VERSION ""

NS_ :

BS_:

BU_: L_3HKBD L_DIG L_FHPTC L_ATCU L_2HKBD L_PCM L_ATCU_vMON L_EVNT L_HKBD L_RHPTC

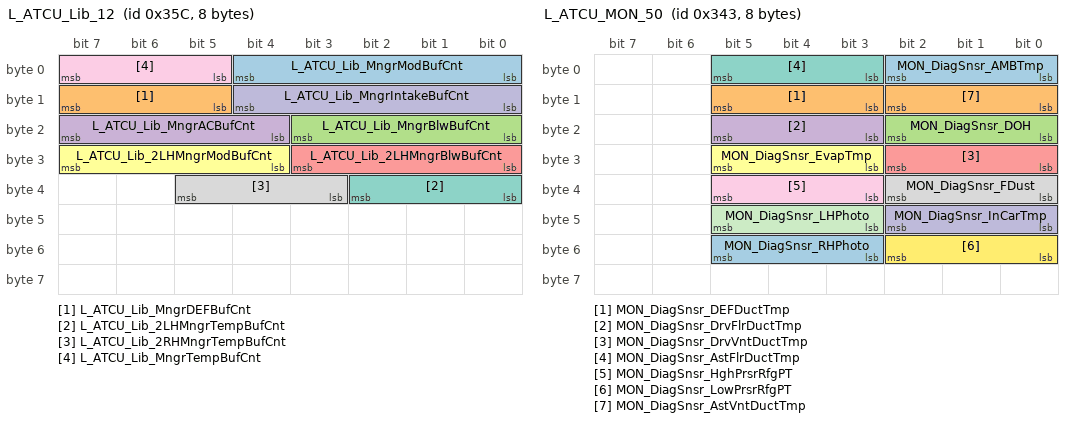
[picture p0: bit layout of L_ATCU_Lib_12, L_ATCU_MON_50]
BO_ 860 L_ATCU_Lib_12: 8 L_ATCU
 SG_ L_ATCU_Lib_MngrModBufCnt : 0|5@1+ (1,0) [0|31] ""  L_ATCU_vMON
 SG_ L_ATCU_Lib_MngrDEFBufCnt : 13|3@1+ (1,0) [0|7] ""  L_ATCU_vMON
 SG_ L_ATCU_Lib_MngrBlwBufCnt : 16|4@1+ (1,0) [0|15] ""  L_ATCU_vMON
 SG_ L_ATCU_Lib_MngrACBufCnt : 20|4@1+ (1,0) [0|15] ""  L_ATCU_vMON
 SG_ L_ATCU_Lib_2LHMngrBlwBufCnt : 24|4@1+ (1,0) [0|15] ""  L_ATCU_vMON
 SG_ L_ATCU_Lib_2LHMngrModBufCnt : 28|4@1+ (1,0) [0|15] ""  L_ATCU_vMON
 SG_ L_ATCU_Lib_2LHMngrTempBufCnt : 32|3@1+ (1,0) [0|7] ""  L_ATCU_vMON
 SG_ L_ATCU_Lib_2RHMngrTempBufCnt : 35|3@1+ (1,0) [0|7] ""  L_ATCU_vMON
 SG_ L_ATCU_Lib_MngrTempBufCnt : 5|3@1+ (1,0) [0|7] ""  L_ATCU_vMON
 SG_ L_ATCU_Lib_MngrIntakeBufCnt : 8|5@1+ (1,0) [0|31] ""  L_ATCU_vMON

BO_ 834 L_ATCU_MON_49: 8 L_ATCU_vMON
 SG_ MON_DiagCOM_AcnOpPerm : 0|2@1+ (1,0) [0|0] ""  L_ATCU
 SG_ MON_DiagCOM_BMSTmout : 10|2@1+ (1,0) [0|0] ""  L_ATCU
 SG_ MON_DiagCOM_DrvClHtStOpt : 12|2@1+ (1,0) [0|0] ""  L_ATCU
 SG_ MON_DiagCOM_AstClHtStOpt : 14|2@1+ (1,0) [0|0] ""  L_ATCU
 SG_ MON_DiagCOM_EcoModSw : 16|2@1+ (1,0) [0|0] ""  L_ATCU
 SG_ MON_DiagCOM_EcompTmout : 18|2@1+ (1,0) [0|0] ""  L_ATCU
 SG_ MON_DiagCOM_APT : 2|2@1+ (1,0) [0|0] ""  L_ATCU
 SG_ MON_DiagCOM_EMSVehSpd : 20|2@1+ (1,0) [0|0] ""  L_ATCU
 SG_ MON_DiagCOM_EngCool : 22|2@1+ (1,0) [0|0] ""  L_ATCU
 SG_ MON_DiagCOM_EngOpMod : 24|2@1+ (1,0) [0|0] ""  L_ATCU
 SG_ MON_DiagCOM_HEVRdy : 26|2@1+ (1,0) [0|0] ""  L_ATCU
 SG_ MON_DiagCOM_HVPTCTmout : 28|2@1+ (1,0) [0|0] ""  L_ATCU
 SG_ MON_DiagCOM_LDCWatt : 30|2@1+ (1,0) [0|0] ""  L_ATCU
 SG_ MON_DiagCOM_LHPhoto : 32|2@1+ (1,0) [0|0] ""  L_ATCU
 SG_ MON_DiagCOM_MainRlyOnSta : 34|2@1+ (1,0) [0|0] ""  L_ATCU
 SG_ MON_DiagCOM_MCUTmout : 36|2@1+ (1,0) [0|0] ""  L_ATCU
 SG_ MON_DiagCOM_PMSnsr : 38|2@1+ (1,0) [0|0] ""  L_ATCU
 SG_ MON_DiagCOM_BatChlrEXVDiag : 4|2@1+ (1,0) [0|0] ""  L_ATCU
 SG_ MON_DiagCOM_PnlBusOff : 40|2@1+ (1,0) [0|0] ""  L_ATCU
 SG_ MON_DiagCOM_PTGOpt : 42|2@1+ (1,0) [0|0] ""  L_ATCU
 SG_ MON_DiagCOM_RHPhoto : 44|2@1+ (1,0) [0|0] ""  L_ATCU
 SG_ MON_DiagCOM_RPM : 46|2@1+ (1,0) [0|0] ""  L_ATCU
 SG_ MON_DiagCOM_SideMirAmb : 48|2@1+ (1,0) [0|0] ""  L_ATCU
 SG_ MON_DiagCOM_ServiceMod : 50|2@1+ (1,0) [0|0] ""  L_ATCU
 SG_ MON_DiagCOM_StrHtOpt : 52|2@1+ (1,0) [0|0] ""  L_ATCU
 SG_ MON_DiagCOM_TCUVehSpd : 54|2@1+ (1,0) [0|0] ""  L_ATCU
 SG_ MON_DiagCOM_Torque : 56|2@1+ (1,0) [0|0] ""  L_ATCU
 SG_ MON_DiagCOM_VehBusOff : 58|2@1+ (1,0) [0|0] ""  L_ATCU
 SG_ MON_DiagCOM_BATSoc : 6|2@1+ (1,0) [0|0] ""  L_ATCU
 SG_ MON_DiagCOM_WhlSpd : 60|2@1+ (1,0) [0|0] ""  L_ATCU
 SG_ MON_DiagCOM_ClmtBusOff : 62|2@1+ (1,0) [0|0] ""  L_ATCU
 SG_ MON_DiagCOM_BMSIntakeReq : 8|2@1+ (1,0) [0|0] ""  L_ATCU

BO_ 835 L_ATCU_MON_50: 8 L_ATCU_vMON
 SG_ MON_DiagSnsr_AMBTmp : 0|3@1+ (1,0) [0|0] ""  L_ATCU
 SG_ MON_DiagSnsr_DEFDuctTmp : 11|3@1+ (1,0) [0|0] ""  L_ATCU
 SG_ MON_DiagSnsr_DOH : 16|3@1+ (1,0) [0|0] ""  L_ATCU
 SG_ MON_DiagSnsr_DrvFlrDuctTmp : 19|3@1+ (1,0) [0|0] ""  L_ATCU
 SG_ MON_DiagSnsr_DrvVntDuctTmp : 24|3@1+ (1,0) [0|0] ""  L_ATCU
 SG_ MON_DiagSnsr_EvapTmp : 27|3@1+ (1,0) [0|0] ""  L_ATCU
 SG_ MON_DiagSnsr_AstFlrDuctTmp : 3|3@1+ (1,0) [0|0] ""  L_ATCU
 SG_ MON_DiagSnsr_FDust : 32|3@1+ (1,0) [0|0] ""  L_ATCU
 SG_ MON_DiagSnsr_HghPrsrRfgPT : 35|3@1+ (1,0) [0|0] ""  L_ATCU
 SG_ MON_DiagSnsr_InCarTmp : 40|3@1+ (1,0) [0|0] ""  L_ATCU
 SG_ MON_DiagSnsr_LHPhoto : 43|3@1+ (1,0) [0|0] ""  L_ATCU
 SG_ MON_DiagSnsr_LowPrsrRfgPT : 48|3@1+ (1,0) [0|0] ""  L_ATCU
 SG_ MON_DiagSnsr_RHPhoto : 51|3@1+ (1,0) [0|0] ""  L_ATCU
 SG_ MON_DiagSnsr_AstVntDuctTmp : 8|3@1+ (1,0) [0|0] ""  L_ATCU

BO_ 833 L_ATCU_MON_48: 8 L_ATCU_vMON
 SG_ MON_DiagAct_DrvModDrLck : 0|2@1+ (1,0) [0|0] ""  L_ATCU
 SG_ MON_DiagAct_AstModDrOpnSrt : 10|3@1+ (1,0) [0|0] ""  L_ATCU
 SG_ MON_DiagAct_AstTmpDrOpnSrt : 13|3@1+ (1,0) [0|0] ""  L_ATCU
 SG_ MON_DiagAct_DrvTmpDrLck : 16|2@1+ (1,0) [0|0] ""  L_ATCU
 SG_ MON_DiagAct_AstTmpDrLck : 18|2@1+ (1,0) [0|0] ""  L_ATCU
 SG_ MON_DiagAct_DrvModDrOpnSrt : 2|3@1+ (1,0) [0|0] ""  L_ATCU
 SG_ MON_DiagAct_DEFDrLck : 20|2@1+ (1,0) [0|0] ""  L_ATCU
 SG_ MON_DiagAct_IntakeDrLck : 22|2@1+ (1,0) [0|0] ""  L_ATCU
 SG_ MON_DiagAct_IntakeDrOpnSrt : 24|3@1+ (1,0) [0|0] ""  L_ATCU
 SG_ MON_DiagAct_DEFDrOpnSrt : 27|3@1+ (1,0) [0|0] ""  L_ATCU
 SG_ MON_DiagAct_ECompIntlck : 30|2@1+ (1,0) [0|0] ""  L_ATCU
 SG_ MON_DiagAct_HVPTCIntlck : 32|2@1+ (1,0) [0|0] ""  L_ATCU
 SG_ MON_DiagAct_BatChlrEXVOpnSrt : 34|3@1+ (1,0) [0|0] ""  L_ATCU
 SG_ MON_DiagAct_EvapTXVOpnSrt : 37|3@1+ (1,0) [0|0] ""  L_ATCU
 SG_ MON_DiagAct_FrtPWMBlr : 40|4@1+ (1,0) [0|0] ""  L_ATCU
 SG_ MON_DiagAct_ECV : 44|3@1+ (1,0) [0|0] ""  L_ATCU
 SG_ MON_DiagAct_Rfgrant : 48|3@1+ (1,0) [0|0] ""  L_ATCU
 SG_ MON_DiagAct_DrvTmpDrOpnSrt : 5|3@1+ (1,0) [0|0] ""  L_ATCU
 SG_ MON_DiagAct_VRLed : 52|3@1+ (1,0) [0|0] ""  L_ATCU
 SG_ MON_DiagAct_AstModDrLck : 8|2@1+ (1,0) [0|0] ""  L_ATCU

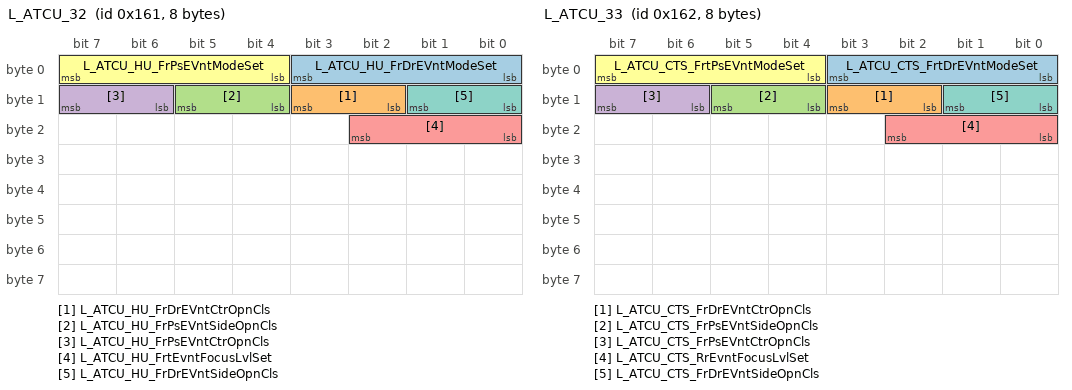
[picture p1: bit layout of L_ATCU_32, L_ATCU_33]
BO_ 353 L_ATCU_32: 8 L_ATCU
 SG_ L_ATCU_HU_FrDrEVntModeSet : 0|4@1+ (1,0) [0|0] ""  L_EVNT
 SG_ L_ATCU_HU_FrDrEVntCtrOpnCls : 10|2@1+ (1,0) [0|0] ""  L_EVNT
 SG_ L_ATCU_HU_FrPsEVntSideOpnCls : 12|2@1+ (1,0) [0|0] ""  L_EVNT
 SG_ L_ATCU_HU_FrPsEVntCtrOpnCls : 14|2@1+ (1,0) [0|0] ""  L_EVNT
 SG_ L_ATCU_HU_FrtEvntFocusLvlSet : 16|3@1+ (1,0) [0|0] ""  L_EVNT
 SG_ L_ATCU_HU_FrPsEVntModeSet : 4|4@1+ (1,0) [0|0] ""  L_EVNT
 SG_ L_ATCU_HU_FrDrEVntSideOpnCls : 8|2@1+ (1,0) [0|0] ""  L_EVNT

BO_ 354 L_ATCU_33: 8 L_ATCU
 SG_ L_ATCU_CTS_FrtDrEVntModeSet : 0|4@1+ (1,0) [0|0] ""  L_EVNT
 SG_ L_ATCU_CTS_FrDrEVntCtrOpnCls : 10|2@1+ (1,0) [0|0] ""  L_EVNT
 SG_ L_ATCU_CTS_FrPsEVntSideOpnCls : 12|2@1+ (1,0) [0|0] ""  L_EVNT
 SG_ L_ATCU_CTS_FrPsEVntCtrOpnCls : 14|2@1+ (1,0) [0|0] ""  L_EVNT
 SG_ L_ATCU_CTS_RrEvntFocusLvlSet : 16|3@1+ (1,0) [0|0] ""  L_EVNT
 SG_ L_ATCU_CTS_FrtPsEVntModeSet : 4|4@1+ (1,0) [0|0] ""  L_EVNT
 SG_ L_ATCU_CTS_FrDrEVntSideOpnCls : 8|2@1+ (1,0) [0|0] ""  L_EVNT

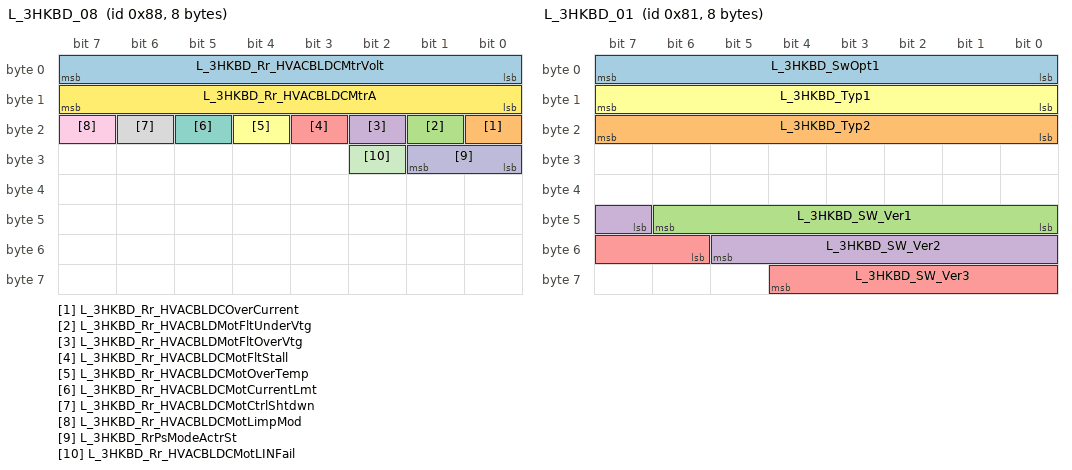
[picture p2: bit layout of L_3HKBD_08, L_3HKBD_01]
BO_ 136 L_3HKBD_08: 8 L_3HKBD
 SG_ L_3HKBD_Rr_HVACBLDCMtrVolt : 0|8@1+ (0.1,0) [0|0] "V"  L_ATCU
 SG_ L_3HKBD_Rr_HVACBLDCOverCurrent : 16|1@1+ (1,0) [0|0] ""  L_ATCU
 SG_ L_3HKBD_Rr_HVACBLDMotFltUnderVtg : 17|1@1+ (1,0) [0|0] ""  L_ATCU
 SG_ L_3HKBD_Rr_HVACBLDMotFltOverVtg : 18|1@1+ (1,0) [0|0] ""  L_ATCU
 SG_ L_3HKBD_Rr_HVACBLDCMotFltStall : 19|1@1+ (1,0) [0|0] ""  L_ATCU
 SG_ L_3HKBD_Rr_HVACBLDCMotOverTemp : 20|1@1+ (1,0) [0|0] ""  L_ATCU
 SG_ L_3HKBD_Rr_HVACBLDCMotCurrentLmt : 21|1@1+ (1,0) [0|0] ""  L_ATCU
 SG_ L_3HKBD_Rr_HVACBLDCMotCtrlShtdwn : 22|1@1+ (1,0) [0|0] ""  L_ATCU
 SG_ L_3HKBD_Rr_HVACBLDCMotLimpMod : 23|1@1+ (1,0) [0|0] ""  L_ATCU
 SG_ L_3HKBD_RrPsModeActrSt : 24|2@1+ (1,0) [0|0] ""  L_ATCU
 SG_ L_3HKBD_Rr_HVACBLDCMotLINFail : 26|1@1+ (1,0) [0|0] ""  L_ATCU
 SG_ L_3HKBD_Rr_HVACBLDCMtrA : 8|8@1+ (0.2,0) [0|0] "A"  L_ATCU

BO_ 129 L_3HKBD_01: 8 L_3HKBD
 SG_ L_3HKBD_SwOpt1 : 0|8@1+ (1,1) [0|0] ""  L_ATCU
 SG_ L_3HKBD_Typ2 : 16|8@1+ (1,0) [0|0] ""  L_ATCU
 SG_ L_3HKBD_SW_Ver1 : 40|7@1+ (1,0) [0|0] ""  L_ATCU_vMON
 SG_ L_3HKBD_SW_Ver2 : 47|7@1+ (1,0) [0|0] ""  L_ATCU_vMON
 SG_ L_3HKBD_SW_Ver3 : 54|7@1+ (1,0) [0|0] ""  L_ATCU_vMON
 SG_ L_3HKBD_Typ1 : 8|8@1+ (1,0) [0|0] ""  L_ATCU

BO_ 131 L_3HKBD_03: 8 L_3HKBD
 SG_ L_3HKBD_SwBtnTyp : 0|40@1+ (1,0) [0|0] ""  L_ATCU
 SG_ L_3HKBD_ResetOpSta : 62|2@1+ (1,0) [0|0] ""  L_ATCU

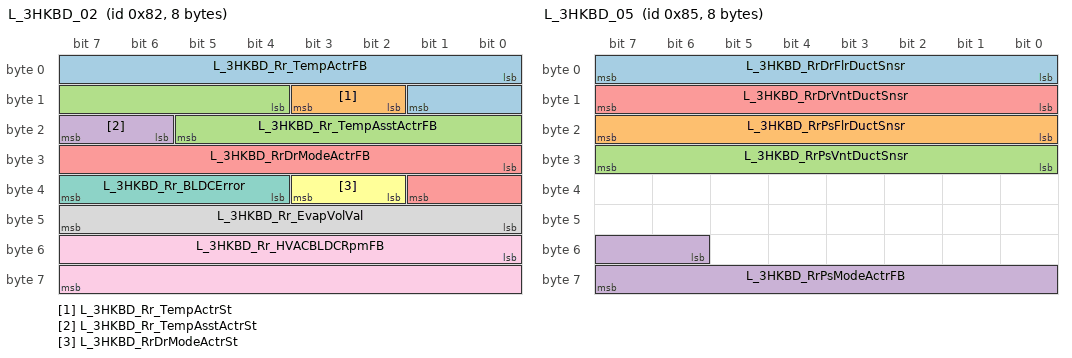
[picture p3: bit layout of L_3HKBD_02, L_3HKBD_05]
BO_ 130 L_3HKBD_02: 8 L_3HKBD
 SG_ L_3HKBD_Rr_TempActrFB : 0|10@1+ (1,0) [0|0] "AD"  L_ATCU
 SG_ L_3HKBD_Rr_TempActrSt : 10|2@1+ (1,0) [0|0] ""  L_ATCU
 SG_ L_3HKBD_Rr_TempAsstActrFB : 12|10@1+ (1,0) [0|0] "AD"  L_ATCU
 SG_ L_3HKBD_Rr_TempAsstActrSt : 22|2@1+ (1,0) [0|0] ""  L_ATCU
 SG_ L_3HKBD_RrDrModeActrFB : 24|10@1+ (1,0) [0|0] "AD"  L_ATCU
 SG_ L_3HKBD_RrDrModeActrSt : 34|2@1+ (1,0) [0|0] ""  L_ATCU
 SG_ L_3HKBD_Rr_BLDCError : 36|4@1+ (1,0) [0|0] ""  L_ATCU
 SG_ L_3HKBD_Rr_EvapVolVal : 40|8@1+ (0.02,0) [0|0] "V"  L_ATCU
 SG_ L_3HKBD_Rr_HVACBLDCRpmFB : 48|16@1+ (5,0) [0|0] "RPM"  L_ATCU

BO_ 133 L_3HKBD_05: 8 L_3HKBD
 SG_ L_3HKBD_RrDrFlrDuctSnsr : 0|8@1+ (0.02,0) [0|0] "V"  L_ATCU
 SG_ L_3HKBD_RrPsFlrDuctSnsr : 16|8@1+ (0.02,0) [0|0] ""  L_ATCU
 SG_ L_3HKBD_RrPsVntDuctSnsr : 24|8@1+ (0.02,0) [0|0] ""  L_ATCU
 SG_ L_3HKBD_RrPsModeActrFB : 54|10@1+ (1,0) [0|0] ""  L_ATCU
 SG_ L_3HKBD_RrDrVntDuctSnsr : 8|8@1+ (0.02,0) [0|0] "V"  L_ATCU

BO_ 132 L_3HKBD_04: 8 L_3HKBD
 SG_ L_3HKBD_RrTempDnSw : 0|1@1+ (1,1) [0|0] ""  L_ATCU
 SG_ L_3HKBD_RrTempUpSw : 1|1@1+ (1,1) [0|0] ""  L_ATCU
 SG_ L_3HKBD_RrAutoSw : 10|1@1+ (1,0) [0|0] ""  L_ATCU
 SG_ L_3HKBD_RrOffSw : 11|1@1+ (1,0) [0|0] ""  L_ATCU
 SG_ L_3HKBD_RrSyncSw : 12|1@1+ (1,0) [0|0] ""  L_ATCU
 SG_ L_3HKBD_RLStHtrSwReq : 13|1@1+ (1,0) [0|0] ""  L_ATCU
 SG_ L_3HKBD_RLStVentSwReq : 14|1@1+ (1,0) [0|0] ""  L_ATCU
 SG_ L_3HKBD_RRStHtrSwReq : 15|1@1+ (1,0) [0|0] ""  L_ATCU
 SG_ L_3HKBD_RRStVentSwReq : 16|1@1+ (1,0) [0|0] ""  L_ATCU
 SG_ L_3HKBD_RrBlwDnOffSw : 17|1@1+ (1,0) [0|0] ""  L_ATCU
 SG_ L_3HKBD_RrOnOffSet : 18|2@1+ (1,0) [0|0] ""  L_ATCU
 SG_ L_3HKBD_RrBlwDnSw : 2|1@1+ (1,0) [0|0] ""  L_ATCU
 SG_ L_3HKBD_RrblwUpMaxSw : 20|1@1+ (1,0) [0|0] ""  L_ATCU
 SG_ L_3HKBD_RrBlwUpSw : 3|1@1+ (1,0) [0|0] ""  L_ATCU
 SG_ L_3HKBD_RrModeDnSw : 4|1@1+ (1,0) [0|0] ""  L_ATCU
 SG_ L_3HKBD_RrModeUpSw : 5|1@1+ (1,0) [0|0] ""  L_ATCU
 SG_ L_3HKBD_RrModeSw : 6|1@1+ (1,0) [0|0] ""  L_ATCU
 SG_ L_3HKBD_RrModeVentSw : 7|1@1+ (1,0) [0|0] ""  L_ATCU
 SG_ L_3HKBD_RrModeFloorSw : 8|1@1+ (1,0) [0|0] ""  L_ATCU
 SG_ L_3HKBD_RrModeBiLvlSw : 9|1@1+ (1,0) [0|0] ""  L_ATCU

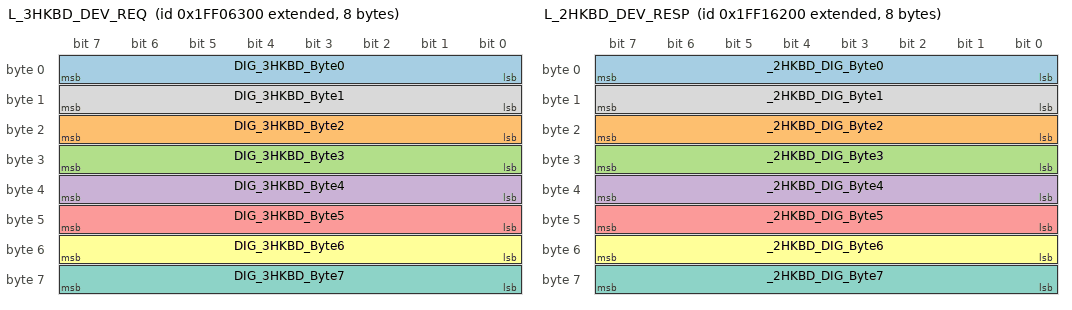
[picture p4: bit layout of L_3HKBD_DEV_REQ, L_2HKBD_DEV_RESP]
BO_ 2683331328 L_3HKBD_DEV_REQ: 8 L_DIG
 SG_ DIG_3HKBD_Byte0 : 0|8@1+ (1,0) [0|0] ""  L_3HKBD
 SG_ DIG_3HKBD_Byte2 : 16|8@1+ (1,0) [0|0] ""  L_3HKBD
 SG_ DIG_3HKBD_Byte3 : 24|8@1+ (1,0) [0|0] ""  L_3HKBD
 SG_ DIG_3HKBD_Byte4 : 32|8@1+ (1,0) [0|0] ""  L_3HKBD
 SG_ DIG_3HKBD_Byte5 : 40|8@1+ (1,0) [0|0] ""  L_3HKBD
 SG_ DIG_3HKBD_Byte6 : 48|8@1+ (1,0) [0|0] ""  L_3HKBD
 SG_ DIG_3HKBD_Byte7 : 56|8@1+ (1,0) [0|0] ""  L_3HKBD
 SG_ DIG_3HKBD_Byte1 : 8|8@1+ (1,0) [0|0] ""  L_3HKBD

BO_ 2683396608 L_2HKBD_DEV_RESP: 8 L_2HKBD
 SG_ _2HKBD_DIG_Byte0 : 0|8@1+ (1,0) [0|0] ""  L_DIG
 SG_ _2HKBD_DIG_Byte2 : 16|8@1+ (1,0) [0|0] ""  L_DIG
 SG_ _2HKBD_DIG_Byte3 : 24|8@1+ (1,0) [0|0] ""  L_DIG
 SG_ _2HKBD_DIG_Byte4 : 32|8@1+ (1,0) [0|0] ""  L_DIG
 SG_ _2HKBD_DIG_Byte5 : 40|8@1+ (1,0) [0|0] ""  L_DIG
 SG_ _2HKBD_DIG_Byte6 : 48|8@1+ (1,0) [0|0] ""  L_DIG
 SG_ _2HKBD_DIG_Byte7 : 56|8@1+ (1,0) [0|0] ""  L_DIG
 SG_ _2HKBD_DIG_Byte1 : 8|8@1+ (1,0) [0|0] ""  L_DIG

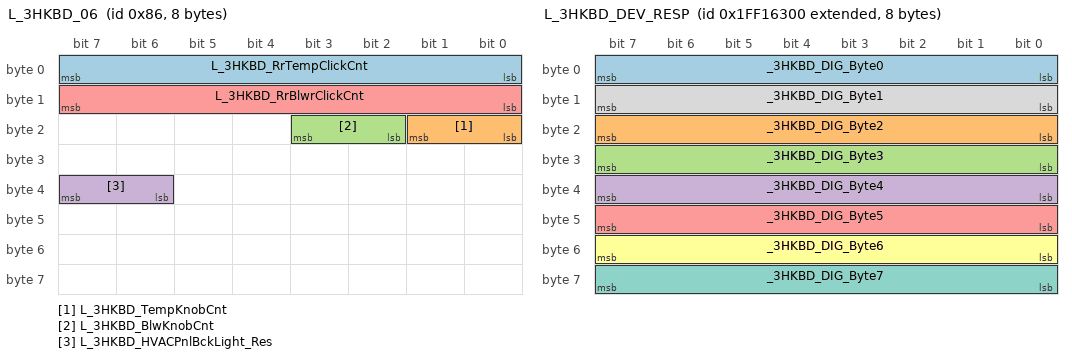
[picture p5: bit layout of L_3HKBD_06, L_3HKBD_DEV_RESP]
BO_ 134 L_3HKBD_06: 8 L_3HKBD
 SG_ L_3HKBD_RrTempClickCnt : 0|8@1+ (1,1) [0|0] ""  L_ATCU
 SG_ L_3HKBD_TempKnobCnt : 16|2@1+ (1,1) [0|0] ""  L_ATCU
 SG_ L_3HKBD_BlwKnobCnt : 18|2@1+ (1,1) [0|0] ""  L_ATCU
 SG_ L_3HKBD_HVACPnlBckLight_Res : 38|2@1+ (1,0) [0|0] ""  L_ATCU
 SG_ L_3HKBD_RrBlwrClickCnt : 8|8@1+ (1,1) [0|0] ""  L_ATCU

BO_ 2683396864 L_3HKBD_DEV_RESP: 8 L_3HKBD
 SG_ _3HKBD_DIG_Byte0 : 0|8@1+ (1,0) [0|0] ""  L_DIG
 SG_ _3HKBD_DIG_Byte2 : 16|8@1+ (1,0) [0|0] ""  L_DIG
 SG_ _3HKBD_DIG_Byte3 : 24|8@1+ (1,0) [0|0] ""  L_DIG
 SG_ _3HKBD_DIG_Byte4 : 32|8@1+ (1,0) [0|0] ""  L_DIG
 SG_ _3HKBD_DIG_Byte5 : 40|8@1+ (1,0) [0|0] ""  L_DIG
 SG_ _3HKBD_DIG_Byte6 : 48|8@1+ (1,0) [0|0] ""  L_DIG
 SG_ _3HKBD_DIG_Byte7 : 56|8@1+ (1,0) [0|0] ""  L_DIG
 SG_ _3HKBD_DIG_Byte1 : 8|8@1+ (1,0) [0|0] ""  L_DIG

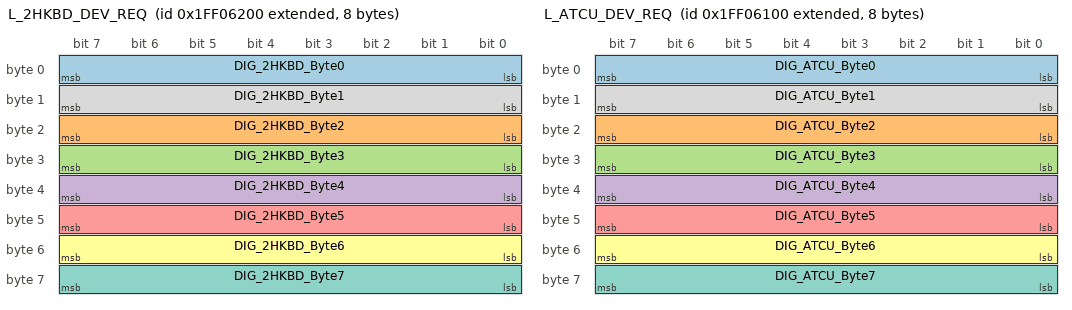
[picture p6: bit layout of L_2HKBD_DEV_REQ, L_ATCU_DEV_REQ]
BO_ 2683331072 L_2HKBD_DEV_REQ: 8 L_DIG
 SG_ DIG_2HKBD_Byte0 : 0|8@1+ (1,0) [0|0] ""  L_2HKBD
 SG_ DIG_2HKBD_Byte2 : 16|8@1+ (1,0) [0|0] ""  L_2HKBD
 SG_ DIG_2HKBD_Byte3 : 24|8@1+ (1,0) [0|0] ""  L_2HKBD
 SG_ DIG_2HKBD_Byte4 : 32|8@1+ (1,0) [0|0] ""  L_2HKBD
 SG_ DIG_2HKBD_Byte5 : 40|8@1+ (1,0) [0|0] ""  L_2HKBD
 SG_ DIG_2HKBD_Byte6 : 48|8@1+ (1,0) [0|0] ""  L_2HKBD
 SG_ DIG_2HKBD_Byte7 : 56|8@1+ (1,0) [0|0] ""  L_2HKBD
 SG_ DIG_2HKBD_Byte1 : 8|8@1+ (1,0) [0|0] ""  L_2HKBD

BO_ 2683330816 L_ATCU_DEV_REQ: 8 L_DIG
 SG_ DIG_ATCU_Byte0 : 0|8@1+ (1,0) [0|0] ""  L_ATCU
 SG_ DIG_ATCU_Byte2 : 16|8@1+ (1,0) [0|0] ""  L_ATCU
 SG_ DIG_ATCU_Byte3 : 24|8@1+ (1,0) [0|0] ""  L_ATCU
 SG_ DIG_ATCU_Byte4 : 32|8@1+ (1,0) [0|0] ""  L_ATCU
 SG_ DIG_ATCU_Byte5 : 40|8@1+ (1,0) [0|0] ""  L_ATCU
 SG_ DIG_ATCU_Byte6 : 48|8@1+ (1,0) [0|0] ""  L_ATCU
 SG_ DIG_ATCU_Byte7 : 56|8@1+ (1,0) [0|0] ""  L_ATCU
 SG_ DIG_ATCU_Byte1 : 8|8@1+ (1,0) [0|0] ""  L_ATCU

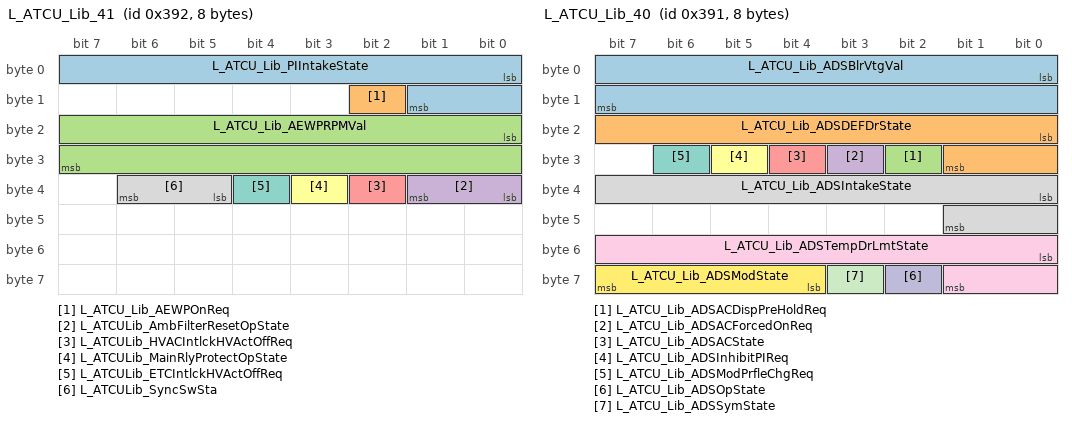
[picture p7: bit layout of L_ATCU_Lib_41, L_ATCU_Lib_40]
BO_ 914 L_ATCU_Lib_41: 8 L_ATCU
 SG_ L_ATCU_Lib_PIIntakeState : 0|10@1+ (1,0) [0|1023] ""  L_ATCU_vMON
 SG_ L_ATCU_Lib_AEWPOnReq : 10|1@1+ (1,0) [0|1] ""  L_ATCU_vMON
 SG_ L_ATCU_Lib_AEWPRPMVal : 16|16@1+ (1,0) [0|65535] ""  L_ATCU_vMON
 SG_ L_ATCULib_AmbFilterResetOpState : 32|2@1+ (1,0) [0|0] ""  L_ATCU_vMON
 SG_ L_ATCULib_HVACIntlckHVActOffReq : 34|1@1+ (1,0) [0|0] ""  L_ATCU_vMON
 SG_ L_ATCULib_MainRlyProtectOpState : 35|1@1+ (1,0) [0|0] ""  L_ATCU_vMON
 SG_ L_ATCULib_ETCIntlckHVActOffReq : 36|1@1+ (1,0) [0|0] ""  L_ATCU_vMON
 SG_ L_ATCULib_SyncSwSta : 37|2@1+ (1,0) [0|0] ""  L_ATCU_vMON

BO_ 913 L_ATCU_Lib_40: 8 L_ATCU
 SG_ L_ATCU_Lib_ADSBlrVtgVal : 0|16@1+ (1,0) [0|65535] ""  L_ATCU_vMON
 SG_ L_ATCU_Lib_ADSDEFDrState : 16|10@1+ (1,0) [0|1023] ""  L_ATCU_vMON
 SG_ L_ATCU_Lib_ADSACDispPreHoldReq : 26|1@1+ (1,0) [0|1] ""  L_ATCU_vMON
 SG_ L_ATCU_Lib_ADSACForcedOnReq : 27|1@1+ (1,0) [0|1] ""  L_ATCU_vMON
 SG_ L_ATCU_Lib_ADSACState : 28|1@1+ (1,0) [0|1] ""  L_ATCU_vMON
 SG_ L_ATCU_Lib_ADSInhibitPIReq : 29|1@1+ (1,0) [0|1] ""  L_ATCU_vMON
 SG_ L_ATCU_Lib_ADSModPrfleChgReq : 30|1@1+ (1,0) [0|1] ""  L_ATCU_vMON
 SG_ L_ATCU_Lib_ADSIntakeState : 32|10@1+ (1,0) [0|1023] ""  L_ATCU_vMON
 SG_ L_ATCU_Lib_ADSTempDrLmtState : 48|10@1+ (1,0) [0|1023] ""  L_ATCU_vMON
 SG_ L_ATCU_Lib_ADSOpState : 58|1@1+ (1,0) [0|1] ""  L_ATCU_vMON
 SG_ L_ATCU_Lib_ADSSymState : 59|1@1+ (1,0) [0|1] ""  L_ATCU_vMON
 SG_ L_ATCU_Lib_ADSModState : 60|4@1+ (1,0) [0|0] ""  L_ATCU_vMON

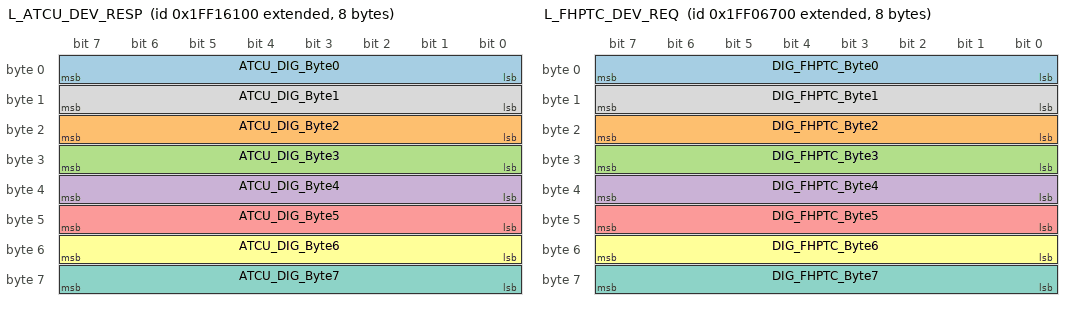
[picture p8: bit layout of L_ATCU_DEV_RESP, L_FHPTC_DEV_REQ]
BO_ 2683396352 L_ATCU_DEV_RESP: 8 L_ATCU
 SG_ ATCU_DIG_Byte0 : 0|8@1+ (1,0) [0|0] ""  L_DIG
 SG_ ATCU_DIG_Byte2 : 16|8@1+ (1,0) [0|0] ""  L_DIG
 SG_ ATCU_DIG_Byte3 : 24|8@1+ (1,0) [0|0] ""  L_DIG
 SG_ ATCU_DIG_Byte4 : 32|8@1+ (1,0) [0|0] ""  L_DIG
 SG_ ATCU_DIG_Byte5 : 40|8@1+ (1,0) [0|0] ""  L_DIG
 SG_ ATCU_DIG_Byte6 : 48|8@1+ (1,0) [0|0] ""  L_DIG
 SG_ ATCU_DIG_Byte7 : 56|8@1+ (1,0) [0|0] ""  L_DIG
 SG_ ATCU_DIG_Byte1 : 8|8@1+ (1,0) [0|0] ""  L_DIG

BO_ 2683332352 L_FHPTC_DEV_REQ: 8 L_DIG
 SG_ DIG_FHPTC_Byte0 : 0|8@1+ (1,0) [0|0] ""  L_FHPTC
 SG_ DIG_FHPTC_Byte2 : 16|8@1+ (1,0) [0|0] ""  L_FHPTC
 SG_ DIG_FHPTC_Byte3 : 24|8@1+ (1,0) [0|0] ""  L_FHPTC
 SG_ DIG_FHPTC_Byte4 : 32|8@1+ (1,0) [0|0] ""  L_FHPTC
 SG_ DIG_FHPTC_Byte5 : 40|8@1+ (1,0) [0|0] ""  L_FHPTC
 SG_ DIG_FHPTC_Byte6 : 48|8@1+ (1,0) [0|0] ""  L_FHPTC
 SG_ DIG_FHPTC_Byte7 : 56|8@1+ (1,0) [0|0] ""  L_FHPTC
 SG_ DIG_FHPTC_Byte1 : 8|8@1+ (1,0) [0|0] ""  L_FHPTC

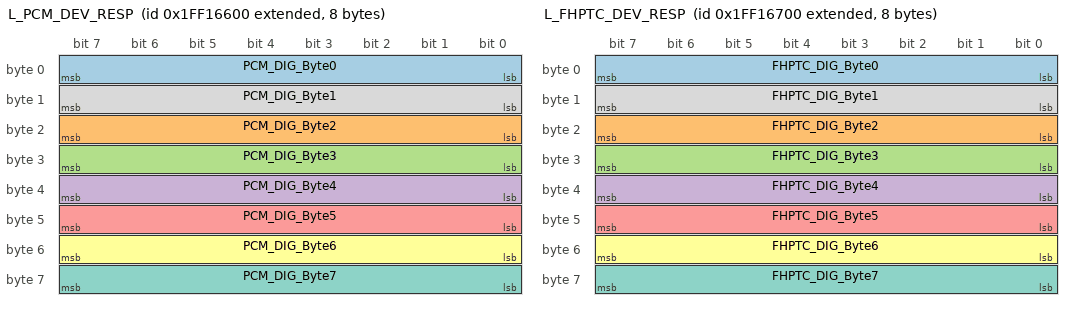
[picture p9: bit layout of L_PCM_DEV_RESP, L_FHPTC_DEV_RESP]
BO_ 2683397632 L_PCM_DEV_RESP: 8 L_PCM
 SG_ PCM_DIG_Byte0 : 0|8@1+ (1,0) [0|0] ""  L_DIG
 SG_ PCM_DIG_Byte2 : 16|8@1+ (1,0) [0|0] ""  L_DIG
 SG_ PCM_DIG_Byte3 : 24|8@1+ (1,0) [0|0] ""  L_DIG
 SG_ PCM_DIG_Byte4 : 32|8@1+ (1,0) [0|0] ""  L_DIG
 SG_ PCM_DIG_Byte5 : 40|8@1+ (1,0) [0|0] ""  L_DIG
 SG_ PCM_DIG_Byte6 : 48|8@1+ (1,0) [0|0] ""  L_DIG
 SG_ PCM_DIG_Byte7 : 56|8@1+ (1,0) [0|0] ""  L_DIG
 SG_ PCM_DIG_Byte1 : 8|8@1+ (1,0) [0|0] ""  L_DIG

BO_ 2683397888 L_FHPTC_DEV_RESP: 8 L_FHPTC
 SG_ FHPTC_DIG_Byte0 : 0|8@1+ (1,0) [0|0] ""  L_DIG
 SG_ FHPTC_DIG_Byte2 : 16|8@1+ (1,0) [0|0] ""  L_DIG
 SG_ FHPTC_DIG_Byte3 : 24|8@1+ (1,0) [0|0] ""  L_DIG
 SG_ FHPTC_DIG_Byte4 : 32|8@1+ (1,0) [0|0] ""  L_DIG
 SG_ FHPTC_DIG_Byte5 : 40|8@1+ (1,0) [0|0] ""  L_DIG
 SG_ FHPTC_DIG_Byte6 : 48|8@1+ (1,0) [0|0] ""  L_DIG
 SG_ FHPTC_DIG_Byte7 : 56|8@1+ (1,0) [0|0] ""  L_DIG
 SG_ FHPTC_DIG_Byte1 : 8|8@1+ (1,0) [0|0] ""  L_DIG

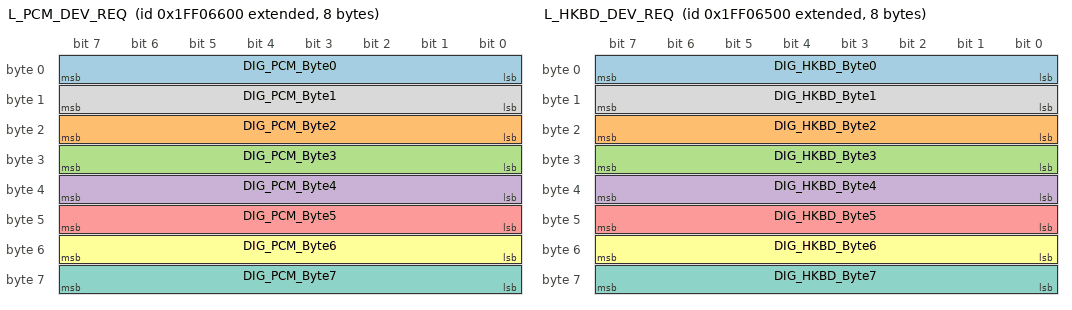
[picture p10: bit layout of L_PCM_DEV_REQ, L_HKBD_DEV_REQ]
BO_ 2683332096 L_PCM_DEV_REQ: 8 L_DIG
 SG_ DIG_PCM_Byte0 : 0|8@1+ (1,0) [0|0] ""  L_PCM
 SG_ DIG_PCM_Byte2 : 16|8@1+ (1,0) [0|0] ""  L_PCM
 SG_ DIG_PCM_Byte3 : 24|8@1+ (1,0) [0|0] ""  L_PCM
 SG_ DIG_PCM_Byte4 : 32|8@1+ (1,0) [0|0] ""  L_PCM
 SG_ DIG_PCM_Byte5 : 40|8@1+ (1,0) [0|0] ""  L_PCM
 SG_ DIG_PCM_Byte6 : 48|8@1+ (1,0) [0|0] ""  L_PCM
 SG_ DIG_PCM_Byte7 : 56|8@1+ (1,0) [0|0] ""  L_PCM
 SG_ DIG_PCM_Byte1 : 8|8@1+ (1,0) [0|0] ""  L_PCM

BO_ 2683331840 L_HKBD_DEV_REQ: 8 L_DIG
 SG_ DIG_HKBD_Byte0 : 0|8@1+ (1,0) [0|0] ""  L_HKBD
 SG_ DIG_HKBD_Byte2 : 16|8@1+ (1,0) [0|0] ""  L_HKBD
 SG_ DIG_HKBD_Byte3 : 24|8@1+ (1,0) [0|0] ""  L_HKBD
 SG_ DIG_HKBD_Byte4 : 32|8@1+ (1,0) [0|0] ""  L_HKBD
 SG_ DIG_HKBD_Byte5 : 40|8@1+ (1,0) [0|0] ""  L_HKBD
 SG_ DIG_HKBD_Byte6 : 48|8@1+ (1,0) [0|0] ""  L_HKBD
 SG_ DIG_HKBD_Byte7 : 56|8@1+ (1,0) [0|0] ""  L_HKBD
 SG_ DIG_HKBD_Byte1 : 8|8@1+ (1,0) [0|0] ""  L_HKBD

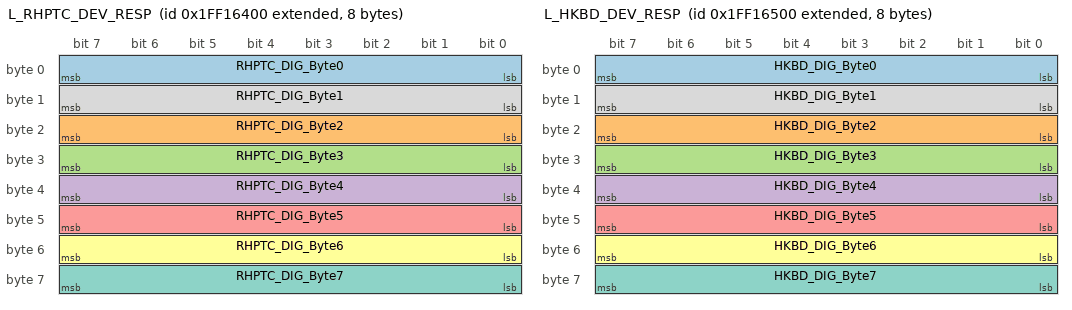
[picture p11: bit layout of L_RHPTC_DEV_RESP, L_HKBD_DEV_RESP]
BO_ 2683397120 L_RHPTC_DEV_RESP: 8 L_RHPTC
 SG_ RHPTC_DIG_Byte0 : 0|8@1+ (1,0) [0|0] ""  L_DIG
 SG_ RHPTC_DIG_Byte2 : 16|8@1+ (1,0) [0|0] ""  L_DIG
 SG_ RHPTC_DIG_Byte3 : 24|8@1+ (1,0) [0|0] ""  L_DIG
 SG_ RHPTC_DIG_Byte4 : 32|8@1+ (1,0) [0|0] ""  L_DIG
 SG_ RHPTC_DIG_Byte5 : 40|8@1+ (1,0) [0|0] ""  L_DIG
 SG_ RHPTC_DIG_Byte6 : 48|8@1+ (1,0) [0|0] ""  L_DIG
 SG_ RHPTC_DIG_Byte7 : 56|8@1+ (1,0) [0|0] ""  L_DIG
 SG_ RHPTC_DIG_Byte1 : 8|8@1+ (1,0) [0|0] ""  L_DIG

BO_ 2683397376 L_HKBD_DEV_RESP: 8 L_HKBD
 SG_ HKBD_DIG_Byte0 : 0|8@1+ (1,0) [0|0] ""  L_DIG
 SG_ HKBD_DIG_Byte2 : 16|8@1+ (1,0) [0|0] ""  L_DIG
 SG_ HKBD_DIG_Byte3 : 24|8@1+ (1,0) [0|0] ""  L_DIG
 SG_ HKBD_DIG_Byte4 : 32|8@1+ (1,0) [0|0] ""  L_DIG
 SG_ HKBD_DIG_Byte5 : 40|8@1+ (1,0) [0|0] ""  L_DIG
 SG_ HKBD_DIG_Byte6 : 48|8@1+ (1,0) [0|0] ""  L_DIG
 SG_ HKBD_DIG_Byte7 : 56|8@1+ (1,0) [0|0] ""  L_DIG
 SG_ HKBD_DIG_Byte1 : 8|8@1+ (1,0) [0|0] ""  L_DIG

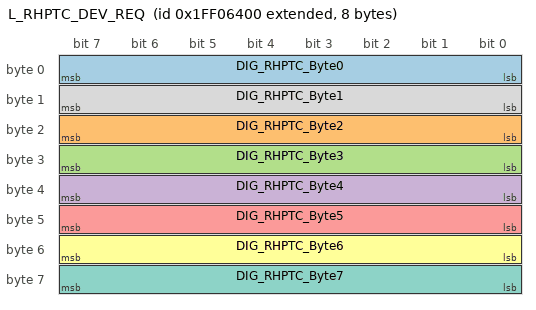
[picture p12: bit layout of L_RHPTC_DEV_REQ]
BO_ 2683331584 L_RHPTC_DEV_REQ: 8 L_DIG
 SG_ DIG_RHPTC_Byte0 : 0|8@1+ (1,0) [0|0] ""  L_RHPTC
 SG_ DIG_RHPTC_Byte2 : 16|8@1+ (1,0) [0|0] ""  L_RHPTC
 SG_ DIG_RHPTC_Byte3 : 24|8@1+ (1,0) [0|0] ""  L_RHPTC
 SG_ DIG_RHPTC_Byte4 : 32|8@1+ (1,0) [0|0] ""  L_RHPTC
 SG_ DIG_RHPTC_Byte5 : 40|8@1+ (1,0) [0|0] ""  L_RHPTC
 SG_ DIG_RHPTC_Byte6 : 48|8@1+ (1,0) [0|0] ""  L_RHPTC
 SG_ DIG_RHPTC_Byte7 : 56|8@1+ (1,0) [0|0] ""  L_RHPTC
 SG_ DIG_RHPTC_Byte1 : 8|8@1+ (1,0) [0|0] ""  L_RHPTC

CM_ BO_ 2683331072 "[EW] On Event and On Write";
CM_ BO_ 2683396608 "[EW] On Event and On Write";
CM_ BO_ 129 "[PE] Periodic and On Event";
CM_ SG_ 129 L_3HKBD_SwOpt1 "3HKBD_SwitchOption1";
CM_ SG_ 129 L_3HKBD_Typ2 "3HKBD_Type2";
CM_ SG_ 129 L_3HKBD_SW_Ver1 "3HKBD_SoftWare_Version1";
CM_ SG_ 129 L_3HKBD_SW_Ver2 "3HKBD_SoftWare_Version2";
CM_ SG_ 129 L_3HKBD_SW_Ver3 "3HKBD_SoftWare_Version3";
CM_ SG_ 129 L_3HKBD_Typ1 "3HKBD_Type1";
CM_ BO_ 130 "[P] Periodic";
CM_ SG_ 130 L_3HKBD_Rr_TempActrFB "3HKBD_Rear_TempActuatorFeedback";
CM_ SG_ 130 L_3HKBD_Rr_TempActrSt "3HKBD_Rear_TempActuatorStatus";
CM_ SG_ 130 L_3HKBD_Rr_TempAsstActrFB "3HKBD_Rear_TempAssistActuatorFeedback";
CM_ SG_ 130 L_3HKBD_Rr_TempAsstActrSt "3HKBD_Rear_TempAssistActuatorStatus";
CM_ SG_ 130 L_3HKBD_RrDrModeActrFB "3HKBD_RearDriverModeActuatorFeedback";
CM_ SG_ 130 L_3HKBD_RrDrModeActrSt "3HKBD_RearDriverModeActuatorStatus";
CM_ SG_ 130 L_3HKBD_Rr_BLDCError "3HKBD_Rear_BLDCError";
CM_ SG_ 130 L_3HKBD_Rr_EvapVolVal "3HKBD_Rear_EvaporatorVoltageValue";
CM_ SG_ 130 L_3HKBD_Rr_HVACBLDCRpmFB "3HKBD_Rear_HVACBLDCRpmFeedBack";
CM_ BO_ 131 "[PE] Periodic and On Event";
CM_ SG_ 131 L_3HKBD_SwBtnTyp "3HKBD_SwitchButtonType";
CM_ SG_ 131 L_3HKBD_ResetOpSta "This signal indicates whether the reset operation has been completed or not";
CM_ BO_ 132 "[PE] Periodic and On Event";
CM_ SG_ 132 L_3HKBD_RrTempDnSw "3HKBD_RearTemperatureDownSwitch";
CM_ SG_ 132 L_3HKBD_RrTempUpSw "3HKBD_RearTemperatureUpSwitch";
CM_ SG_ 132 L_3HKBD_RrAutoSw "3HKBD_RearAutoSwitch";
CM_ SG_ 132 L_3HKBD_RrOffSw "3HKBD_RearOffSwitch";
CM_ SG_ 132 L_3HKBD_RrSyncSw "3HKBD_RearSyncSwitch";
CM_ SG_ 132 L_3HKBD_RLStHtrSwReq "3HKBD_RearLeftSeatHeaterSwitchRequest";
CM_ SG_ 132 L_3HKBD_RLStVentSwReq "3HKBD_RearLeftSeatVentSwitchRequest";
CM_ SG_ 132 L_3HKBD_RRStHtrSwReq "3HKBD_RearRightSeatHeaterSwitchRequest";
CM_ SG_ 132 L_3HKBD_RRStVentSwReq "3HKBD_RearRightSeatVentSwitchRequest";
CM_ SG_ 132 L_3HKBD_RrBlwDnOffSw "3HKBD_RearBlowerDownOffSwitch";
CM_ SG_ 132 L_3HKBD_RrOnOffSet "3HKBD_RearOnOffSet";
CM_ SG_ 132 L_3HKBD_RrBlwDnSw "3HKBD_RearBlowerDownSwitch";
CM_ SG_ 132 L_3HKBD_RrblwUpMaxSw "L_3HKBD_RrblwUpMaxSw";
CM_ SG_ 132 L_3HKBD_RrBlwUpSw "3HKBD_RearBlowerUpSwitch";
CM_ SG_ 132 L_3HKBD_RrModeDnSw "3HKBD_RearModeDownSwitch";
CM_ SG_ 132 L_3HKBD_RrModeUpSw "3HKBD_RearModeUpSwitch";
CM_ SG_ 132 L_3HKBD_RrModeSw "3HKBD_RearModeSwitch";
CM_ SG_ 132 L_3HKBD_RrModeVentSw "3HKBD_RearModeVentSwitch";
CM_ SG_ 132 L_3HKBD_RrModeFloorSw "3HKBD_RearModeFloorSwitch";
CM_ SG_ 132 L_3HKBD_RrModeBiLvlSw "3HKBD_RearModeBiLevelSwitch";
CM_ BO_ 133 "[PE] Periodic and On Event";
CM_ SG_ 133 L_3HKBD_RrDrFlrDuctSnsr "3HKBD_RearDriverFloorDuctSensor";
CM_ SG_ 133 L_3HKBD_RrPsFlrDuctSnsr "L_3HKBD_RearPassengerFloorDuctSensor";
CM_ SG_ 133 L_3HKBD_RrPsVntDuctSnsr "L_3HKBD_RearPassengerVentDuctSensor";
CM_ SG_ 133 L_3HKBD_RrPsModeActrFB "L_3HKBD_RearPassengerModeActuatorFeedback";
CM_ SG_ 133 L_3HKBD_RrDrVntDuctSnsr "3HKBD_RearDriverVentDuctSensor";
CM_ BO_ 134 "[EC] On Event and On Change";
CM_ SG_ 134 L_3HKBD_RrTempClickCnt "3HKBD_RearTemperatureClickCount";
CM_ SG_ 134 L_3HKBD_TempKnobCnt "3HKBD_TempKnobCount (for knobs rotate count)";
CM_ SG_ 134 L_3HKBD_BlwKnobCnt "3HKBD_BlowerKnobCount (for knobs rotate count)";
CM_ SG_ 134 L_3HKBD_HVACPnlBckLight_Res "Vehicle API HVAC Control Panel BackLight Response";
CM_ SG_ 134 L_3HKBD_RrBlwrClickCnt "3HKBD_RearBlowerClickCount";
CM_ BO_ 136 "[P] Periodic";
CM_ SG_ 136 L_3HKBD_Rr_HVACBLDCMtrVolt "3HKBD Rear HVAC BLDC Motor Voltage";
CM_ SG_ 136 L_3HKBD_Rr_HVACBLDCOverCurrent "3HKBD Rear HVAC BLDC Motor Over Current";
CM_ SG_ 136 L_3HKBD_Rr_HVACBLDMotFltUnderVtg "3HKBD Rear HVAC BLDC Motor Fault Under Voltage";
CM_ SG_ 136 L_3HKBD_Rr_HVACBLDMotFltOverVtg "3HKBD Rear HVAC BLDC Motor Fault Over Voltage";
CM_ SG_ 136 L_3HKBD_Rr_HVACBLDCMotFltStall "3HKBD Rear HVAC BLDC Motor Fault Stall";
CM_ SG_ 136 L_3HKBD_Rr_HVACBLDCMotOverTemp "3HKBD Rear HVAC BLDC Motor Over Temperature";
CM_ SG_ 136 L_3HKBD_Rr_HVACBLDCMotCurrentLmt "3HKBD Rear HVAC BLDC Motor Current Limitation";
CM_ SG_ 136 L_3HKBD_Rr_HVACBLDCMotCtrlShtdwn "3HKBD Rear HVAC BLDC Motor Control Shut Down";
CM_ SG_ 136 L_3HKBD_Rr_HVACBLDCMotLimpMod "3HKBD Rear HVAC BLDC Motor Limit Mod";
CM_ SG_ 136 L_3HKBD_RrPsModeActrSt "3HKBD_RearPassengerModeActuatorStatus";
CM_ SG_ 136 L_3HKBD_Rr_HVACBLDCMotLINFail "3HKBD Rear HVAC BLDC Motor LIN Communication Fail";
CM_ SG_ 136 L_3HKBD_Rr_HVACBLDCMtrA "3HKBD Rear HVAC BLDC Motor Ampere";
CM_ BO_ 2683331328 "[EW] On Event and On Write";
CM_ BO_ 2683396864 "[EW] On Event and On Write";
CM_ BO_ 353 "[EC] On Event and On Change";
CM_ SG_ 353 L_ATCU_HU_FrDrEVntModeSet "Front Driver Electric Vent Mode Set";
CM_ SG_ 353 L_ATCU_HU_FrDrEVntCtrOpnCls "Front Driver Electric Vent Center Open Close Signal";
CM_ SG_ 353 L_ATCU_HU_FrPsEVntSideOpnCls "Front Passenger Electric Vent Side Open Close Signal";
CM_ SG_ 353 L_ATCU_HU_FrPsEVntCtrOpnCls "Front Passenger Electric Vent Center Open Close Signal";
CM_ SG_ 353 L_ATCU_HU_FrtEvntFocusLvlSet "status setting of front Electric Vent focus mode height level";
CM_ SG_ 353 L_ATCU_HU_FrPsEVntModeSet "Front Passenger Electric Vent Mode Set";
CM_ SG_ 353 L_ATCU_HU_FrDrEVntSideOpnCls "Front Driver Electric Vent Side Open Close Signal";
CM_ BO_ 354 "[EC] On Event and On Change";
CM_ SG_ 354 L_ATCU_CTS_FrtDrEVntModeSet "Front Driver Electric Vent Mode Set";
CM_ SG_ 354 L_ATCU_CTS_FrDrEVntCtrOpnCls "Front Driver Electric Vent Center Open Close Signal";
CM_ SG_ 354 L_ATCU_CTS_FrPsEVntSideOpnCls "Front Passenger Electric Vent Side Open Close Signal";
CM_ SG_ 354 L_ATCU_CTS_FrPsEVntCtrOpnCls "Front Passenger Electric Vent Center Open Close Signal";
CM_ SG_ 354 L_ATCU_CTS_RrEvntFocusLvlSet "status setting of Rear Electric Vent focus mode height level";
CM_ SG_ 354 L_ATCU_CTS_FrtPsEVntModeSet "Front Passenger Electric Vent Mode Set";
CM_ SG_ 354 L_ATCU_CTS_FrDrEVntSideOpnCls "Front Driver Electric Vent Side Open Close Signal";
CM_ BO_ 2683330816 "[EW] On Event and On Write";
CM_ BO_ 2683396352 "[EW] On Event and On Write";
CM_ BO_ 860 "[PE] Periodic and On Event";
CM_ SG_ 860 L_ATCU_Lib_MngrModBufCnt "ATCU Library Mode Manager Buffer Count";
CM_ SG_ 860 L_ATCU_Lib_MngrDEFBufCnt "ATCU Library DEF Manager Buffer Count";
CM_ SG_ 860 L_ATCU_Lib_MngrBlwBufCnt "ATCU Library Blower Manager Buffer Count";
CM_ SG_ 860 L_ATCU_Lib_MngrACBufCnt "ATCU Library AC Manager Buffer Count";
CM_ SG_ 860 L_ATCU_Lib_2LHMngrBlwBufCnt "ATCU Library 2nd Leftside Blower Manager Buffer Count";
CM_ SG_ 860 L_ATCU_Lib_2LHMngrModBufCnt "ATCU Library 2nd Leftside Mode Manager Buffer Count";
CM_ SG_ 860 L_ATCU_Lib_2LHMngrTempBufCnt "ATCU Library 2nd Leftside Temp Manager Buffer Count";
CM_ SG_ 860 L_ATCU_Lib_2RHMngrTempBufCnt "ATCU Library 2nd Rightside Temp Manager Buffer Count";
CM_ SG_ 860 L_ATCU_Lib_MngrTempBufCnt "ATCU Library Temp Manager Buffer Count";
CM_ SG_ 860 L_ATCU_Lib_MngrIntakeBufCnt "ATCU Library Intake Manager Buffer Count";
CM_ BO_ 913 "[PE] Periodic and On Event";
CM_ SG_ 913 L_ATCU_Lib_ADSBlrVtgVal "ATCU Library ADS Function Blower Voltage Value";
CM_ SG_ 913 L_ATCU_Lib_ADSDEFDrState "ATCU Library ADS Function DEF Door";
CM_ SG_ 913 L_ATCU_Lib_ADSACDispPreHoldReq "ATCU Library ADS Function AC Indicator Hold Req";
CM_ SG_ 913 L_ATCU_Lib_ADSACForcedOnReq "ATCU Library ADS Function AC Forced On Req";
CM_ SG_ 913 L_ATCU_Lib_ADSACState "ATCU Library ADS Function AC";
CM_ SG_ 913 L_ATCU_Lib_ADSInhibitPIReq "ATCU Library ADS Function Partial Intake Inhibit";
CM_ SG_ 913 L_ATCU_Lib_ADSModPrfleChgReq "ATCU Library ADS Function Mode Profile Change Req";
CM_ SG_ 913 L_ATCU_Lib_ADSIntakeState "ATCU Library ADS Function Intake";
CM_ SG_ 913 L_ATCU_Lib_ADSTempDrLmtState "ATCU Library ADS Function Temp Door Limit";
CM_ SG_ 913 L_ATCU_Lib_ADSOpState "ATCU Library ADS Function Operating State";
CM_ SG_ 913 L_ATCU_Lib_ADSSymState "ATCU Library ADS Function Symbol";
CM_ SG_ 913 L_ATCU_Lib_ADSModState "ATCU ADS Function Mode State";
CM_ BO_ 914 "[PE] Periodic and On Event";
CM_ SG_ 914 L_ATCU_Lib_PIIntakeState "ATCU Library Partial Intake Function";
CM_ SG_ 914 L_ATCU_Lib_AEWPOnReq "ATCU Library AEWP Function AEWP On Req";
CM_ SG_ 914 L_ATCU_Lib_AEWPRPMVal "ATCU Library AEWP Function AEWP RPM";
CM_ SG_ 914 L_ATCULib_AmbFilterResetOpState "ATCU Library Amb FilterReset Operation State";
CM_ SG_ 914 L_ATCULib_HVACIntlckHVActOffReq "ATCU Library HVAC Interlock HVAct Off Request";
CM_ SG_ 914 L_ATCULib_MainRlyProtectOpState "ATCU Library MainRelay Protect Operation State";
CM_ SG_ 914 L_ATCULib_ETCIntlckHVActOffReq "ATCU Library ETC Interlock HVAct Off Request";
CM_ SG_ 914 L_ATCULib_SyncSwSta "ATCU Library SyncSW State";
CM_ BO_ 833 "[PE] Periodic and On Event";
CM_ SG_ 833 MON_DiagAct_DrvModDrLck "ATCU Monitoring Test mode Driver Mode Door Lock Diagnostic";
CM_ SG_ 833 MON_DiagAct_AstModDrOpnSrt "ATCU Monitoring Test mode Assist Mode Door Open Short Diagnostic";
CM_ SG_ 833 MON_DiagAct_AstTmpDrOpnSrt "ATCU Monitoring Test mode Assist Temp Door Open Short  Diagnostic";
CM_ SG_ 833 MON_DiagAct_DrvTmpDrLck "ATCU Monitoring Test mode Driver Temp Door Lock Diagnostic";
CM_ SG_ 833 MON_DiagAct_AstTmpDrLck "ATCU Monitoring Test mode Assist Temp Door Lock Diagnostic";
CM_ SG_ 833 MON_DiagAct_DrvModDrOpnSrt "ATCU Monitoring Test mode Driver Mode Door Open Short Diagnostic";
CM_ SG_ 833 MON_DiagAct_DEFDrLck "ATCU Monitoring Test mode Def Door Lock Diagnostic";
CM_ SG_ 833 MON_DiagAct_IntakeDrLck "ATCU Monitoring Test mode Intake Door Lock Diagnostic";
CM_ SG_ 833 MON_DiagAct_IntakeDrOpnSrt "ATCU Monitoring Test mode Intake Door Open Short Diagnostic";
CM_ SG_ 833 MON_DiagAct_DEFDrOpnSrt "ATCU Monitoring Test mode Def Door Open Short Diagnostic";
CM_ SG_ 833 MON_DiagAct_ECompIntlck "ATCU Monitoring Test mode Electric Comprossor Interlock Diagnostic";
CM_ SG_ 833 MON_DiagAct_HVPTCIntlck "ATCU Monitoring Test mode HVPTC Interlock Diagnostic";
CM_ SG_ 833 MON_DiagAct_BatChlrEXVOpnSrt "ATCU Monitoring Test mode BatChlrEXVOpnSrt Diagnostic";
CM_ SG_ 833 MON_DiagAct_EvapTXVOpnSrt "ATCU Monitoring Test mode EvapTXVOpnSrt Diagnostic";
CM_ SG_ 833 MON_DiagAct_FrtPWMBlr "ATCU Monitoring Test mode FrtPWMBlr Diagnostic";
CM_ SG_ 833 MON_DiagAct_ECV "ATCU Monitoring Test mode ECV Diagnostic";
CM_ SG_ 833 MON_DiagAct_Rfgrant "ATCU Monitoring Test mode Rfgrant Diagnostic";
CM_ SG_ 833 MON_DiagAct_DrvTmpDrOpnSrt "ATCU Monitoring Test mode Driver Temp Door Open Short  Diagnostic";
CM_ SG_ 833 MON_DiagAct_VRLed "ATCU Monitoring Test mode VRLed Diagnostic";
CM_ SG_ 833 MON_DiagAct_AstModDrLck "ATCU Monitoring Test mode Assist Mode Door Lock Diagnostic";
CM_ BO_ 834 "[PE] Periodic and On Event";
CM_ SG_ 834 MON_DiagCOM_AcnOpPerm "ATCU Monitoring Test mode AcnOpPerm Diagnostic";
CM_ SG_ 834 MON_DiagCOM_BMSTmout "ATCU Monitoring Test mode BMSTmout Diagnostic";
CM_ SG_ 834 MON_DiagCOM_DrvClHtStOpt "ATCU Monitoring Test mode DrvClHtStOpt Diagnostic";
CM_ SG_ 834 MON_DiagCOM_AstClHtStOpt "ATCU Monitoring Test mode AstClHtStOpt Diagnostic";
CM_ SG_ 834 MON_DiagCOM_EcoModSw "ATCU Monitoring Test mode EcoModSw Diagnostic";
CM_ SG_ 834 MON_DiagCOM_EcompTmout "ATCU Monitoring Test mode EcompTmout Diagnostic";
CM_ SG_ 834 MON_DiagCOM_APT "ATCU Monitoring Test mode APT Diagnostic";
CM_ SG_ 834 MON_DiagCOM_EMSVehSpd "ATCU Monitoring Test mode EMSVehSpd Diagnostic";
CM_ SG_ 834 MON_DiagCOM_EngCool "ATCU Monitoring Test mode EngCool Diagnostic";
CM_ SG_ 834 MON_DiagCOM_EngOpMod "ATCU Monitoring Test mode EngOpMod Diagnostic";
CM_ SG_ 834 MON_DiagCOM_HEVRdy "ATCU Monitoring Test mode HEVRdy Diagnostic";
CM_ SG_ 834 MON_DiagCOM_HVPTCTmout "ATCU Monitoring Test mode HVPTCTmout Diagnostic";
CM_ SG_ 834 MON_DiagCOM_LDCWatt "ATCU Monitoring Test mode LDCWatt Diagnostic";
CM_ SG_ 834 MON_DiagCOM_LHPhoto "ATCU Monitoring Test mode LHPhoto Diagnostic";
CM_ SG_ 834 MON_DiagCOM_MainRlyOnSta "ATCU Monitoring Test mode MainRlyOnSta Diagnostic";
CM_ SG_ 834 MON_DiagCOM_MCUTmout "ATCU Monitoring Test mode MCUTmout Diagnostic";
CM_ SG_ 834 MON_DiagCOM_PMSnsr "ATCU Monitoring Test mode PMSnsr Diagnostic";
CM_ SG_ 834 MON_DiagCOM_BatChlrEXVDiag "ATCU Monitoring Test mode BatChlrEXVDiag Diagnostic";
CM_ SG_ 834 MON_DiagCOM_PnlBusOff "ATCU Monitoring Test mode PnlBusOff Diagnostic";
CM_ SG_ 834 MON_DiagCOM_PTGOpt "ATCU Monitoring Test mode PTGOpt Diagnostic";
CM_ SG_ 834 MON_DiagCOM_RHPhoto "ATCU Monitoring Test mode RHPhoto Diagnostic";
CM_ SG_ 834 MON_DiagCOM_RPM "ATCU Monitoring Test mode RPM Diagnostic";
CM_ SG_ 834 MON_DiagCOM_SideMirAmb "ATCU Monitoring Test mode SideMirAmb Diagnostic";
CM_ SG_ 834 MON_DiagCOM_ServiceMod "ATCU Monitoring Test mode ServiceMod Diagnostic";
CM_ SG_ 834 MON_DiagCOM_StrHtOpt "ATCU Monitoring Test mode StrHtOpt Diagnostic";
CM_ SG_ 834 MON_DiagCOM_TCUVehSpd "ATCU Monitoring Test mode TCUVehSpd Diagnostic";
CM_ SG_ 834 MON_DiagCOM_Torque "ATCU Monitoring Test mode Torque Diagnostic";
CM_ SG_ 834 MON_DiagCOM_VehBusOff "ATCU Monitoring Test mode VehBusOff Diagnostic";
CM_ SG_ 834 MON_DiagCOM_BATSoc "ATCU Monitoring Test mode BATSoc Diagnostic";
CM_ SG_ 834 MON_DiagCOM_WhlSpd "ATCU Monitoring Test mode WhlSpd Diagnostic";
CM_ SG_ 834 MON_DiagCOM_ClmtBusOff "ATCU Monitoring Test mode lmtBusOff Diagnostic";
CM_ SG_ 834 MON_DiagCOM_BMSIntakeReq "ATCU Monitoring Test mode BMSIntakeReq Diagnostic";
CM_ BO_ 835 "[PE] Periodic and On Event";
CM_ SG_ 835 MON_DiagSnsr_AMBTmp "ATCU Monitoring Test mode AMBTmp Diagnostic";
CM_ SG_ 835 MON_DiagSnsr_DEFDuctTmp "ATCU Monitoring Test mode DEFDuctTmp Diagnostic";
CM_ SG_ 835 MON_DiagSnsr_DOH "ATCU Monitoring Test mode DOH Diagnostic";
CM_ SG_ 835 MON_DiagSnsr_DrvFlrDuctTmp "ATCU Monitoring Test mode DrvFlrDuctTmp Diagnostic";
CM_ SG_ 835 MON_DiagSnsr_DrvVntDuctTmp "ATCU Monitoring Test mode DrvVntDuctTmp Diagnostic";
CM_ SG_ 835 MON_DiagSnsr_EvapTmp "ATCU Monitoring Test mode EvapTmp Diagnostic";
CM_ SG_ 835 MON_DiagSnsr_AstFlrDuctTmp "ATCU Monitoring Test mode AstFlrDuctTmp Diagnostic";
CM_ SG_ 835 MON_DiagSnsr_FDust "ATCU Monitoring Test mode FDust Diagnostic";
CM_ SG_ 835 MON_DiagSnsr_HghPrsrRfgPT "ATCU Monitoring Test mode HghPrsrRfgPT Diagnostic";
CM_ SG_ 835 MON_DiagSnsr_InCarTmp "ATCU Monitoring Test mode InCarTmp Diagnostic";
CM_ SG_ 835 MON_DiagSnsr_LHPhoto "ATCU Monitoring Test mode LHPhoto Diagnostic";
CM_ SG_ 835 MON_DiagSnsr_LowPrsrRfgPT "ATCU Monitoring Test mode LowPrsrRfgPT Diagnostic";
CM_ SG_ 835 MON_DiagSnsr_RHPhoto "ATCU Monitoring Test mode RHPhoto Diagnostic";
CM_ SG_ 835 MON_DiagSnsr_AstVntDuctTmp "ATCU Monitoring Test mode AstVntDuctTmp Diagnostic";
CM_ BO_ 2683332352 "[EW] On Event and On Write";
CM_ BO_ 2683397888 "[EW] On Event and On Write";
CM_ BO_ 2683331840 "[EW] On Event and On Write";
CM_ BO_ 2683397376 "[EW] On Event and On Write";
CM_ BO_ 2683332096 "[EW] On Event and On Write";
CM_ BO_ 2683397632 "[EW] On Event and On Write";
CM_ BO_ 2683331584 "[EW] On Event and On Write";
CM_ BO_ 2683397120 "[EW] On Event and On Write";
BA_DEF_ BO_ "UsrMsgIDSforwardDeviation" INT 0 100 ;
BA_DEF_ BO_ "UsrMsgIDSbackwardDeviation" INT 50 1000 ;
BA_DEF_ BO_ "GenMsgCycleTime" INT 0 2000 ;
BA_DEF_ BO_ "GenMsgStartDelayTime" INT 0 2000 ;
BA_DEF_ BO_ "GenMsgSendType" ENUM "Cyclic","NoMsgSendType" ;
BA_DEF_ BO_ "GenMsgCycleTimeFast" INT 0 500 ;
BA_DEF_ BO_ "GenMsgDelayTime" INT 0 20 ;
BA_DEF_ BO_ "GenMsgILSupport" ENUM "No","Yes" ;
BA_DEF_ BO_ "GenMsgNrOfRepetition" INT 0 3 ;
BA_DEF_ BO_ "VFrameFormat" ENUM "StandardCAN","ExtendedCAN","reserved","reserved","reserved","reserved","reserved","reserved","reserved","reserved","reserved","reserved","reserved","reserved","StandardCAN_FD","ExtendedCAN_FD" ;
BA_DEF_ SG_ "UserSigValidity" ENUM "B+","ACC","IG","IG1","IG2","IG3","IG1 or IG2","IG1 or IG3","Undef" ;
BA_DEF_ SG_ "UsrSigPurpose" ENUM "Undef","FN","DIAG","DIAG(Req)","DIAG(Res)","DIAG(Phy)","DEV","CCP(Req)","CCP(Res)","NM","TP" ;
BA_DEF_ SG_ "GenSigStartValue" INT 0 1215752192 ;
BA_DEF_ SG_ "NetworkRequestHoldingTime" INT 0 65535 ;
BA_DEF_ SG_ "Description" STRING ;
BA_DEF_ SG_ "Version" STRING ;
BA_DEF_ SG_ "GenSigEnvVarType" ENUM "Int","Float","Undef" ;
BA_DEF_ SG_ "GenSigSendType" ENUM "Cyclic","OnWrite","OnWriteWithRepetition","OnChange","OnChangeWithRepetition","IfActive","IfActiveWithRepetition","NoSigSendType","OnChangeAndIfActive","OnChangeAndIfActiveWithRepetition" ;
BA_DEF_ SG_ "GwSigLatencyTime" INT 0 65536 ;
BA_DEF_ SG_ "GwSigMissingSourceType" ENUM "Undef","OldValue","DefaultValue","InitialValue" ;
BA_DEF_ SG_ "NWM-WakeupAllowed" ENUM "<n.a.>" ;
BA_DEF_ SG_ "RoutingFactor" INT 1 1215752192 ;
BA_DEF_REL_ BU_SG_REL_ "GenSigTimeoutTime" INT 0 7000 ;
BA_DEF_DEF_ "UsrMsgIDSforwardDeviation" 10 ;
BA_DEF_DEF_ "UsrMsgIDSbackwardDeviation" 100 ;
BA_DEF_DEF_ "GenMsgCycleTime" 200 ;
BA_DEF_DEF_ "GenMsgStartDelayTime" 0 ;
BA_DEF_DEF_ "GenMsgSendType" "NoMsgSendType" ;
BA_DEF_DEF_ "GenMsgCycleTimeFast" 40 ;
BA_DEF_DEF_ "GenMsgDelayTime" 20 ;
BA_DEF_DEF_ "GenMsgILSupport" "Yes" ;
BA_DEF_DEF_ "GenMsgNrOfRepetition" 3 ;
BA_DEF_DEF_ "VFrameFormat" "StandardCAN" ;
BA_DEF_DEF_ "UserSigValidity" "IG" ;
BA_DEF_DEF_ "UsrSigPurpose" "FN" ;
BA_DEF_DEF_ "GenSigStartValue" 0 ;
BA_DEF_DEF_ "NetworkRequestHoldingTime" 0 ;
BA_DEF_DEF_ "Description" "" ;
BA_DEF_DEF_ "Version" "" ;
BA_DEF_DEF_ "GenSigEnvVarType" "Undef" ;
BA_DEF_DEF_ "GenSigSendType" "NoSigSendType" ;
BA_DEF_DEF_ "GwSigLatencyTime" 40 ;
BA_DEF_DEF_ "GwSigMissingSourceType" "Undef" ;
BA_DEF_DEF_ "NWM-WakeupAllowed" "<n.a.>" ;
BA_DEF_DEF_ "RoutingFactor" 1 ;
BA_DEF_DEF_REL_ "GenSigTimeoutTime" 500 ;
BA_ "GenMsgCycleTime" BO_ 2683331072 0;
BA_ "GenMsgNrOfRepetition" BO_ 2683331072 0;
BA_ "GenMsgNrOfRepetition" BO_ 2683331072 0;
BA_ "GenMsgDelayTime" BO_ 2683331072 10;
BA_ "VFrameFormat" BO_ 2683331072 1;
BA_ "UsrSigPurpose" SG_ 2683331072 DIG_2HKBD_Byte0 6;
BA_ "GenSigSendType" SG_ 2683331072 DIG_2HKBD_Byte0 2;
BA_ "UserSigValidity" SG_ 2683331072 DIG_2HKBD_Byte0 0;
BA_REL_ "GenSigTimeoutTime" BU_SG_REL_ L_2HKBD SG_ 2683331072 DIG_2HKBD_Byte0 0;
BA_ "Version" SG_ 2683331072 DIG_2HKBD_Byte0 "25.11.02";
BA_ "UsrSigPurpose" SG_ 2683331072 DIG_2HKBD_Byte2 6;
BA_ "GenSigSendType" SG_ 2683331072 DIG_2HKBD_Byte2 2;
BA_ "UserSigValidity" SG_ 2683331072 DIG_2HKBD_Byte2 0;
BA_REL_ "GenSigTimeoutTime" BU_SG_REL_ L_2HKBD SG_ 2683331072 DIG_2HKBD_Byte2 0;
BA_ "Version" SG_ 2683331072 DIG_2HKBD_Byte2 "25.11.02";
BA_ "UsrSigPurpose" SG_ 2683331072 DIG_2HKBD_Byte3 6;
BA_ "GenSigSendType" SG_ 2683331072 DIG_2HKBD_Byte3 2;
BA_ "UserSigValidity" SG_ 2683331072 DIG_2HKBD_Byte3 0;
BA_REL_ "GenSigTimeoutTime" BU_SG_REL_ L_2HKBD SG_ 2683331072 DIG_2HKBD_Byte3 0;
BA_ "Version" SG_ 2683331072 DIG_2HKBD_Byte3 "25.11.02";
BA_ "UsrSigPurpose" SG_ 2683331072 DIG_2HKBD_Byte4 6;
BA_ "GenSigSendType" SG_ 2683331072 DIG_2HKBD_Byte4 2;
BA_ "UserSigValidity" SG_ 2683331072 DIG_2HKBD_Byte4 0;
BA_REL_ "GenSigTimeoutTime" BU_SG_REL_ L_2HKBD SG_ 2683331072 DIG_2HKBD_Byte4 0;
BA_ "Version" SG_ 2683331072 DIG_2HKBD_Byte4 "25.11.02";
BA_ "UsrSigPurpose" SG_ 2683331072 DIG_2HKBD_Byte5 6;
BA_ "GenSigSendType" SG_ 2683331072 DIG_2HKBD_Byte5 2;
BA_ "UserSigValidity" SG_ 2683331072 DIG_2HKBD_Byte5 0;
BA_REL_ "GenSigTimeoutTime" BU_SG_REL_ L_2HKBD SG_ 2683331072 DIG_2HKBD_Byte5 0;
BA_ "Version" SG_ 2683331072 DIG_2HKBD_Byte5 "25.11.02";
BA_ "UsrSigPurpose" SG_ 2683331072 DIG_2HKBD_Byte6 6;
BA_ "GenSigSendType" SG_ 2683331072 DIG_2HKBD_Byte6 2;
BA_ "UserSigValidity" SG_ 2683331072 DIG_2HKBD_Byte6 0;
BA_REL_ "GenSigTimeoutTime" BU_SG_REL_ L_2HKBD SG_ 2683331072 DIG_2HKBD_Byte6 0;
BA_ "Version" SG_ 2683331072 DIG_2HKBD_Byte6 "25.11.02";
BA_ "UsrSigPurpose" SG_ 2683331072 DIG_2HKBD_Byte7 6;
BA_ "GenSigSendType" SG_ 2683331072 DIG_2HKBD_Byte7 2;
BA_ "UserSigValidity" SG_ 2683331072 DIG_2HKBD_Byte7 0;
BA_REL_ "GenSigTimeoutTime" BU_SG_REL_ L_2HKBD SG_ 2683331072 DIG_2HKBD_Byte7 0;
BA_ "Version" SG_ 2683331072 DIG_2HKBD_Byte7 "25.11.02";
BA_ "UsrSigPurpose" SG_ 2683331072 DIG_2HKBD_Byte1 6;
BA_ "GenSigSendType" SG_ 2683331072 DIG_2HKBD_Byte1 2;
BA_ "UserSigValidity" SG_ 2683331072 DIG_2HKBD_Byte1 0;
BA_REL_ "GenSigTimeoutTime" BU_SG_REL_ L_2HKBD SG_ 2683331072 DIG_2HKBD_Byte1 0;
BA_ "Version" SG_ 2683331072 DIG_2HKBD_Byte1 "25.11.02";
BA_ "GenMsgCycleTime" BO_ 2683396608 0;
BA_ "GenMsgNrOfRepetition" BO_ 2683396608 0;
BA_ "GenMsgNrOfRepetition" BO_ 2683396608 0;
BA_ "GenMsgDelayTime" BO_ 2683396608 10;
BA_ "VFrameFormat" BO_ 2683396608 1;
BA_ "UsrSigPurpose" SG_ 2683396608 _2HKBD_DIG_Byte0 6;
BA_ "GenSigSendType" SG_ 2683396608 _2HKBD_DIG_Byte0 2;
BA_ "UserSigValidity" SG_ 2683396608 _2HKBD_DIG_Byte0 0;
BA_REL_ "GenSigTimeoutTime" BU_SG_REL_ L_DIG SG_ 2683396608 _2HKBD_DIG_Byte0 0;
BA_ "Version" SG_ 2683396608 _2HKBD_DIG_Byte0 "25.11.02";
BA_ "UsrSigPurpose" SG_ 2683396608 _2HKBD_DIG_Byte2 6;
BA_ "GenSigSendType" SG_ 2683396608 _2HKBD_DIG_Byte2 2;
BA_ "UserSigValidity" SG_ 2683396608 _2HKBD_DIG_Byte2 0;
BA_REL_ "GenSigTimeoutTime" BU_SG_REL_ L_DIG SG_ 2683396608 _2HKBD_DIG_Byte2 0;
BA_ "Version" SG_ 2683396608 _2HKBD_DIG_Byte2 "25.11.02";
BA_ "UsrSigPurpose" SG_ 2683396608 _2HKBD_DIG_Byte3 6;
BA_ "GenSigSendType" SG_ 2683396608 _2HKBD_DIG_Byte3 2;
BA_ "UserSigValidity" SG_ 2683396608 _2HKBD_DIG_Byte3 0;
BA_REL_ "GenSigTimeoutTime" BU_SG_REL_ L_DIG SG_ 2683396608 _2HKBD_DIG_Byte3 0;
BA_ "Version" SG_ 2683396608 _2HKBD_DIG_Byte3 "25.11.02";
BA_ "UsrSigPurpose" SG_ 2683396608 _2HKBD_DIG_Byte4 6;
BA_ "GenSigSendType" SG_ 2683396608 _2HKBD_DIG_Byte4 2;
BA_ "UserSigValidity" SG_ 2683396608 _2HKBD_DIG_Byte4 0;
BA_REL_ "GenSigTimeoutTime" BU_SG_REL_ L_DIG SG_ 2683396608 _2HKBD_DIG_Byte4 0;
BA_ "Version" SG_ 2683396608 _2HKBD_DIG_Byte4 "25.11.02";
BA_ "UsrSigPurpose" SG_ 2683396608 _2HKBD_DIG_Byte5 6;
BA_ "GenSigSendType" SG_ 2683396608 _2HKBD_DIG_Byte5 2;
BA_ "UserSigValidity" SG_ 2683396608 _2HKBD_DIG_Byte5 0;
BA_REL_ "GenSigTimeoutTime" BU_SG_REL_ L_DIG SG_ 2683396608 _2HKBD_DIG_Byte5 0;
BA_ "Version" SG_ 2683396608 _2HKBD_DIG_Byte5 "25.11.02";
BA_ "UsrSigPurpose" SG_ 2683396608 _2HKBD_DIG_Byte6 6;
BA_ "GenSigSendType" SG_ 2683396608 _2HKBD_DIG_Byte6 2;
BA_ "UserSigValidity" SG_ 2683396608 _2HKBD_DIG_Byte6 0;
BA_REL_ "GenSigTimeoutTime" BU_SG_REL_ L_DIG SG_ 2683396608 _2HKBD_DIG_Byte6 0;
BA_ "Version" SG_ 2683396608 _2HKBD_DIG_Byte6 "25.11.02";
BA_ "UsrSigPurpose" SG_ 2683396608 _2HKBD_DIG_Byte7 6;
BA_ "GenSigSendType" SG_ 2683396608 _2HKBD_DIG_Byte7 2;
BA_ "UserSigValidity" SG_ 2683396608 _2HKBD_DIG_Byte7 0;
BA_REL_ "GenSigTimeoutTime" BU_SG_REL_ L_DIG SG_ 2683396608 _2HKBD_DIG_Byte7 0;
BA_ "Version" SG_ 2683396608 _2HKBD_DIG_Byte7 "25.11.02";
BA_ "UsrSigPurpose" SG_ 2683396608 _2HKBD_DIG_Byte1 6;
BA_ "GenSigSendType" SG_ 2683396608 _2HKBD_DIG_Byte1 2;
BA_ "UserSigValidity" SG_ 2683396608 _2HKBD_DIG_Byte1 0;
BA_REL_ "GenSigTimeoutTime" BU_SG_REL_ L_DIG SG_ 2683396608 _2HKBD_DIG_Byte1 0;
BA_ "Version" SG_ 2683396608 _2HKBD_DIG_Byte1 "25.11.02";
BA_ "GenMsgSendType" BO_ 129 0;
BA_ "GenMsgCycleTime" BO_ 129 500;
BA_ "Description" SG_ 129 L_3HKBD_SwOpt1 "Bit0~2:RESERVED

Bit3~4:(Type):0 - None/1 - ATC/2 - MTC 

Bit5~7:RESERVED";
BA_ "GenSigSendType" SG_ 129 L_3HKBD_SwOpt1 4;
BA_ "UserSigValidity" SG_ 129 L_3HKBD_SwOpt1 7;
BA_REL_ "GenSigTimeoutTime" BU_SG_REL_ L_ATCU SG_ 129 L_3HKBD_SwOpt1 5000;
BA_ "Version" SG_ 129 L_3HKBD_SwOpt1 "23.11.09";
BA_ "Description" SG_ 129 L_3HKBD_Typ2 "Bit 0 : 3rd ROOF DR DUCT Snsr : 0 ? Not Apply / 1 ? Apply

Bit 1 : 3rd ROOF Ast DUCT Snsr : 0 ? Not Apply / 1 ? Apply

Bit 2 : 3rd FLOOR DR DUCT Snsr : 0 ? Not Apply / 1 ? Apply

Bit 3 : 3rd FLOOR Ast DUCT Snsr : 0 ? Not Apply / 1 - Apply

Bit 4 : RESERVED

Bit 5~6 (3rd Multi Auto Text):0 - Multi Auto State Text Not Applied/1 - Multi Auto State Text Display Only Applied/2 - Multi Auto State Text Display & Control Applied/3 ? RESERVED

Bit7:(3rd REAR LOCK):0 ? NON REAR LOCK/1 ? REAR LOCK";
BA_ "GenSigSendType" SG_ 129 L_3HKBD_Typ2 4;
BA_ "UserSigValidity" SG_ 129 L_3HKBD_Typ2 7;
BA_REL_ "GenSigTimeoutTime" BU_SG_REL_ L_ATCU SG_ 129 L_3HKBD_Typ2 5000;
BA_ "Version" SG_ 129 L_3HKBD_Typ2 "24.11.00";
BA_ "GenSigSendType" SG_ 129 L_3HKBD_SW_Ver1 4;
BA_ "UserSigValidity" SG_ 129 L_3HKBD_SW_Ver1 7;
BA_REL_ "GenSigTimeoutTime" BU_SG_REL_ L_ATCU_vMON SG_ 129 L_3HKBD_SW_Ver1 5000;
BA_ "Version" SG_ 129 L_3HKBD_SW_Ver1 "25.05.04";
BA_ "GenSigSendType" SG_ 129 L_3HKBD_SW_Ver2 4;
BA_ "UserSigValidity" SG_ 129 L_3HKBD_SW_Ver2 7;
BA_REL_ "GenSigTimeoutTime" BU_SG_REL_ L_ATCU_vMON SG_ 129 L_3HKBD_SW_Ver2 5000;
BA_ "Version" SG_ 129 L_3HKBD_SW_Ver2 "25.05.04";
BA_ "GenSigSendType" SG_ 129 L_3HKBD_SW_Ver3 4;
BA_ "UserSigValidity" SG_ 129 L_3HKBD_SW_Ver3 7;
BA_REL_ "GenSigTimeoutTime" BU_SG_REL_ L_ATCU_vMON SG_ 129 L_3HKBD_SW_Ver3 5000;
BA_ "Version" SG_ 129 L_3HKBD_SW_Ver3 "25.05.04";
BA_ "Description" SG_ 129 L_3HKBD_Typ1 "Bit 0~7 : RESERVED";
BA_ "GenSigSendType" SG_ 129 L_3HKBD_Typ1 4;
BA_ "UserSigValidity" SG_ 129 L_3HKBD_Typ1 7;
BA_REL_ "GenSigTimeoutTime" BU_SG_REL_ L_ATCU SG_ 129 L_3HKBD_Typ1 5000;
BA_ "Version" SG_ 129 L_3HKBD_Typ1 "24.02.01";
BA_ "GenMsgSendType" BO_ 130 0;
BA_ "GenMsgCycleTime" BO_ 130 20;
BA_ "GenMsgCycleTimeFast" BO_ 130 0;
BA_ "GenMsgNrOfRepetition" BO_ 130 0;
BA_ "GenMsgDelayTime" BO_ 130 0;
BA_ "UserSigValidity" SG_ 130 L_3HKBD_Rr_TempActrFB 7;
BA_ "Version" SG_ 130 L_3HKBD_Rr_TempActrFB "23.09.05";
BA_ "UserSigValidity" SG_ 130 L_3HKBD_Rr_TempActrSt 7;
BA_ "Version" SG_ 130 L_3HKBD_Rr_TempActrSt "23.09.01";
BA_ "UserSigValidity" SG_ 130 L_3HKBD_Rr_TempAsstActrFB 7;
BA_ "Version" SG_ 130 L_3HKBD_Rr_TempAsstActrFB "23.09.05";
BA_ "UserSigValidity" SG_ 130 L_3HKBD_Rr_TempAsstActrSt 7;
BA_ "Version" SG_ 130 L_3HKBD_Rr_TempAsstActrSt "23.09.01";
BA_ "UserSigValidity" SG_ 130 L_3HKBD_RrDrModeActrFB 7;
BA_ "Version" SG_ 130 L_3HKBD_RrDrModeActrFB "24.02.08";
BA_ "UserSigValidity" SG_ 130 L_3HKBD_RrDrModeActrSt 7;
BA_ "Version" SG_ 130 L_3HKBD_RrDrModeActrSt "24.02.08";
BA_ "UserSigValidity" SG_ 130 L_3HKBD_Rr_BLDCError 7;
BA_ "Version" SG_ 130 L_3HKBD_Rr_BLDCError "23.09.01";
BA_ "UserSigValidity" SG_ 130 L_3HKBD_Rr_EvapVolVal 7;
BA_ "Version" SG_ 130 L_3HKBD_Rr_EvapVolVal "23.09.05";
BA_ "Description" SG_ 130 L_3HKBD_Rr_HVACBLDCRpmFB "00H~3E8H:RPM = Factor * Hex + Offset/3E9H ~ FFFFH:RESERVED";
BA_ "UserSigValidity" SG_ 130 L_3HKBD_Rr_HVACBLDCRpmFB 7;
BA_ "Version" SG_ 130 L_3HKBD_Rr_HVACBLDCRpmFB "23.09.05";
BA_ "GenMsgSendType" BO_ 131 0;
BA_ "GenMsgCycleTime" BO_ 131 500;
BA_ "Description" SG_ 131 L_3HKBD_SwBtnTyp "Each bit for button type is defined as

0-None/1-Hardkey/2-Touch(Used Beep)/3-Touch(Not Used Beep)

Bit 0~1 : 3rd Temp Button / Bit 2~3 : 3rd Blower Button / Bit 4~5 : 3rd Mode Button / Bit 6~7 : 3rd Auto Button / Bit 8~9 : 3rd A/C Button / Bit 10~11 : 3rd Sync Button / Bit 12~13 : 3rd StHeatVnt Button / Bit 14~15 : OFF / 16~19 : Reserved";
BA_ "GenSigSendType" SG_ 131 L_3HKBD_SwBtnTyp 4;
BA_ "UserSigValidity" SG_ 131 L_3HKBD_SwBtnTyp 7;
BA_REL_ "GenSigTimeoutTime" BU_SG_REL_ L_ATCU SG_ 131 L_3HKBD_SwBtnTyp 5000;
BA_ "Version" SG_ 131 L_3HKBD_SwBtnTyp "23.11.09";
BA_ "Description" SG_ 131 L_3HKBD_ResetOpSta "This signal indicates whether the reset operation has been completed or not";
BA_ "GenSigSendType" SG_ 131 L_3HKBD_ResetOpSta 4;
BA_ "UserSigValidity" SG_ 131 L_3HKBD_ResetOpSta 0;
BA_REL_ "GenSigTimeoutTime" BU_SG_REL_ L_ATCU SG_ 131 L_3HKBD_ResetOpSta 1000;
BA_ "Version" SG_ 131 L_3HKBD_ResetOpSta "24.10.05";
BA_ "GenMsgSendType" BO_ 132 0;
BA_ "GenSigSendType" SG_ 132 L_3HKBD_RrTempDnSw 4;
BA_ "UserSigValidity" SG_ 132 L_3HKBD_RrTempDnSw 7;
BA_REL_ "GenSigTimeoutTime" BU_SG_REL_ L_ATCU SG_ 132 L_3HKBD_RrTempDnSw 1500;
BA_ "Version" SG_ 132 L_3HKBD_RrTempDnSw "23.09.01";
BA_ "GenSigSendType" SG_ 132 L_3HKBD_RrTempUpSw 4;
BA_ "UserSigValidity" SG_ 132 L_3HKBD_RrTempUpSw 7;
BA_REL_ "GenSigTimeoutTime" BU_SG_REL_ L_ATCU SG_ 132 L_3HKBD_RrTempUpSw 1500;
BA_ "Version" SG_ 132 L_3HKBD_RrTempUpSw "23.09.01";
BA_ "GenSigSendType" SG_ 132 L_3HKBD_RrAutoSw 4;
BA_ "UserSigValidity" SG_ 132 L_3HKBD_RrAutoSw 7;
BA_REL_ "GenSigTimeoutTime" BU_SG_REL_ L_ATCU SG_ 132 L_3HKBD_RrAutoSw 1500;
BA_ "Version" SG_ 132 L_3HKBD_RrAutoSw "23.09.01";
BA_ "GenSigSendType" SG_ 132 L_3HKBD_RrOffSw 4;
BA_ "UserSigValidity" SG_ 132 L_3HKBD_RrOffSw 7;
BA_REL_ "GenSigTimeoutTime" BU_SG_REL_ L_ATCU SG_ 132 L_3HKBD_RrOffSw 1500;
BA_ "Version" SG_ 132 L_3HKBD_RrOffSw "23.09.01";
BA_ "GenSigSendType" SG_ 132 L_3HKBD_RrSyncSw 4;
BA_ "UserSigValidity" SG_ 132 L_3HKBD_RrSyncSw 7;
BA_REL_ "GenSigTimeoutTime" BU_SG_REL_ L_ATCU SG_ 132 L_3HKBD_RrSyncSw 1500;
BA_ "Version" SG_ 132 L_3HKBD_RrSyncSw "23.09.01";
BA_ "GenSigSendType" SG_ 132 L_3HKBD_RLStHtrSwReq 4;
BA_ "UserSigValidity" SG_ 132 L_3HKBD_RLStHtrSwReq 7;
BA_REL_ "GenSigTimeoutTime" BU_SG_REL_ L_ATCU SG_ 132 L_3HKBD_RLStHtrSwReq 1500;
BA_ "Version" SG_ 132 L_3HKBD_RLStHtrSwReq "23.09.01";
BA_ "GenSigSendType" SG_ 132 L_3HKBD_RLStVentSwReq 4;
BA_ "UserSigValidity" SG_ 132 L_3HKBD_RLStVentSwReq 7;
BA_REL_ "GenSigTimeoutTime" BU_SG_REL_ L_ATCU SG_ 132 L_3HKBD_RLStVentSwReq 1500;
BA_ "Version" SG_ 132 L_3HKBD_RLStVentSwReq "23.09.01";
BA_ "GenSigSendType" SG_ 132 L_3HKBD_RRStHtrSwReq 4;
BA_ "UserSigValidity" SG_ 132 L_3HKBD_RRStHtrSwReq 7;
BA_REL_ "GenSigTimeoutTime" BU_SG_REL_ L_ATCU SG_ 132 L_3HKBD_RRStHtrSwReq 1500;
BA_ "Version" SG_ 132 L_3HKBD_RRStHtrSwReq "23.09.01";
BA_ "GenSigSendType" SG_ 132 L_3HKBD_RRStVentSwReq 4;
BA_ "UserSigValidity" SG_ 132 L_3HKBD_RRStVentSwReq 7;
BA_REL_ "GenSigTimeoutTime" BU_SG_REL_ L_ATCU SG_ 132 L_3HKBD_RRStVentSwReq 1500;
BA_ "Version" SG_ 132 L_3HKBD_RRStVentSwReq "23.09.01";
BA_ "GenSigSendType" SG_ 132 L_3HKBD_RrBlwDnOffSw 4;
BA_ "UserSigValidity" SG_ 132 L_3HKBD_RrBlwDnOffSw 7;
BA_REL_ "GenSigTimeoutTime" BU_SG_REL_ L_ATCU SG_ 132 L_3HKBD_RrBlwDnOffSw 1500;
BA_ "Version" SG_ 132 L_3HKBD_RrBlwDnOffSw "23.09.01";
BA_ "GenSigSendType" SG_ 132 L_3HKBD_RrOnOffSet 4;
BA_ "GenSigStartValue" SG_ 132 L_3HKBD_RrOnOffSet 3;
BA_ "UserSigValidity" SG_ 132 L_3HKBD_RrOnOffSet 7;
BA_REL_ "GenSigTimeoutTime" BU_SG_REL_ L_ATCU SG_ 132 L_3HKBD_RrOnOffSet 1500;
BA_ "Version" SG_ 132 L_3HKBD_RrOnOffSet "24.01.00";
BA_ "GenSigSendType" SG_ 132 L_3HKBD_RrBlwDnSw 4;
BA_ "UserSigValidity" SG_ 132 L_3HKBD_RrBlwDnSw 7;
BA_REL_ "GenSigTimeoutTime" BU_SG_REL_ L_ATCU SG_ 132 L_3HKBD_RrBlwDnSw 1500;
BA_ "Version" SG_ 132 L_3HKBD_RrBlwDnSw "23.09.01";
BA_ "GenSigSendType" SG_ 132 L_3HKBD_RrblwUpMaxSw 4;
BA_ "UserSigValidity" SG_ 132 L_3HKBD_RrblwUpMaxSw 7;
BA_REL_ "GenSigTimeoutTime" BU_SG_REL_ L_ATCU SG_ 132 L_3HKBD_RrblwUpMaxSw 1500;
BA_ "Version" SG_ 132 L_3HKBD_RrblwUpMaxSw "25.05.04";
BA_ "GenSigSendType" SG_ 132 L_3HKBD_RrBlwUpSw 4;
BA_ "UserSigValidity" SG_ 132 L_3HKBD_RrBlwUpSw 7;
BA_REL_ "GenSigTimeoutTime" BU_SG_REL_ L_ATCU SG_ 132 L_3HKBD_RrBlwUpSw 1500;
BA_ "Version" SG_ 132 L_3HKBD_RrBlwUpSw "23.09.01";
BA_ "GenSigSendType" SG_ 132 L_3HKBD_RrModeDnSw 4;
BA_ "UserSigValidity" SG_ 132 L_3HKBD_RrModeDnSw 7;
BA_REL_ "GenSigTimeoutTime" BU_SG_REL_ L_ATCU SG_ 132 L_3HKBD_RrModeDnSw 1500;
BA_ "Version" SG_ 132 L_3HKBD_RrModeDnSw "23.09.01";
BA_ "GenSigSendType" SG_ 132 L_3HKBD_RrModeUpSw 4;
BA_ "UserSigValidity" SG_ 132 L_3HKBD_RrModeUpSw 7;
BA_REL_ "GenSigTimeoutTime" BU_SG_REL_ L_ATCU SG_ 132 L_3HKBD_RrModeUpSw 1500;
BA_ "Version" SG_ 132 L_3HKBD_RrModeUpSw "23.09.01";
BA_ "GenSigSendType" SG_ 132 L_3HKBD_RrModeSw 4;
BA_ "UserSigValidity" SG_ 132 L_3HKBD_RrModeSw 7;
BA_REL_ "GenSigTimeoutTime" BU_SG_REL_ L_ATCU SG_ 132 L_3HKBD_RrModeSw 1500;
BA_ "Version" SG_ 132 L_3HKBD_RrModeSw "23.09.01";
BA_ "GenSigSendType" SG_ 132 L_3HKBD_RrModeVentSw 4;
BA_ "UserSigValidity" SG_ 132 L_3HKBD_RrModeVentSw 7;
BA_REL_ "GenSigTimeoutTime" BU_SG_REL_ L_ATCU SG_ 132 L_3HKBD_RrModeVentSw 1500;
BA_ "Version" SG_ 132 L_3HKBD_RrModeVentSw "23.09.01";
BA_ "GenSigSendType" SG_ 132 L_3HKBD_RrModeFloorSw 4;
BA_ "UserSigValidity" SG_ 132 L_3HKBD_RrModeFloorSw 7;
BA_REL_ "GenSigTimeoutTime" BU_SG_REL_ L_ATCU SG_ 132 L_3HKBD_RrModeFloorSw 1500;
BA_ "Version" SG_ 132 L_3HKBD_RrModeFloorSw "23.09.01";
BA_ "GenSigSendType" SG_ 132 L_3HKBD_RrModeBiLvlSw 4;
BA_ "UserSigValidity" SG_ 132 L_3HKBD_RrModeBiLvlSw 7;
BA_REL_ "GenSigTimeoutTime" BU_SG_REL_ L_ATCU SG_ 132 L_3HKBD_RrModeBiLvlSw 1500;
BA_ "Version" SG_ 132 L_3HKBD_RrModeBiLvlSw "23.09.01";
BA_ "GenMsgSendType" BO_ 133 0;
BA_ "GenSigSendType" SG_ 133 L_3HKBD_RrDrFlrDuctSnsr 4;
BA_ "UserSigValidity" SG_ 133 L_3HKBD_RrDrFlrDuctSnsr 7;
BA_REL_ "GenSigTimeoutTime" BU_SG_REL_ L_ATCU SG_ 133 L_3HKBD_RrDrFlrDuctSnsr 1500;
BA_ "Version" SG_ 133 L_3HKBD_RrDrFlrDuctSnsr "24.02.01";
BA_ "GenSigSendType" SG_ 133 L_3HKBD_RrPsFlrDuctSnsr 4;
BA_ "UserSigValidity" SG_ 133 L_3HKBD_RrPsFlrDuctSnsr 7;
BA_REL_ "GenSigTimeoutTime" BU_SG_REL_ L_ATCU SG_ 133 L_3HKBD_RrPsFlrDuctSnsr 1500;
BA_ "Version" SG_ 133 L_3HKBD_RrPsFlrDuctSnsr "24.02.08";
BA_ "GenSigSendType" SG_ 133 L_3HKBD_RrPsVntDuctSnsr 4;
BA_ "UserSigValidity" SG_ 133 L_3HKBD_RrPsVntDuctSnsr 7;
BA_REL_ "GenSigTimeoutTime" BU_SG_REL_ L_ATCU SG_ 133 L_3HKBD_RrPsVntDuctSnsr 1500;
BA_ "Version" SG_ 133 L_3HKBD_RrPsVntDuctSnsr "24.02.01";
BA_ "GenSigSendType" SG_ 133 L_3HKBD_RrPsModeActrFB 4;
BA_ "UserSigValidity" SG_ 133 L_3HKBD_RrPsModeActrFB 7;
BA_REL_ "GenSigTimeoutTime" BU_SG_REL_ L_ATCU SG_ 133 L_3HKBD_RrPsModeActrFB 1500;
BA_ "Version" SG_ 133 L_3HKBD_RrPsModeActrFB "24.02.08";
BA_ "GenSigSendType" SG_ 133 L_3HKBD_RrDrVntDuctSnsr 4;
BA_ "UserSigValidity" SG_ 133 L_3HKBD_RrDrVntDuctSnsr 7;
BA_REL_ "GenSigTimeoutTime" BU_SG_REL_ L_ATCU SG_ 133 L_3HKBD_RrDrVntDuctSnsr 1500;
BA_ "Version" SG_ 133 L_3HKBD_RrDrVntDuctSnsr "24.02.01";
BA_ "GenMsgCycleTime" BO_ 134 0;
BA_ "GenSigSendType" SG_ 134 L_3HKBD_RrTempClickCnt 4;
BA_ "GenSigStartValue" SG_ 134 L_3HKBD_RrTempClickCnt 255;
BA_ "UserSigValidity" SG_ 134 L_3HKBD_RrTempClickCnt 7;
BA_REL_ "GenSigTimeoutTime" BU_SG_REL_ L_ATCU SG_ 134 L_3HKBD_RrTempClickCnt 0;
BA_ "Version" SG_ 134 L_3HKBD_RrTempClickCnt "24.01.00";
BA_ "GenSigSendType" SG_ 134 L_3HKBD_TempKnobCnt 4;
BA_ "GenSigStartValue" SG_ 134 L_3HKBD_TempKnobCnt 3;
BA_ "UserSigValidity" SG_ 134 L_3HKBD_TempKnobCnt 7;
BA_REL_ "GenSigTimeoutTime" BU_SG_REL_ L_ATCU SG_ 134 L_3HKBD_TempKnobCnt 0;
BA_ "Version" SG_ 134 L_3HKBD_TempKnobCnt "24.01.00";
BA_ "GenSigSendType" SG_ 134 L_3HKBD_BlwKnobCnt 4;
BA_ "GenSigStartValue" SG_ 134 L_3HKBD_BlwKnobCnt 3;
BA_ "UserSigValidity" SG_ 134 L_3HKBD_BlwKnobCnt 7;
BA_REL_ "GenSigTimeoutTime" BU_SG_REL_ L_ATCU SG_ 134 L_3HKBD_BlwKnobCnt 0;
BA_ "Version" SG_ 134 L_3HKBD_BlwKnobCnt "24.01.00";
BA_ "Description" SG_ 134 L_3HKBD_HVACPnlBckLight_Res "Vehicle API HVAC Control Panel BackLight Response";
BA_ "GenSigSendType" SG_ 134 L_3HKBD_HVACPnlBckLight_Res 4;
BA_ "UserSigValidity" SG_ 134 L_3HKBD_HVACPnlBckLight_Res 7;
BA_REL_ "GenSigTimeoutTime" BU_SG_REL_ L_ATCU SG_ 134 L_3HKBD_HVACPnlBckLight_Res 0;
BA_ "Version" SG_ 134 L_3HKBD_HVACPnlBckLight_Res "25.08.06";
BA_ "GenSigSendType" SG_ 134 L_3HKBD_RrBlwrClickCnt 4;
BA_ "GenSigStartValue" SG_ 134 L_3HKBD_RrBlwrClickCnt 255;
BA_ "UserSigValidity" SG_ 134 L_3HKBD_RrBlwrClickCnt 7;
BA_REL_ "GenSigTimeoutTime" BU_SG_REL_ L_ATCU SG_ 134 L_3HKBD_RrBlwrClickCnt 0;
BA_ "Version" SG_ 134 L_3HKBD_RrBlwrClickCnt "24.01.00";
BA_ "GenMsgSendType" BO_ 136 0;
BA_ "GenMsgCycleTime" BO_ 136 20;
BA_ "GenMsgCycleTimeFast" BO_ 136 0;
BA_ "GenMsgNrOfRepetition" BO_ 136 0;
BA_ "GenMsgDelayTime" BO_ 136 0;
BA_ "UserSigValidity" SG_ 136 L_3HKBD_Rr_HVACBLDCMtrVolt 7;
BA_ "Version" SG_ 136 L_3HKBD_Rr_HVACBLDCMtrVolt "24.02.06";
BA_ "UserSigValidity" SG_ 136 L_3HKBD_Rr_HVACBLDCOverCurrent 7;
BA_ "Version" SG_ 136 L_3HKBD_Rr_HVACBLDCOverCurrent "24.02.06";
BA_ "UserSigValidity" SG_ 136 L_3HKBD_Rr_HVACBLDMotFltUnderVtg 7;
BA_ "Version" SG_ 136 L_3HKBD_Rr_HVACBLDMotFltUnderVtg "24.02.06";
BA_ "UserSigValidity" SG_ 136 L_3HKBD_Rr_HVACBLDMotFltOverVtg 7;
BA_ "Version" SG_ 136 L_3HKBD_Rr_HVACBLDMotFltOverVtg "24.02.06";
BA_ "UserSigValidity" SG_ 136 L_3HKBD_Rr_HVACBLDCMotFltStall 7;
BA_ "Version" SG_ 136 L_3HKBD_Rr_HVACBLDCMotFltStall "24.02.06";
BA_ "UserSigValidity" SG_ 136 L_3HKBD_Rr_HVACBLDCMotOverTemp 7;
BA_ "Version" SG_ 136 L_3HKBD_Rr_HVACBLDCMotOverTemp "24.02.06";
BA_ "UserSigValidity" SG_ 136 L_3HKBD_Rr_HVACBLDCMotCurrentLmt 7;
BA_ "Version" SG_ 136 L_3HKBD_Rr_HVACBLDCMotCurrentLmt "24.02.06";
BA_ "UserSigValidity" SG_ 136 L_3HKBD_Rr_HVACBLDCMotCtrlShtdwn 7;
BA_ "Version" SG_ 136 L_3HKBD_Rr_HVACBLDCMotCtrlShtdwn "24.02.06";
BA_ "UserSigValidity" SG_ 136 L_3HKBD_Rr_HVACBLDCMotLimpMod 7;
BA_ "Version" SG_ 136 L_3HKBD_Rr_HVACBLDCMotLimpMod "24.02.06";
BA_ "UserSigValidity" SG_ 136 L_3HKBD_RrPsModeActrSt 7;
BA_ "Version" SG_ 136 L_3HKBD_RrPsModeActrSt "24.02.08";
BA_ "UserSigValidity" SG_ 136 L_3HKBD_Rr_HVACBLDCMotLINFail 7;
BA_ "Version" SG_ 136 L_3HKBD_Rr_HVACBLDCMotLINFail "24.05.08";
BA_ "UserSigValidity" SG_ 136 L_3HKBD_Rr_HVACBLDCMtrA 7;
BA_ "Version" SG_ 136 L_3HKBD_Rr_HVACBLDCMtrA "24.02.06";
BA_ "GenMsgCycleTime" BO_ 2683331328 0;
BA_ "GenMsgNrOfRepetition" BO_ 2683331328 0;
BA_ "GenMsgNrOfRepetition" BO_ 2683331328 0;
BA_ "GenMsgDelayTime" BO_ 2683331328 10;
BA_ "VFrameFormat" BO_ 2683331328 1;
BA_ "UsrSigPurpose" SG_ 2683331328 DIG_3HKBD_Byte0 6;
BA_ "GenSigSendType" SG_ 2683331328 DIG_3HKBD_Byte0 2;
BA_ "UserSigValidity" SG_ 2683331328 DIG_3HKBD_Byte0 0;
BA_REL_ "GenSigTimeoutTime" BU_SG_REL_ L_3HKBD SG_ 2683331328 DIG_3HKBD_Byte0 0;
BA_ "Version" SG_ 2683331328 DIG_3HKBD_Byte0 "25.11.02";
BA_ "UsrSigPurpose" SG_ 2683331328 DIG_3HKBD_Byte2 6;
BA_ "GenSigSendType" SG_ 2683331328 DIG_3HKBD_Byte2 2;
BA_ "UserSigValidity" SG_ 2683331328 DIG_3HKBD_Byte2 0;
BA_REL_ "GenSigTimeoutTime" BU_SG_REL_ L_3HKBD SG_ 2683331328 DIG_3HKBD_Byte2 0;
BA_ "Version" SG_ 2683331328 DIG_3HKBD_Byte2 "25.11.02";
BA_ "UsrSigPurpose" SG_ 2683331328 DIG_3HKBD_Byte3 6;
BA_ "GenSigSendType" SG_ 2683331328 DIG_3HKBD_Byte3 2;
BA_ "UserSigValidity" SG_ 2683331328 DIG_3HKBD_Byte3 0;
BA_REL_ "GenSigTimeoutTime" BU_SG_REL_ L_3HKBD SG_ 2683331328 DIG_3HKBD_Byte3 0;
BA_ "Version" SG_ 2683331328 DIG_3HKBD_Byte3 "25.11.02";
BA_ "UsrSigPurpose" SG_ 2683331328 DIG_3HKBD_Byte4 6;
BA_ "GenSigSendType" SG_ 2683331328 DIG_3HKBD_Byte4 2;
BA_ "UserSigValidity" SG_ 2683331328 DIG_3HKBD_Byte4 0;
BA_REL_ "GenSigTimeoutTime" BU_SG_REL_ L_3HKBD SG_ 2683331328 DIG_3HKBD_Byte4 0;
BA_ "Version" SG_ 2683331328 DIG_3HKBD_Byte4 "25.11.02";
BA_ "UsrSigPurpose" SG_ 2683331328 DIG_3HKBD_Byte5 6;
BA_ "GenSigSendType" SG_ 2683331328 DIG_3HKBD_Byte5 2;
BA_ "UserSigValidity" SG_ 2683331328 DIG_3HKBD_Byte5 0;
BA_REL_ "GenSigTimeoutTime" BU_SG_REL_ L_3HKBD SG_ 2683331328 DIG_3HKBD_Byte5 0;
BA_ "Version" SG_ 2683331328 DIG_3HKBD_Byte5 "25.11.02";
BA_ "UsrSigPurpose" SG_ 2683331328 DIG_3HKBD_Byte6 6;
BA_ "GenSigSendType" SG_ 2683331328 DIG_3HKBD_Byte6 2;
BA_ "UserSigValidity" SG_ 2683331328 DIG_3HKBD_Byte6 0;
BA_REL_ "GenSigTimeoutTime" BU_SG_REL_ L_3HKBD SG_ 2683331328 DIG_3HKBD_Byte6 0;
BA_ "Version" SG_ 2683331328 DIG_3HKBD_Byte6 "25.11.02";
BA_ "UsrSigPurpose" SG_ 2683331328 DIG_3HKBD_Byte7 6;
BA_ "GenSigSendType" SG_ 2683331328 DIG_3HKBD_Byte7 2;
BA_ "UserSigValidity" SG_ 2683331328 DIG_3HKBD_Byte7 0;
BA_REL_ "GenSigTimeoutTime" BU_SG_REL_ L_3HKBD SG_ 2683331328 DIG_3HKBD_Byte7 0;
BA_ "Version" SG_ 2683331328 DIG_3HKBD_Byte7 "25.11.02";
BA_ "UsrSigPurpose" SG_ 2683331328 DIG_3HKBD_Byte1 6;
BA_ "GenSigSendType" SG_ 2683331328 DIG_3HKBD_Byte1 2;
BA_ "UserSigValidity" SG_ 2683331328 DIG_3HKBD_Byte1 0;
BA_REL_ "GenSigTimeoutTime" BU_SG_REL_ L_3HKBD SG_ 2683331328 DIG_3HKBD_Byte1 0;
BA_ "Version" SG_ 2683331328 DIG_3HKBD_Byte1 "25.11.02";
BA_ "GenMsgCycleTime" BO_ 2683396864 0;
BA_ "GenMsgNrOfRepetition" BO_ 2683396864 0;
BA_ "GenMsgNrOfRepetition" BO_ 2683396864 0;
BA_ "GenMsgDelayTime" BO_ 2683396864 10;
BA_ "VFrameFormat" BO_ 2683396864 1;
BA_ "UsrSigPurpose" SG_ 2683396864 _3HKBD_DIG_Byte0 6;
BA_ "GenSigSendType" SG_ 2683396864 _3HKBD_DIG_Byte0 2;
BA_ "UserSigValidity" SG_ 2683396864 _3HKBD_DIG_Byte0 0;
BA_REL_ "GenSigTimeoutTime" BU_SG_REL_ L_DIG SG_ 2683396864 _3HKBD_DIG_Byte0 0;
BA_ "Version" SG_ 2683396864 _3HKBD_DIG_Byte0 "25.11.02";
BA_ "UsrSigPurpose" SG_ 2683396864 _3HKBD_DIG_Byte2 6;
BA_ "GenSigSendType" SG_ 2683396864 _3HKBD_DIG_Byte2 2;
BA_ "UserSigValidity" SG_ 2683396864 _3HKBD_DIG_Byte2 0;
BA_REL_ "GenSigTimeoutTime" BU_SG_REL_ L_DIG SG_ 2683396864 _3HKBD_DIG_Byte2 0;
BA_ "Version" SG_ 2683396864 _3HKBD_DIG_Byte2 "25.11.02";
BA_ "UsrSigPurpose" SG_ 2683396864 _3HKBD_DIG_Byte3 6;
BA_ "GenSigSendType" SG_ 2683396864 _3HKBD_DIG_Byte3 2;
BA_ "UserSigValidity" SG_ 2683396864 _3HKBD_DIG_Byte3 0;
BA_REL_ "GenSigTimeoutTime" BU_SG_REL_ L_DIG SG_ 2683396864 _3HKBD_DIG_Byte3 0;
BA_ "Version" SG_ 2683396864 _3HKBD_DIG_Byte3 "25.11.02";
BA_ "UsrSigPurpose" SG_ 2683396864 _3HKBD_DIG_Byte4 6;
BA_ "GenSigSendType" SG_ 2683396864 _3HKBD_DIG_Byte4 2;
BA_ "UserSigValidity" SG_ 2683396864 _3HKBD_DIG_Byte4 0;
BA_REL_ "GenSigTimeoutTime" BU_SG_REL_ L_DIG SG_ 2683396864 _3HKBD_DIG_Byte4 0;
BA_ "Version" SG_ 2683396864 _3HKBD_DIG_Byte4 "25.11.02";
BA_ "UsrSigPurpose" SG_ 2683396864 _3HKBD_DIG_Byte5 6;
BA_ "GenSigSendType" SG_ 2683396864 _3HKBD_DIG_Byte5 2;
BA_ "UserSigValidity" SG_ 2683396864 _3HKBD_DIG_Byte5 0;
BA_REL_ "GenSigTimeoutTime" BU_SG_REL_ L_DIG SG_ 2683396864 _3HKBD_DIG_Byte5 0;
BA_ "Version" SG_ 2683396864 _3HKBD_DIG_Byte5 "25.11.02";
BA_ "UsrSigPurpose" SG_ 2683396864 _3HKBD_DIG_Byte6 6;
BA_ "GenSigSendType" SG_ 2683396864 _3HKBD_DIG_Byte6 2;
BA_ "UserSigValidity" SG_ 2683396864 _3HKBD_DIG_Byte6 0;
BA_REL_ "GenSigTimeoutTime" BU_SG_REL_ L_DIG SG_ 2683396864 _3HKBD_DIG_Byte6 0;
BA_ "Version" SG_ 2683396864 _3HKBD_DIG_Byte6 "25.11.02";
BA_ "UsrSigPurpose" SG_ 2683396864 _3HKBD_DIG_Byte7 6;
BA_ "GenSigSendType" SG_ 2683396864 _3HKBD_DIG_Byte7 2;
BA_ "UserSigValidity" SG_ 2683396864 _3HKBD_DIG_Byte7 0;
BA_REL_ "GenSigTimeoutTime" BU_SG_REL_ L_DIG SG_ 2683396864 _3HKBD_DIG_Byte7 0;
BA_ "Version" SG_ 2683396864 _3HKBD_DIG_Byte7 "25.11.02";
BA_ "UsrSigPurpose" SG_ 2683396864 _3HKBD_DIG_Byte1 6;
BA_ "GenSigSendType" SG_ 2683396864 _3HKBD_DIG_Byte1 2;
BA_ "UserSigValidity" SG_ 2683396864 _3HKBD_DIG_Byte1 0;
BA_REL_ "GenSigTimeoutTime" BU_SG_REL_ L_DIG SG_ 2683396864 _3HKBD_DIG_Byte1 0;
BA_ "Version" SG_ 2683396864 _3HKBD_DIG_Byte1 "25.11.02";
BA_ "GenMsgCycleTime" BO_ 353 0;
BA_ "Description" SG_ 353 L_ATCU_HU_FrDrEVntModeSet "Electric Vent Frt Driver Mode Signal";
BA_ "GenSigSendType" SG_ 353 L_ATCU_HU_FrDrEVntModeSet 4;
BA_ "UserSigValidity" SG_ 353 L_ATCU_HU_FrDrEVntModeSet 7;
BA_REL_ "GenSigTimeoutTime" BU_SG_REL_ L_EVNT SG_ 353 L_ATCU_HU_FrDrEVntModeSet 0;
BA_ "Version" SG_ 353 L_ATCU_HU_FrDrEVntModeSet "25.04.02";
BA_ "Description" SG_ 353 L_ATCU_HU_FrDrEVntCtrOpnCls "Electric Vent Frt Driver Center Vent Open/Close Signal";
BA_ "GenSigSendType" SG_ 353 L_ATCU_HU_FrDrEVntCtrOpnCls 4;
BA_ "UserSigValidity" SG_ 353 L_ATCU_HU_FrDrEVntCtrOpnCls 7;
BA_REL_ "GenSigTimeoutTime" BU_SG_REL_ L_EVNT SG_ 353 L_ATCU_HU_FrDrEVntCtrOpnCls 0;
BA_ "Version" SG_ 353 L_ATCU_HU_FrDrEVntCtrOpnCls "24.05.11";
BA_ "Description" SG_ 353 L_ATCU_HU_FrPsEVntSideOpnCls "Electric Vent Frt Passenger Side Vent Open/Close Signal";
BA_ "GenSigSendType" SG_ 353 L_ATCU_HU_FrPsEVntSideOpnCls 4;
BA_ "UserSigValidity" SG_ 353 L_ATCU_HU_FrPsEVntSideOpnCls 7;
BA_REL_ "GenSigTimeoutTime" BU_SG_REL_ L_EVNT SG_ 353 L_ATCU_HU_FrPsEVntSideOpnCls 0;
BA_ "Version" SG_ 353 L_ATCU_HU_FrPsEVntSideOpnCls "24.05.11";
BA_ "Description" SG_ 353 L_ATCU_HU_FrPsEVntCtrOpnCls "Electric Vent Frt Passenger Center Vent Open/Close Signal";
BA_ "GenSigSendType" SG_ 353 L_ATCU_HU_FrPsEVntCtrOpnCls 4;
BA_ "UserSigValidity" SG_ 353 L_ATCU_HU_FrPsEVntCtrOpnCls 7;
BA_REL_ "GenSigTimeoutTime" BU_SG_REL_ L_EVNT SG_ 353 L_ATCU_HU_FrPsEVntCtrOpnCls 0;
BA_ "Version" SG_ 353 L_ATCU_HU_FrPsEVntCtrOpnCls "24.05.11";
BA_ "GenSigSendType" SG_ 353 L_ATCU_HU_FrtEvntFocusLvlSet 4;
BA_ "UserSigValidity" SG_ 353 L_ATCU_HU_FrtEvntFocusLvlSet 7;
BA_REL_ "GenSigTimeoutTime" BU_SG_REL_ L_EVNT SG_ 353 L_ATCU_HU_FrtEvntFocusLvlSet 0;
BA_ "Version" SG_ 353 L_ATCU_HU_FrtEvntFocusLvlSet "25.05.04";
BA_ "Description" SG_ 353 L_ATCU_HU_FrPsEVntModeSet "Electric Vent Frt Passenger Mode Signal";
BA_ "GenSigSendType" SG_ 353 L_ATCU_HU_FrPsEVntModeSet 4;
BA_ "UserSigValidity" SG_ 353 L_ATCU_HU_FrPsEVntModeSet 7;
BA_REL_ "GenSigTimeoutTime" BU_SG_REL_ L_EVNT SG_ 353 L_ATCU_HU_FrPsEVntModeSet 0;
BA_ "Version" SG_ 353 L_ATCU_HU_FrPsEVntModeSet "25.04.02";
BA_ "Description" SG_ 353 L_ATCU_HU_FrDrEVntSideOpnCls "Electric Vent Frt Driver Side Vent Open/Close Signal";
BA_ "GenSigSendType" SG_ 353 L_ATCU_HU_FrDrEVntSideOpnCls 4;
BA_ "UserSigValidity" SG_ 353 L_ATCU_HU_FrDrEVntSideOpnCls 7;
BA_REL_ "GenSigTimeoutTime" BU_SG_REL_ L_EVNT SG_ 353 L_ATCU_HU_FrDrEVntSideOpnCls 0;
BA_ "Version" SG_ 353 L_ATCU_HU_FrDrEVntSideOpnCls "24.05.11";
BA_ "GenMsgCycleTime" BO_ 354 0;
BA_ "Description" SG_ 354 L_ATCU_CTS_FrtDrEVntModeSet "Electric Vent Mode_Frt Dr";
BA_ "GenSigSendType" SG_ 354 L_ATCU_CTS_FrtDrEVntModeSet 4;
BA_ "UserSigValidity" SG_ 354 L_ATCU_CTS_FrtDrEVntModeSet 7;
BA_REL_ "GenSigTimeoutTime" BU_SG_REL_ L_EVNT SG_ 354 L_ATCU_CTS_FrtDrEVntModeSet 0;
BA_ "Version" SG_ 354 L_ATCU_CTS_FrtDrEVntModeSet "25.04.02";
BA_ "Description" SG_ 354 L_ATCU_CTS_FrDrEVntCtrOpnCls "Electric Vent FRT Dr Center Vent Open/Close Signal";
BA_ "GenSigSendType" SG_ 354 L_ATCU_CTS_FrDrEVntCtrOpnCls 4;
BA_ "UserSigValidity" SG_ 354 L_ATCU_CTS_FrDrEVntCtrOpnCls 7;
BA_REL_ "GenSigTimeoutTime" BU_SG_REL_ L_EVNT SG_ 354 L_ATCU_CTS_FrDrEVntCtrOpnCls 0;
BA_ "Version" SG_ 354 L_ATCU_CTS_FrDrEVntCtrOpnCls "24.08.00";
BA_ "Description" SG_ 354 L_ATCU_CTS_FrPsEVntSideOpnCls "Electric Vent FRT Ps Side Vent Open/Close Signal";
BA_ "GenSigSendType" SG_ 354 L_ATCU_CTS_FrPsEVntSideOpnCls 4;
BA_ "UserSigValidity" SG_ 354 L_ATCU_CTS_FrPsEVntSideOpnCls 7;
BA_REL_ "GenSigTimeoutTime" BU_SG_REL_ L_EVNT SG_ 354 L_ATCU_CTS_FrPsEVntSideOpnCls 0;
BA_ "Version" SG_ 354 L_ATCU_CTS_FrPsEVntSideOpnCls "24.08.00";
BA_ "Description" SG_ 354 L_ATCU_CTS_FrPsEVntCtrOpnCls "Electric Vent FRT Ps Center Vent Open/Close Signal";
BA_ "GenSigSendType" SG_ 354 L_ATCU_CTS_FrPsEVntCtrOpnCls 4;
BA_ "UserSigValidity" SG_ 354 L_ATCU_CTS_FrPsEVntCtrOpnCls 7;
BA_REL_ "GenSigTimeoutTime" BU_SG_REL_ L_EVNT SG_ 354 L_ATCU_CTS_FrPsEVntCtrOpnCls 0;
BA_ "Version" SG_ 354 L_ATCU_CTS_FrPsEVntCtrOpnCls "24.08.00";
BA_ "GenSigSendType" SG_ 354 L_ATCU_CTS_RrEvntFocusLvlSet 4;
BA_ "UserSigValidity" SG_ 354 L_ATCU_CTS_RrEvntFocusLvlSet 7;
BA_REL_ "GenSigTimeoutTime" BU_SG_REL_ L_EVNT SG_ 354 L_ATCU_CTS_RrEvntFocusLvlSet 0;
BA_ "Version" SG_ 354 L_ATCU_CTS_RrEvntFocusLvlSet "25.05.04";
BA_ "Description" SG_ 354 L_ATCU_CTS_FrtPsEVntModeSet "Electric Vent Mode_Frt Ps";
BA_ "GenSigSendType" SG_ 354 L_ATCU_CTS_FrtPsEVntModeSet 4;
BA_ "UserSigValidity" SG_ 354 L_ATCU_CTS_FrtPsEVntModeSet 7;
BA_REL_ "GenSigTimeoutTime" BU_SG_REL_ L_EVNT SG_ 354 L_ATCU_CTS_FrtPsEVntModeSet 0;
BA_ "Version" SG_ 354 L_ATCU_CTS_FrtPsEVntModeSet "25.04.02";
BA_ "Description" SG_ 354 L_ATCU_CTS_FrDrEVntSideOpnCls "Electric Vent FRT Dr Side Vent Open/Close Signal";
BA_ "GenSigSendType" SG_ 354 L_ATCU_CTS_FrDrEVntSideOpnCls 4;
BA_ "UserSigValidity" SG_ 354 L_ATCU_CTS_FrDrEVntSideOpnCls 7;
BA_REL_ "GenSigTimeoutTime" BU_SG_REL_ L_EVNT SG_ 354 L_ATCU_CTS_FrDrEVntSideOpnCls 0;
BA_ "Version" SG_ 354 L_ATCU_CTS_FrDrEVntSideOpnCls "24.08.00";
BA_ "GenMsgCycleTime" BO_ 2683330816 0;
BA_ "GenMsgNrOfRepetition" BO_ 2683330816 0;
BA_ "GenMsgNrOfRepetition" BO_ 2683330816 0;
BA_ "GenMsgDelayTime" BO_ 2683330816 10;
BA_ "VFrameFormat" BO_ 2683330816 1;
BA_ "UsrSigPurpose" SG_ 2683330816 DIG_ATCU_Byte0 6;
BA_ "GenSigSendType" SG_ 2683330816 DIG_ATCU_Byte0 2;
BA_ "UserSigValidity" SG_ 2683330816 DIG_ATCU_Byte0 0;
BA_REL_ "GenSigTimeoutTime" BU_SG_REL_ L_ATCU SG_ 2683330816 DIG_ATCU_Byte0 0;
BA_ "Version" SG_ 2683330816 DIG_ATCU_Byte0 "25.11.02";
BA_ "UsrSigPurpose" SG_ 2683330816 DIG_ATCU_Byte2 6;
BA_ "GenSigSendType" SG_ 2683330816 DIG_ATCU_Byte2 2;
BA_ "UserSigValidity" SG_ 2683330816 DIG_ATCU_Byte2 0;
BA_REL_ "GenSigTimeoutTime" BU_SG_REL_ L_ATCU SG_ 2683330816 DIG_ATCU_Byte2 0;
BA_ "Version" SG_ 2683330816 DIG_ATCU_Byte2 "25.11.02";
BA_ "UsrSigPurpose" SG_ 2683330816 DIG_ATCU_Byte3 6;
BA_ "GenSigSendType" SG_ 2683330816 DIG_ATCU_Byte3 2;
BA_ "UserSigValidity" SG_ 2683330816 DIG_ATCU_Byte3 0;
BA_REL_ "GenSigTimeoutTime" BU_SG_REL_ L_ATCU SG_ 2683330816 DIG_ATCU_Byte3 0;
BA_ "Version" SG_ 2683330816 DIG_ATCU_Byte3 "25.11.02";
BA_ "UsrSigPurpose" SG_ 2683330816 DIG_ATCU_Byte4 6;
BA_ "GenSigSendType" SG_ 2683330816 DIG_ATCU_Byte4 2;
BA_ "UserSigValidity" SG_ 2683330816 DIG_ATCU_Byte4 0;
BA_REL_ "GenSigTimeoutTime" BU_SG_REL_ L_ATCU SG_ 2683330816 DIG_ATCU_Byte4 0;
BA_ "Version" SG_ 2683330816 DIG_ATCU_Byte4 "25.11.02";
BA_ "UsrSigPurpose" SG_ 2683330816 DIG_ATCU_Byte5 6;
BA_ "GenSigSendType" SG_ 2683330816 DIG_ATCU_Byte5 2;
BA_ "UserSigValidity" SG_ 2683330816 DIG_ATCU_Byte5 0;
BA_REL_ "GenSigTimeoutTime" BU_SG_REL_ L_ATCU SG_ 2683330816 DIG_ATCU_Byte5 0;
BA_ "Version" SG_ 2683330816 DIG_ATCU_Byte5 "25.11.02";
BA_ "UsrSigPurpose" SG_ 2683330816 DIG_ATCU_Byte6 6;
BA_ "GenSigSendType" SG_ 2683330816 DIG_ATCU_Byte6 2;
BA_ "UserSigValidity" SG_ 2683330816 DIG_ATCU_Byte6 0;
BA_REL_ "GenSigTimeoutTime" BU_SG_REL_ L_ATCU SG_ 2683330816 DIG_ATCU_Byte6 0;
BA_ "Version" SG_ 2683330816 DIG_ATCU_Byte6 "25.11.02";
BA_ "UsrSigPurpose" SG_ 2683330816 DIG_ATCU_Byte7 6;
BA_ "GenSigSendType" SG_ 2683330816 DIG_ATCU_Byte7 2;
BA_ "UserSigValidity" SG_ 2683330816 DIG_ATCU_Byte7 0;
BA_REL_ "GenSigTimeoutTime" BU_SG_REL_ L_ATCU SG_ 2683330816 DIG_ATCU_Byte7 0;
BA_ "Version" SG_ 2683330816 DIG_ATCU_Byte7 "25.11.02";
BA_ "UsrSigPurpose" SG_ 2683330816 DIG_ATCU_Byte1 6;
BA_ "GenSigSendType" SG_ 2683330816 DIG_ATCU_Byte1 2;
BA_ "UserSigValidity" SG_ 2683330816 DIG_ATCU_Byte1 0;
BA_REL_ "GenSigTimeoutTime" BU_SG_REL_ L_ATCU SG_ 2683330816 DIG_ATCU_Byte1 0;
BA_ "Version" SG_ 2683330816 DIG_ATCU_Byte1 "25.11.02";
BA_ "GenMsgCycleTime" BO_ 2683396352 0;
BA_ "GenMsgNrOfRepetition" BO_ 2683396352 0;
BA_ "GenMsgNrOfRepetition" BO_ 2683396352 0;
BA_ "GenMsgDelayTime" BO_ 2683396352 10;
BA_ "VFrameFormat" BO_ 2683396352 1;
BA_ "UsrSigPurpose" SG_ 2683396352 ATCU_DIG_Byte0 6;
BA_ "GenSigSendType" SG_ 2683396352 ATCU_DIG_Byte0 2;
BA_ "UserSigValidity" SG_ 2683396352 ATCU_DIG_Byte0 0;
BA_REL_ "GenSigTimeoutTime" BU_SG_REL_ L_DIG SG_ 2683396352 ATCU_DIG_Byte0 0;
BA_ "Version" SG_ 2683396352 ATCU_DIG_Byte0 "25.11.02";
BA_ "UsrSigPurpose" SG_ 2683396352 ATCU_DIG_Byte2 6;
BA_ "GenSigSendType" SG_ 2683396352 ATCU_DIG_Byte2 2;
BA_ "UserSigValidity" SG_ 2683396352 ATCU_DIG_Byte2 0;
BA_REL_ "GenSigTimeoutTime" BU_SG_REL_ L_DIG SG_ 2683396352 ATCU_DIG_Byte2 0;
BA_ "Version" SG_ 2683396352 ATCU_DIG_Byte2 "25.11.02";
BA_ "UsrSigPurpose" SG_ 2683396352 ATCU_DIG_Byte3 6;
BA_ "GenSigSendType" SG_ 2683396352 ATCU_DIG_Byte3 2;
BA_ "UserSigValidity" SG_ 2683396352 ATCU_DIG_Byte3 0;
BA_REL_ "GenSigTimeoutTime" BU_SG_REL_ L_DIG SG_ 2683396352 ATCU_DIG_Byte3 0;
BA_ "Version" SG_ 2683396352 ATCU_DIG_Byte3 "25.11.02";
BA_ "UsrSigPurpose" SG_ 2683396352 ATCU_DIG_Byte4 6;
BA_ "GenSigSendType" SG_ 2683396352 ATCU_DIG_Byte4 2;
BA_ "UserSigValidity" SG_ 2683396352 ATCU_DIG_Byte4 0;
BA_REL_ "GenSigTimeoutTime" BU_SG_REL_ L_DIG SG_ 2683396352 ATCU_DIG_Byte4 0;
BA_ "Version" SG_ 2683396352 ATCU_DIG_Byte4 "25.11.02";
BA_ "UsrSigPurpose" SG_ 2683396352 ATCU_DIG_Byte5 6;
BA_ "GenSigSendType" SG_ 2683396352 ATCU_DIG_Byte5 2;
BA_ "UserSigValidity" SG_ 2683396352 ATCU_DIG_Byte5 0;
BA_REL_ "GenSigTimeoutTime" BU_SG_REL_ L_DIG SG_ 2683396352 ATCU_DIG_Byte5 0;
BA_ "Version" SG_ 2683396352 ATCU_DIG_Byte5 "25.11.02";
BA_ "UsrSigPurpose" SG_ 2683396352 ATCU_DIG_Byte6 6;
BA_ "GenSigSendType" SG_ 2683396352 ATCU_DIG_Byte6 2;
BA_ "UserSigValidity" SG_ 2683396352 ATCU_DIG_Byte6 0;
BA_REL_ "GenSigTimeoutTime" BU_SG_REL_ L_DIG SG_ 2683396352 ATCU_DIG_Byte6 0;
BA_ "Version" SG_ 2683396352 ATCU_DIG_Byte6 "25.11.02";
BA_ "UsrSigPurpose" SG_ 2683396352 ATCU_DIG_Byte7 6;
BA_ "GenSigSendType" SG_ 2683396352 ATCU_DIG_Byte7 2;
BA_ "UserSigValidity" SG_ 2683396352 ATCU_DIG_Byte7 0;
BA_REL_ "GenSigTimeoutTime" BU_SG_REL_ L_DIG SG_ 2683396352 ATCU_DIG_Byte7 0;
BA_ "Version" SG_ 2683396352 ATCU_DIG_Byte7 "25.11.02";
BA_ "UsrSigPurpose" SG_ 2683396352 ATCU_DIG_Byte1 6;
BA_ "GenSigSendType" SG_ 2683396352 ATCU_DIG_Byte1 2;
BA_ "UserSigValidity" SG_ 2683396352 ATCU_DIG_Byte1 0;
BA_REL_ "GenSigTimeoutTime" BU_SG_REL_ L_DIG SG_ 2683396352 ATCU_DIG_Byte1 0;
BA_ "Version" SG_ 2683396352 ATCU_DIG_Byte1 "25.11.02";
BA_ "GenMsgSendType" BO_ 860 0;
BA_ "GenMsgCycleTime" BO_ 860 500;
BA_ "Description" SG_ 860 L_ATCU_Lib_MngrModBufCnt "This value only use for ATCU Library data monitoring (Only use before SOP)";
BA_ "GenSigSendType" SG_ 860 L_ATCU_Lib_MngrModBufCnt 4;
BA_ "UserSigValidity" SG_ 860 L_ATCU_Lib_MngrModBufCnt 0;
BA_REL_ "GenSigTimeoutTime" BU_SG_REL_ L_ATCU_vMON SG_ 860 L_ATCU_Lib_MngrModBufCnt 5000;
BA_ "Version" SG_ 860 L_ATCU_Lib_MngrModBufCnt "23.11.10";
BA_ "Description" SG_ 860 L_ATCU_Lib_MngrDEFBufCnt "This value only use for ATCU Library data monitoring (Only use before SOP)";
BA_ "GenSigSendType" SG_ 860 L_ATCU_Lib_MngrDEFBufCnt 4;
BA_ "UserSigValidity" SG_ 860 L_ATCU_Lib_MngrDEFBufCnt 0;
BA_REL_ "GenSigTimeoutTime" BU_SG_REL_ L_ATCU_vMON SG_ 860 L_ATCU_Lib_MngrDEFBufCnt 5000;
BA_ "Version" SG_ 860 L_ATCU_Lib_MngrDEFBufCnt "23.11.10";
BA_ "Description" SG_ 860 L_ATCU_Lib_MngrBlwBufCnt "This value only use for ATCU Library data monitoring (Only use before SOP)";
BA_ "GenSigSendType" SG_ 860 L_ATCU_Lib_MngrBlwBufCnt 4;
BA_ "UserSigValidity" SG_ 860 L_ATCU_Lib_MngrBlwBufCnt 0;
BA_REL_ "GenSigTimeoutTime" BU_SG_REL_ L_ATCU_vMON SG_ 860 L_ATCU_Lib_MngrBlwBufCnt 5000;
BA_ "Version" SG_ 860 L_ATCU_Lib_MngrBlwBufCnt "23.11.10";
BA_ "Description" SG_ 860 L_ATCU_Lib_MngrACBufCnt "This value only use for ATCU Library data monitoring (Only use before SOP)";
BA_ "GenSigSendType" SG_ 860 L_ATCU_Lib_MngrACBufCnt 4;
BA_ "UserSigValidity" SG_ 860 L_ATCU_Lib_MngrACBufCnt 0;
BA_REL_ "GenSigTimeoutTime" BU_SG_REL_ L_ATCU_vMON SG_ 860 L_ATCU_Lib_MngrACBufCnt 5000;
BA_ "Version" SG_ 860 L_ATCU_Lib_MngrACBufCnt "23.11.10";
BA_ "Description" SG_ 860 L_ATCU_Lib_2LHMngrBlwBufCnt "This value only use for ATCU Library data monitoring (Only use before SOP)";
BA_ "GenSigSendType" SG_ 860 L_ATCU_Lib_2LHMngrBlwBufCnt 4;
BA_ "UserSigValidity" SG_ 860 L_ATCU_Lib_2LHMngrBlwBufCnt 0;
BA_REL_ "GenSigTimeoutTime" BU_SG_REL_ L_ATCU_vMON SG_ 860 L_ATCU_Lib_2LHMngrBlwBufCnt 5000;
BA_ "Version" SG_ 860 L_ATCU_Lib_2LHMngrBlwBufCnt "23.11.10";
BA_ "Description" SG_ 860 L_ATCU_Lib_2LHMngrModBufCnt "This value only use for ATCU Library data monitoring (Only use before SOP)";
BA_ "GenSigSendType" SG_ 860 L_ATCU_Lib_2LHMngrModBufCnt 4;
BA_ "UserSigValidity" SG_ 860 L_ATCU_Lib_2LHMngrModBufCnt 0;
BA_REL_ "GenSigTimeoutTime" BU_SG_REL_ L_ATCU_vMON SG_ 860 L_ATCU_Lib_2LHMngrModBufCnt 5000;
BA_ "Version" SG_ 860 L_ATCU_Lib_2LHMngrModBufCnt "23.11.10";
BA_ "Description" SG_ 860 L_ATCU_Lib_2LHMngrTempBufCnt "This value only use for ATCU Library data monitoring (Only use before SOP)";
BA_ "GenSigSendType" SG_ 860 L_ATCU_Lib_2LHMngrTempBufCnt 4;
BA_ "UserSigValidity" SG_ 860 L_ATCU_Lib_2LHMngrTempBufCnt 0;
BA_REL_ "GenSigTimeoutTime" BU_SG_REL_ L_ATCU_vMON SG_ 860 L_ATCU_Lib_2LHMngrTempBufCnt 5000;
BA_ "Version" SG_ 860 L_ATCU_Lib_2LHMngrTempBufCnt "23.11.10";
BA_ "Description" SG_ 860 L_ATCU_Lib_2RHMngrTempBufCnt "This value only use for ATCU Library data monitoring (Only use before SOP)";
BA_ "GenSigSendType" SG_ 860 L_ATCU_Lib_2RHMngrTempBufCnt 4;
BA_ "UserSigValidity" SG_ 860 L_ATCU_Lib_2RHMngrTempBufCnt 0;
BA_REL_ "GenSigTimeoutTime" BU_SG_REL_ L_ATCU_vMON SG_ 860 L_ATCU_Lib_2RHMngrTempBufCnt 5000;
BA_ "Version" SG_ 860 L_ATCU_Lib_2RHMngrTempBufCnt "23.11.10";
BA_ "Description" SG_ 860 L_ATCU_Lib_MngrTempBufCnt "This value only use for ATCU Library data monitoring (Only use before SOP)";
BA_ "GenSigSendType" SG_ 860 L_ATCU_Lib_MngrTempBufCnt 4;
BA_ "UserSigValidity" SG_ 860 L_ATCU_Lib_MngrTempBufCnt 0;
BA_REL_ "GenSigTimeoutTime" BU_SG_REL_ L_ATCU_vMON SG_ 860 L_ATCU_Lib_MngrTempBufCnt 5000;
BA_ "Version" SG_ 860 L_ATCU_Lib_MngrTempBufCnt "23.11.10";
BA_ "Description" SG_ 860 L_ATCU_Lib_MngrIntakeBufCnt "This value only use for ATCU Library data monitoring (Only use before SOP)";
BA_ "GenSigSendType" SG_ 860 L_ATCU_Lib_MngrIntakeBufCnt 4;
BA_ "UserSigValidity" SG_ 860 L_ATCU_Lib_MngrIntakeBufCnt 0;
BA_REL_ "GenSigTimeoutTime" BU_SG_REL_ L_ATCU_vMON SG_ 860 L_ATCU_Lib_MngrIntakeBufCnt 5000;
BA_ "Version" SG_ 860 L_ATCU_Lib_MngrIntakeBufCnt "23.11.10";
BA_ "GenMsgSendType" BO_ 913 0;
BA_ "GenMsgCycleTime" BO_ 913 500;
BA_ "Description" SG_ 913 L_ATCU_Lib_ADSBlrVtgVal "This value only use for ATCU Library data monitoring (Only use before SOP)";
BA_ "GenSigSendType" SG_ 913 L_ATCU_Lib_ADSBlrVtgVal 4;
BA_ "UserSigValidity" SG_ 913 L_ATCU_Lib_ADSBlrVtgVal 0;
BA_REL_ "GenSigTimeoutTime" BU_SG_REL_ L_ATCU_vMON SG_ 913 L_ATCU_Lib_ADSBlrVtgVal 5000;
BA_ "Version" SG_ 913 L_ATCU_Lib_ADSBlrVtgVal "23.11.10";
BA_ "Description" SG_ 913 L_ATCU_Lib_ADSDEFDrState "This value only use for ATCU Library data monitoring (Only use before SOP)";
BA_ "GenSigSendType" SG_ 913 L_ATCU_Lib_ADSDEFDrState 4;
BA_ "UserSigValidity" SG_ 913 L_ATCU_Lib_ADSDEFDrState 0;
BA_REL_ "GenSigTimeoutTime" BU_SG_REL_ L_ATCU_vMON SG_ 913 L_ATCU_Lib_ADSDEFDrState 5000;
BA_ "Version" SG_ 913 L_ATCU_Lib_ADSDEFDrState "23.11.10";
BA_ "Description" SG_ 913 L_ATCU_Lib_ADSACDispPreHoldReq "This value only use for ATCU Library data monitoring (Only use before SOP)";
BA_ "GenSigSendType" SG_ 913 L_ATCU_Lib_ADSACDispPreHoldReq 4;
BA_ "UserSigValidity" SG_ 913 L_ATCU_Lib_ADSACDispPreHoldReq 0;
BA_REL_ "GenSigTimeoutTime" BU_SG_REL_ L_ATCU_vMON SG_ 913 L_ATCU_Lib_ADSACDispPreHoldReq 5000;
BA_ "Version" SG_ 913 L_ATCU_Lib_ADSACDispPreHoldReq "23.11.10";
BA_ "Description" SG_ 913 L_ATCU_Lib_ADSACForcedOnReq "This value only use for ATCU Library data monitoring (Only use before SOP)";
BA_ "GenSigSendType" SG_ 913 L_ATCU_Lib_ADSACForcedOnReq 4;
BA_ "UserSigValidity" SG_ 913 L_ATCU_Lib_ADSACForcedOnReq 0;
BA_REL_ "GenSigTimeoutTime" BU_SG_REL_ L_ATCU_vMON SG_ 913 L_ATCU_Lib_ADSACForcedOnReq 5000;
BA_ "Version" SG_ 913 L_ATCU_Lib_ADSACForcedOnReq "23.11.10";
BA_ "Description" SG_ 913 L_ATCU_Lib_ADSACState "This value only use for ATCU Library data monitoring (Only use before SOP)";
BA_ "GenSigSendType" SG_ 913 L_ATCU_Lib_ADSACState 4;
BA_ "UserSigValidity" SG_ 913 L_ATCU_Lib_ADSACState 0;
BA_REL_ "GenSigTimeoutTime" BU_SG_REL_ L_ATCU_vMON SG_ 913 L_ATCU_Lib_ADSACState 5000;
BA_ "Version" SG_ 913 L_ATCU_Lib_ADSACState "23.11.10";
BA_ "Description" SG_ 913 L_ATCU_Lib_ADSInhibitPIReq "This value only use for ATCU Library data monitoring (Only use before SOP)";
BA_ "GenSigSendType" SG_ 913 L_ATCU_Lib_ADSInhibitPIReq 4;
BA_ "UserSigValidity" SG_ 913 L_ATCU_Lib_ADSInhibitPIReq 0;
BA_REL_ "GenSigTimeoutTime" BU_SG_REL_ L_ATCU_vMON SG_ 913 L_ATCU_Lib_ADSInhibitPIReq 5000;
BA_ "Version" SG_ 913 L_ATCU_Lib_ADSInhibitPIReq "23.11.10";
BA_ "Description" SG_ 913 L_ATCU_Lib_ADSModPrfleChgReq "This value only use for ATCU Library data monitoring (Only use before SOP)";
BA_ "GenSigSendType" SG_ 913 L_ATCU_Lib_ADSModPrfleChgReq 4;
BA_ "UserSigValidity" SG_ 913 L_ATCU_Lib_ADSModPrfleChgReq 0;
BA_REL_ "GenSigTimeoutTime" BU_SG_REL_ L_ATCU_vMON SG_ 913 L_ATCU_Lib_ADSModPrfleChgReq 5000;
BA_ "Version" SG_ 913 L_ATCU_Lib_ADSModPrfleChgReq "23.11.10";
BA_ "Description" SG_ 913 L_ATCU_Lib_ADSIntakeState "This value only use for ATCU Library data monitoring (Only use before SOP)";
BA_ "GenSigSendType" SG_ 913 L_ATCU_Lib_ADSIntakeState 4;
BA_ "UserSigValidity" SG_ 913 L_ATCU_Lib_ADSIntakeState 0;
BA_REL_ "GenSigTimeoutTime" BU_SG_REL_ L_ATCU_vMON SG_ 913 L_ATCU_Lib_ADSIntakeState 5000;
BA_ "Version" SG_ 913 L_ATCU_Lib_ADSIntakeState "23.11.10";
BA_ "Description" SG_ 913 L_ATCU_Lib_ADSTempDrLmtState "This value only use for ATCU Library data monitoring (Only use before SOP)";
BA_ "GenSigSendType" SG_ 913 L_ATCU_Lib_ADSTempDrLmtState 4;
BA_ "UserSigValidity" SG_ 913 L_ATCU_Lib_ADSTempDrLmtState 0;
BA_REL_ "GenSigTimeoutTime" BU_SG_REL_ L_ATCU_vMON SG_ 913 L_ATCU_Lib_ADSTempDrLmtState 5000;
BA_ "Version" SG_ 913 L_ATCU_Lib_ADSTempDrLmtState "23.11.10";
BA_ "Description" SG_ 913 L_ATCU_Lib_ADSOpState "This value only use for ATCU Library data monitoring (Only use before SOP)";
BA_ "GenSigSendType" SG_ 913 L_ATCU_Lib_ADSOpState 4;
BA_ "UserSigValidity" SG_ 913 L_ATCU_Lib_ADSOpState 0;
BA_REL_ "GenSigTimeoutTime" BU_SG_REL_ L_ATCU_vMON SG_ 913 L_ATCU_Lib_ADSOpState 5000;
BA_ "Version" SG_ 913 L_ATCU_Lib_ADSOpState "23.11.10";
BA_ "Description" SG_ 913 L_ATCU_Lib_ADSSymState "This value only use for ATCU Library data monitoring (Only use before SOP)";
BA_ "GenSigSendType" SG_ 913 L_ATCU_Lib_ADSSymState 4;
BA_ "UserSigValidity" SG_ 913 L_ATCU_Lib_ADSSymState 0;
BA_REL_ "GenSigTimeoutTime" BU_SG_REL_ L_ATCU_vMON SG_ 913 L_ATCU_Lib_ADSSymState 5000;
BA_ "Version" SG_ 913 L_ATCU_Lib_ADSSymState "23.11.10";
BA_ "Description" SG_ 913 L_ATCU_Lib_ADSModState "This value only use for ATCU Library data monitoring (Only use before SOP)";
BA_ "GenSigSendType" SG_ 913 L_ATCU_Lib_ADSModState 4;
BA_ "UserSigValidity" SG_ 913 L_ATCU_Lib_ADSModState 0;
BA_REL_ "GenSigTimeoutTime" BU_SG_REL_ L_ATCU_vMON SG_ 913 L_ATCU_Lib_ADSModState 5000;
BA_ "Version" SG_ 913 L_ATCU_Lib_ADSModState "25.11.02";
BA_ "GenMsgSendType" BO_ 914 0;
BA_ "GenMsgCycleTime" BO_ 914 500;
BA_ "Description" SG_ 914 L_ATCU_Lib_PIIntakeState "This value only use for ATCU Library data monitoring (Only use before SOP)";
BA_ "GenSigSendType" SG_ 914 L_ATCU_Lib_PIIntakeState 4;
BA_ "UserSigValidity" SG_ 914 L_ATCU_Lib_PIIntakeState 0;
BA_REL_ "GenSigTimeoutTime" BU_SG_REL_ L_ATCU_vMON SG_ 914 L_ATCU_Lib_PIIntakeState 5000;
BA_ "Version" SG_ 914 L_ATCU_Lib_PIIntakeState "23.11.10";
BA_ "Description" SG_ 914 L_ATCU_Lib_AEWPOnReq "This value only use for ATCU Library data monitoring (Only use before SOP)";
BA_ "GenSigSendType" SG_ 914 L_ATCU_Lib_AEWPOnReq 4;
BA_ "UserSigValidity" SG_ 914 L_ATCU_Lib_AEWPOnReq 0;
BA_REL_ "GenSigTimeoutTime" BU_SG_REL_ L_ATCU_vMON SG_ 914 L_ATCU_Lib_AEWPOnReq 5000;
BA_ "Version" SG_ 914 L_ATCU_Lib_AEWPOnReq "23.11.10";
BA_ "Description" SG_ 914 L_ATCU_Lib_AEWPRPMVal "This value only use for ATCU Library data monitoring (Only use before SOP)";
BA_ "GenSigSendType" SG_ 914 L_ATCU_Lib_AEWPRPMVal 4;
BA_ "UserSigValidity" SG_ 914 L_ATCU_Lib_AEWPRPMVal 0;
BA_REL_ "GenSigTimeoutTime" BU_SG_REL_ L_ATCU_vMON SG_ 914 L_ATCU_Lib_AEWPRPMVal 5000;
BA_ "Version" SG_ 914 L_ATCU_Lib_AEWPRPMVal "23.11.10";
BA_ "Description" SG_ 914 L_ATCULib_AmbFilterResetOpState "This value only use for ATCU Library data monitoring (Only use before SOP)";
BA_ "GenSigSendType" SG_ 914 L_ATCULib_AmbFilterResetOpState 4;
BA_ "UserSigValidity" SG_ 914 L_ATCULib_AmbFilterResetOpState 0;
BA_REL_ "GenSigTimeoutTime" BU_SG_REL_ L_ATCU_vMON SG_ 914 L_ATCULib_AmbFilterResetOpState 5000;
BA_ "Version" SG_ 914 L_ATCULib_AmbFilterResetOpState "24.06.02";
BA_ "Description" SG_ 914 L_ATCULib_HVACIntlckHVActOffReq "This value only use for ATCU Library data monitoring (Only use before SOP)";
BA_ "GenSigSendType" SG_ 914 L_ATCULib_HVACIntlckHVActOffReq 4;
BA_ "UserSigValidity" SG_ 914 L_ATCULib_HVACIntlckHVActOffReq 0;
BA_REL_ "GenSigTimeoutTime" BU_SG_REL_ L_ATCU_vMON SG_ 914 L_ATCULib_HVACIntlckHVActOffReq 5000;
BA_ "Version" SG_ 914 L_ATCULib_HVACIntlckHVActOffReq "24.06.02";
BA_ "Description" SG_ 914 L_ATCULib_MainRlyProtectOpState "This value only use for ATCU Library data monitoring (Only use before SOP)";
BA_ "GenSigSendType" SG_ 914 L_ATCULib_MainRlyProtectOpState 4;
BA_ "UserSigValidity" SG_ 914 L_ATCULib_MainRlyProtectOpState 0;
BA_REL_ "GenSigTimeoutTime" BU_SG_REL_ L_ATCU_vMON SG_ 914 L_ATCULib_MainRlyProtectOpState 5000;
BA_ "Version" SG_ 914 L_ATCULib_MainRlyProtectOpState "24.06.02";
BA_ "Description" SG_ 914 L_ATCULib_ETCIntlckHVActOffReq "This value only use for ATCU Library data monitoring (Only use before SOP)";
BA_ "GenSigSendType" SG_ 914 L_ATCULib_ETCIntlckHVActOffReq 4;
BA_ "UserSigValidity" SG_ 914 L_ATCULib_ETCIntlckHVActOffReq 0;
BA_REL_ "GenSigTimeoutTime" BU_SG_REL_ L_ATCU_vMON SG_ 914 L_ATCULib_ETCIntlckHVActOffReq 5000;
BA_ "Version" SG_ 914 L_ATCULib_ETCIntlckHVActOffReq "24.06.02";
BA_ "Description" SG_ 914 L_ATCULib_SyncSwSta "This value only use for ATCU Library data monitoring (Only use before SOP)";
BA_ "GenSigSendType" SG_ 914 L_ATCULib_SyncSwSta 4;
BA_ "UserSigValidity" SG_ 914 L_ATCULib_SyncSwSta 0;
BA_REL_ "GenSigTimeoutTime" BU_SG_REL_ L_ATCU_vMON SG_ 914 L_ATCULib_SyncSwSta 5000;
BA_ "Version" SG_ 914 L_ATCULib_SyncSwSta "24.06.02";
BA_ "GenMsgSendType" BO_ 833 0;
BA_ "GenMsgCycleTime" BO_ 833 500;
BA_ "Description" SG_ 833 MON_DiagAct_DrvModDrLck "This value only use for ATCU Library data monitoring (Only use before SOP)";
BA_ "GenSigSendType" SG_ 833 MON_DiagAct_DrvModDrLck 4;
BA_ "UserSigValidity" SG_ 833 MON_DiagAct_DrvModDrLck 0;
BA_REL_ "GenSigTimeoutTime" BU_SG_REL_ L_ATCU SG_ 833 MON_DiagAct_DrvModDrLck 5000;
BA_ "Version" SG_ 833 MON_DiagAct_DrvModDrLck "25.05.04";
BA_ "Description" SG_ 833 MON_DiagAct_AstModDrOpnSrt "This value only use for ATCU Library data monitoring (Only use before SOP)";
BA_ "GenSigSendType" SG_ 833 MON_DiagAct_AstModDrOpnSrt 4;
BA_ "UserSigValidity" SG_ 833 MON_DiagAct_AstModDrOpnSrt 0;
BA_REL_ "GenSigTimeoutTime" BU_SG_REL_ L_ATCU SG_ 833 MON_DiagAct_AstModDrOpnSrt 5000;
BA_ "Version" SG_ 833 MON_DiagAct_AstModDrOpnSrt "25.05.04";
BA_ "Description" SG_ 833 MON_DiagAct_AstTmpDrOpnSrt "This value only use for ATCU Library data monitoring (Only use before SOP)";
BA_ "GenSigSendType" SG_ 833 MON_DiagAct_AstTmpDrOpnSrt 4;
BA_ "UserSigValidity" SG_ 833 MON_DiagAct_AstTmpDrOpnSrt 0;
BA_REL_ "GenSigTimeoutTime" BU_SG_REL_ L_ATCU SG_ 833 MON_DiagAct_AstTmpDrOpnSrt 5000;
BA_ "Version" SG_ 833 MON_DiagAct_AstTmpDrOpnSrt "25.05.04";
BA_ "Description" SG_ 833 MON_DiagAct_DrvTmpDrLck "This value only use for ATCU Library data monitoring (Only use before SOP)";
BA_ "GenSigSendType" SG_ 833 MON_DiagAct_DrvTmpDrLck 4;
BA_ "UserSigValidity" SG_ 833 MON_DiagAct_DrvTmpDrLck 0;
BA_REL_ "GenSigTimeoutTime" BU_SG_REL_ L_ATCU SG_ 833 MON_DiagAct_DrvTmpDrLck 5000;
BA_ "Version" SG_ 833 MON_DiagAct_DrvTmpDrLck "25.05.04";
BA_ "Description" SG_ 833 MON_DiagAct_AstTmpDrLck "This value only use for ATCU Library data monitoring (Only use before SOP)";
BA_ "GenSigSendType" SG_ 833 MON_DiagAct_AstTmpDrLck 4;
BA_ "UserSigValidity" SG_ 833 MON_DiagAct_AstTmpDrLck 0;
BA_REL_ "GenSigTimeoutTime" BU_SG_REL_ L_ATCU SG_ 833 MON_DiagAct_AstTmpDrLck 5000;
BA_ "Version" SG_ 833 MON_DiagAct_AstTmpDrLck "25.05.04";
BA_ "Description" SG_ 833 MON_DiagAct_DrvModDrOpnSrt "This value only use for ATCU Library data monitoring (Only use before SOP)";
BA_ "GenSigSendType" SG_ 833 MON_DiagAct_DrvModDrOpnSrt 4;
BA_ "UserSigValidity" SG_ 833 MON_DiagAct_DrvModDrOpnSrt 0;
BA_REL_ "GenSigTimeoutTime" BU_SG_REL_ L_ATCU SG_ 833 MON_DiagAct_DrvModDrOpnSrt 5000;
BA_ "Version" SG_ 833 MON_DiagAct_DrvModDrOpnSrt "25.05.04";
BA_ "Description" SG_ 833 MON_DiagAct_DEFDrLck "This value only use for ATCU Library data monitoring (Only use before SOP)";
BA_ "GenSigSendType" SG_ 833 MON_DiagAct_DEFDrLck 4;
BA_ "UserSigValidity" SG_ 833 MON_DiagAct_DEFDrLck 0;
BA_REL_ "GenSigTimeoutTime" BU_SG_REL_ L_ATCU SG_ 833 MON_DiagAct_DEFDrLck 5000;
BA_ "Version" SG_ 833 MON_DiagAct_DEFDrLck "25.05.04";
BA_ "Description" SG_ 833 MON_DiagAct_IntakeDrLck "This value only use for ATCU Library data monitoring (Only use before SOP)";
BA_ "GenSigSendType" SG_ 833 MON_DiagAct_IntakeDrLck 4;
BA_ "UserSigValidity" SG_ 833 MON_DiagAct_IntakeDrLck 0;
BA_REL_ "GenSigTimeoutTime" BU_SG_REL_ L_ATCU SG_ 833 MON_DiagAct_IntakeDrLck 5000;
BA_ "Version" SG_ 833 MON_DiagAct_IntakeDrLck "25.05.04";
BA_ "Description" SG_ 833 MON_DiagAct_IntakeDrOpnSrt "This value only use for ATCU Library data monitoring (Only use before SOP)";
BA_ "GenSigSendType" SG_ 833 MON_DiagAct_IntakeDrOpnSrt 4;
BA_ "UserSigValidity" SG_ 833 MON_DiagAct_IntakeDrOpnSrt 0;
BA_REL_ "GenSigTimeoutTime" BU_SG_REL_ L_ATCU SG_ 833 MON_DiagAct_IntakeDrOpnSrt 5000;
BA_ "Version" SG_ 833 MON_DiagAct_IntakeDrOpnSrt "25.05.04";
BA_ "Description" SG_ 833 MON_DiagAct_DEFDrOpnSrt "This value only use for ATCU Library data monitoring (Only use before SOP)";
BA_ "GenSigSendType" SG_ 833 MON_DiagAct_DEFDrOpnSrt 4;
BA_ "UserSigValidity" SG_ 833 MON_DiagAct_DEFDrOpnSrt 0;
BA_REL_ "GenSigTimeoutTime" BU_SG_REL_ L_ATCU SG_ 833 MON_DiagAct_DEFDrOpnSrt 5000;
BA_ "Version" SG_ 833 MON_DiagAct_DEFDrOpnSrt "25.05.04";
BA_ "Description" SG_ 833 MON_DiagAct_ECompIntlck "This value only use for ATCU Library data monitoring (Only use before SOP)";
BA_ "GenSigSendType" SG_ 833 MON_DiagAct_ECompIntlck 4;
BA_ "UserSigValidity" SG_ 833 MON_DiagAct_ECompIntlck 0;
BA_REL_ "GenSigTimeoutTime" BU_SG_REL_ L_ATCU SG_ 833 MON_DiagAct_ECompIntlck 5000;
BA_ "Version" SG_ 833 MON_DiagAct_ECompIntlck "25.05.04";
BA_ "Description" SG_ 833 MON_DiagAct_HVPTCIntlck "This value only use for ATCU Library data monitoring (Only use before SOP)";
BA_ "GenSigSendType" SG_ 833 MON_DiagAct_HVPTCIntlck 4;
BA_ "UserSigValidity" SG_ 833 MON_DiagAct_HVPTCIntlck 0;
BA_REL_ "GenSigTimeoutTime" BU_SG_REL_ L_ATCU SG_ 833 MON_DiagAct_HVPTCIntlck 5000;
BA_ "Version" SG_ 833 MON_DiagAct_HVPTCIntlck "25.05.04";
BA_ "Description" SG_ 833 MON_DiagAct_BatChlrEXVOpnSrt "This value only use for ATCU Library data monitoring (Only use before SOP)";
BA_ "GenSigSendType" SG_ 833 MON_DiagAct_BatChlrEXVOpnSrt 4;
BA_ "UserSigValidity" SG_ 833 MON_DiagAct_BatChlrEXVOpnSrt 0;
BA_REL_ "GenSigTimeoutTime" BU_SG_REL_ L_ATCU SG_ 833 MON_DiagAct_BatChlrEXVOpnSrt 5000;
BA_ "Version" SG_ 833 MON_DiagAct_BatChlrEXVOpnSrt "25.05.04";
BA_ "Description" SG_ 833 MON_DiagAct_EvapTXVOpnSrt "This value only use for ATCU Library data monitoring (Only use before SOP)";
BA_ "GenSigSendType" SG_ 833 MON_DiagAct_EvapTXVOpnSrt 4;
BA_ "UserSigValidity" SG_ 833 MON_DiagAct_EvapTXVOpnSrt 0;
BA_REL_ "GenSigTimeoutTime" BU_SG_REL_ L_ATCU SG_ 833 MON_DiagAct_EvapTXVOpnSrt 5000;
BA_ "Version" SG_ 833 MON_DiagAct_EvapTXVOpnSrt "25.05.04";
BA_ "Description" SG_ 833 MON_DiagAct_FrtPWMBlr "This value only use for ATCU Library data monitoring (Only use before SOP)";
BA_ "GenSigSendType" SG_ 833 MON_DiagAct_FrtPWMBlr 4;
BA_ "UserSigValidity" SG_ 833 MON_DiagAct_FrtPWMBlr 0;
BA_REL_ "GenSigTimeoutTime" BU_SG_REL_ L_ATCU SG_ 833 MON_DiagAct_FrtPWMBlr 5000;
BA_ "Version" SG_ 833 MON_DiagAct_FrtPWMBlr "25.05.04";
BA_ "Description" SG_ 833 MON_DiagAct_ECV "This value only use for ATCU Library data monitoring (Only use before SOP)";
BA_ "GenSigSendType" SG_ 833 MON_DiagAct_ECV 4;
BA_ "UserSigValidity" SG_ 833 MON_DiagAct_ECV 0;
BA_REL_ "GenSigTimeoutTime" BU_SG_REL_ L_ATCU SG_ 833 MON_DiagAct_ECV 5000;
BA_ "Version" SG_ 833 MON_DiagAct_ECV "25.05.04";
BA_ "Description" SG_ 833 MON_DiagAct_Rfgrant "This value only use for ATCU Library data monitoring (Only use before SOP)";
BA_ "GenSigSendType" SG_ 833 MON_DiagAct_Rfgrant 4;
BA_ "UserSigValidity" SG_ 833 MON_DiagAct_Rfgrant 0;
BA_REL_ "GenSigTimeoutTime" BU_SG_REL_ L_ATCU SG_ 833 MON_DiagAct_Rfgrant 5000;
BA_ "Version" SG_ 833 MON_DiagAct_Rfgrant "25.05.04";
BA_ "Description" SG_ 833 MON_DiagAct_DrvTmpDrOpnSrt "This value only use for ATCU Library data monitoring (Only use before SOP)";
BA_ "GenSigSendType" SG_ 833 MON_DiagAct_DrvTmpDrOpnSrt 4;
BA_ "UserSigValidity" SG_ 833 MON_DiagAct_DrvTmpDrOpnSrt 0;
BA_REL_ "GenSigTimeoutTime" BU_SG_REL_ L_ATCU SG_ 833 MON_DiagAct_DrvTmpDrOpnSrt 5000;
BA_ "Version" SG_ 833 MON_DiagAct_DrvTmpDrOpnSrt "25.05.04";
BA_ "Description" SG_ 833 MON_DiagAct_VRLed "This value only use for ATCU Library data monitoring (Only use before SOP)";
BA_ "GenSigSendType" SG_ 833 MON_DiagAct_VRLed 4;
BA_ "UserSigValidity" SG_ 833 MON_DiagAct_VRLed 0;
BA_REL_ "GenSigTimeoutTime" BU_SG_REL_ L_ATCU SG_ 833 MON_DiagAct_VRLed 5000;
BA_ "Version" SG_ 833 MON_DiagAct_VRLed "25.05.04";
BA_ "Description" SG_ 833 MON_DiagAct_AstModDrLck "This value only use for ATCU Library data monitoring (Only use before SOP)";
BA_ "GenSigSendType" SG_ 833 MON_DiagAct_AstModDrLck 4;
BA_ "UserSigValidity" SG_ 833 MON_DiagAct_AstModDrLck 0;
BA_REL_ "GenSigTimeoutTime" BU_SG_REL_ L_ATCU SG_ 833 MON_DiagAct_AstModDrLck 5000;
BA_ "Version" SG_ 833 MON_DiagAct_AstModDrLck "25.05.04";
BA_ "GenMsgSendType" BO_ 834 0;
BA_ "GenMsgCycleTime" BO_ 834 500;
BA_ "Description" SG_ 834 MON_DiagCOM_AcnOpPerm "This value only use for ATCU Library data monitoring (Only use before SOP)";
BA_ "GenSigSendType" SG_ 834 MON_DiagCOM_AcnOpPerm 4;
BA_ "UserSigValidity" SG_ 834 MON_DiagCOM_AcnOpPerm 0;
BA_REL_ "GenSigTimeoutTime" BU_SG_REL_ L_ATCU SG_ 834 MON_DiagCOM_AcnOpPerm 5000;
BA_ "Version" SG_ 834 MON_DiagCOM_AcnOpPerm "25.05.04";
BA_ "Description" SG_ 834 MON_DiagCOM_BMSTmout "This value only use for ATCU Library data monitoring (Only use before SOP)";
BA_ "GenSigSendType" SG_ 834 MON_DiagCOM_BMSTmout 4;
BA_ "UserSigValidity" SG_ 834 MON_DiagCOM_BMSTmout 0;
BA_REL_ "GenSigTimeoutTime" BU_SG_REL_ L_ATCU SG_ 834 MON_DiagCOM_BMSTmout 5000;
BA_ "Version" SG_ 834 MON_DiagCOM_BMSTmout "25.05.04";
BA_ "Description" SG_ 834 MON_DiagCOM_DrvClHtStOpt "This value only use for ATCU Library data monitoring (Only use before SOP)";
BA_ "GenSigSendType" SG_ 834 MON_DiagCOM_DrvClHtStOpt 4;
BA_ "UserSigValidity" SG_ 834 MON_DiagCOM_DrvClHtStOpt 0;
BA_REL_ "GenSigTimeoutTime" BU_SG_REL_ L_ATCU SG_ 834 MON_DiagCOM_DrvClHtStOpt 5000;
BA_ "Version" SG_ 834 MON_DiagCOM_DrvClHtStOpt "25.05.04";
BA_ "Description" SG_ 834 MON_DiagCOM_AstClHtStOpt "This value only use for ATCU Library data monitoring (Only use before SOP)";
BA_ "GenSigSendType" SG_ 834 MON_DiagCOM_AstClHtStOpt 4;
BA_ "UserSigValidity" SG_ 834 MON_DiagCOM_AstClHtStOpt 0;
BA_REL_ "GenSigTimeoutTime" BU_SG_REL_ L_ATCU SG_ 834 MON_DiagCOM_AstClHtStOpt 5000;
BA_ "Version" SG_ 834 MON_DiagCOM_AstClHtStOpt "25.05.04";
BA_ "Description" SG_ 834 MON_DiagCOM_EcoModSw "This value only use for ATCU Library data monitoring (Only use before SOP)";
BA_ "GenSigSendType" SG_ 834 MON_DiagCOM_EcoModSw 4;
BA_ "UserSigValidity" SG_ 834 MON_DiagCOM_EcoModSw 0;
BA_REL_ "GenSigTimeoutTime" BU_SG_REL_ L_ATCU SG_ 834 MON_DiagCOM_EcoModSw 5000;
BA_ "Version" SG_ 834 MON_DiagCOM_EcoModSw "25.05.04";
BA_ "Description" SG_ 834 MON_DiagCOM_EcompTmout "This value only use for ATCU Library data monitoring (Only use before SOP)";
BA_ "GenSigSendType" SG_ 834 MON_DiagCOM_EcompTmout 4;
BA_ "UserSigValidity" SG_ 834 MON_DiagCOM_EcompTmout 0;
BA_REL_ "GenSigTimeoutTime" BU_SG_REL_ L_ATCU SG_ 834 MON_DiagCOM_EcompTmout 5000;
BA_ "Version" SG_ 834 MON_DiagCOM_EcompTmout "25.05.04";
BA_ "Description" SG_ 834 MON_DiagCOM_APT "This value only use for ATCU Library data monitoring (Only use before SOP)";
BA_ "GenSigSendType" SG_ 834 MON_DiagCOM_APT 4;
BA_ "UserSigValidity" SG_ 834 MON_DiagCOM_APT 0;
BA_REL_ "GenSigTimeoutTime" BU_SG_REL_ L_ATCU SG_ 834 MON_DiagCOM_APT 5000;
BA_ "Version" SG_ 834 MON_DiagCOM_APT "25.05.04";
BA_ "Description" SG_ 834 MON_DiagCOM_EMSVehSpd "This value only use for ATCU Library data monitoring (Only use before SOP)";
BA_ "GenSigSendType" SG_ 834 MON_DiagCOM_EMSVehSpd 4;
BA_ "UserSigValidity" SG_ 834 MON_DiagCOM_EMSVehSpd 0;
BA_REL_ "GenSigTimeoutTime" BU_SG_REL_ L_ATCU SG_ 834 MON_DiagCOM_EMSVehSpd 5000;
BA_ "Version" SG_ 834 MON_DiagCOM_EMSVehSpd "25.05.04";
BA_ "Description" SG_ 834 MON_DiagCOM_EngCool "This value only use for ATCU Library data monitoring (Only use before SOP)";
BA_ "GenSigSendType" SG_ 834 MON_DiagCOM_EngCool 4;
BA_ "UserSigValidity" SG_ 834 MON_DiagCOM_EngCool 0;
BA_REL_ "GenSigTimeoutTime" BU_SG_REL_ L_ATCU SG_ 834 MON_DiagCOM_EngCool 5000;
BA_ "Version" SG_ 834 MON_DiagCOM_EngCool "25.05.04";
BA_ "Description" SG_ 834 MON_DiagCOM_EngOpMod "This value only use for ATCU Library data monitoring (Only use before SOP)";
BA_ "GenSigSendType" SG_ 834 MON_DiagCOM_EngOpMod 4;
BA_ "UserSigValidity" SG_ 834 MON_DiagCOM_EngOpMod 0;
BA_REL_ "GenSigTimeoutTime" BU_SG_REL_ L_ATCU SG_ 834 MON_DiagCOM_EngOpMod 5000;
BA_ "Version" SG_ 834 MON_DiagCOM_EngOpMod "25.05.04";
BA_ "Description" SG_ 834 MON_DiagCOM_HEVRdy "This value only use for ATCU Library data monitoring (Only use before SOP)";
BA_ "GenSigSendType" SG_ 834 MON_DiagCOM_HEVRdy 4;
BA_ "UserSigValidity" SG_ 834 MON_DiagCOM_HEVRdy 0;
BA_REL_ "GenSigTimeoutTime" BU_SG_REL_ L_ATCU SG_ 834 MON_DiagCOM_HEVRdy 5000;
BA_ "Version" SG_ 834 MON_DiagCOM_HEVRdy "25.05.04";
BA_ "Description" SG_ 834 MON_DiagCOM_HVPTCTmout "This value only use for ATCU Library data monitoring (Only use before SOP)";
BA_ "GenSigSendType" SG_ 834 MON_DiagCOM_HVPTCTmout 4;
BA_ "UserSigValidity" SG_ 834 MON_DiagCOM_HVPTCTmout 0;
BA_REL_ "GenSigTimeoutTime" BU_SG_REL_ L_ATCU SG_ 834 MON_DiagCOM_HVPTCTmout 5000;
BA_ "Version" SG_ 834 MON_DiagCOM_HVPTCTmout "25.05.04";
BA_ "Description" SG_ 834 MON_DiagCOM_LDCWatt "This value only use for ATCU Library data monitoring (Only use before SOP)";
BA_ "GenSigSendType" SG_ 834 MON_DiagCOM_LDCWatt 4;
BA_ "UserSigValidity" SG_ 834 MON_DiagCOM_LDCWatt 0;
BA_REL_ "GenSigTimeoutTime" BU_SG_REL_ L_ATCU SG_ 834 MON_DiagCOM_LDCWatt 5000;
BA_ "Version" SG_ 834 MON_DiagCOM_LDCWatt "25.05.04";
BA_ "Description" SG_ 834 MON_DiagCOM_LHPhoto "This value only use for ATCU Library data monitoring (Only use before SOP)";
BA_ "GenSigSendType" SG_ 834 MON_DiagCOM_LHPhoto 4;
BA_ "UserSigValidity" SG_ 834 MON_DiagCOM_LHPhoto 0;
BA_REL_ "GenSigTimeoutTime" BU_SG_REL_ L_ATCU SG_ 834 MON_DiagCOM_LHPhoto 5000;
BA_ "Version" SG_ 834 MON_DiagCOM_LHPhoto "25.05.04";
BA_ "Description" SG_ 834 MON_DiagCOM_MainRlyOnSta "This value only use for ATCU Library data monitoring (Only use before SOP)";
BA_ "GenSigSendType" SG_ 834 MON_DiagCOM_MainRlyOnSta 4;
BA_ "UserSigValidity" SG_ 834 MON_DiagCOM_MainRlyOnSta 0;
BA_REL_ "GenSigTimeoutTime" BU_SG_REL_ L_ATCU SG_ 834 MON_DiagCOM_MainRlyOnSta 5000;
BA_ "Version" SG_ 834 MON_DiagCOM_MainRlyOnSta "25.05.04";
BA_ "Description" SG_ 834 MON_DiagCOM_MCUTmout "This value only use for ATCU Library data monitoring (Only use before SOP)";
BA_ "GenSigSendType" SG_ 834 MON_DiagCOM_MCUTmout 4;
BA_ "UserSigValidity" SG_ 834 MON_DiagCOM_MCUTmout 0;
BA_REL_ "GenSigTimeoutTime" BU_SG_REL_ L_ATCU SG_ 834 MON_DiagCOM_MCUTmout 5000;
BA_ "Version" SG_ 834 MON_DiagCOM_MCUTmout "25.05.04";
BA_ "Description" SG_ 834 MON_DiagCOM_PMSnsr "This value only use for ATCU Library data monitoring (Only use before SOP)";
BA_ "GenSigSendType" SG_ 834 MON_DiagCOM_PMSnsr 4;
BA_ "UserSigValidity" SG_ 834 MON_DiagCOM_PMSnsr 0;
BA_REL_ "GenSigTimeoutTime" BU_SG_REL_ L_ATCU SG_ 834 MON_DiagCOM_PMSnsr 5000;
BA_ "Version" SG_ 834 MON_DiagCOM_PMSnsr "25.05.04";
BA_ "Description" SG_ 834 MON_DiagCOM_BatChlrEXVDiag "This value only use for ATCU Library data monitoring (Only use before SOP)";
BA_ "GenSigSendType" SG_ 834 MON_DiagCOM_BatChlrEXVDiag 4;
BA_ "UserSigValidity" SG_ 834 MON_DiagCOM_BatChlrEXVDiag 0;
BA_REL_ "GenSigTimeoutTime" BU_SG_REL_ L_ATCU SG_ 834 MON_DiagCOM_BatChlrEXVDiag 5000;
BA_ "Version" SG_ 834 MON_DiagCOM_BatChlrEXVDiag "25.05.04";
BA_ "Description" SG_ 834 MON_DiagCOM_PnlBusOff "This value only use for ATCU Library data monitoring (Only use before SOP)";
BA_ "GenSigSendType" SG_ 834 MON_DiagCOM_PnlBusOff 4;
BA_ "UserSigValidity" SG_ 834 MON_DiagCOM_PnlBusOff 0;
BA_REL_ "GenSigTimeoutTime" BU_SG_REL_ L_ATCU SG_ 834 MON_DiagCOM_PnlBusOff 5000;
BA_ "Version" SG_ 834 MON_DiagCOM_PnlBusOff "25.05.04";
BA_ "Description" SG_ 834 MON_DiagCOM_PTGOpt "This value only use for ATCU Library data monitoring (Only use before SOP)";
BA_ "GenSigSendType" SG_ 834 MON_DiagCOM_PTGOpt 4;
BA_ "UserSigValidity" SG_ 834 MON_DiagCOM_PTGOpt 0;
BA_REL_ "GenSigTimeoutTime" BU_SG_REL_ L_ATCU SG_ 834 MON_DiagCOM_PTGOpt 5000;
BA_ "Version" SG_ 834 MON_DiagCOM_PTGOpt "25.05.04";
BA_ "Description" SG_ 834 MON_DiagCOM_RHPhoto "This value only use for ATCU Library data monitoring (Only use before SOP)";
BA_ "GenSigSendType" SG_ 834 MON_DiagCOM_RHPhoto 4;
BA_ "UserSigValidity" SG_ 834 MON_DiagCOM_RHPhoto 0;
BA_REL_ "GenSigTimeoutTime" BU_SG_REL_ L_ATCU SG_ 834 MON_DiagCOM_RHPhoto 5000;
BA_ "Version" SG_ 834 MON_DiagCOM_RHPhoto "25.05.04";
BA_ "Description" SG_ 834 MON_DiagCOM_RPM "This value only use for ATCU Library data monitoring (Only use before SOP)";
BA_ "GenSigSendType" SG_ 834 MON_DiagCOM_RPM 4;
BA_ "UserSigValidity" SG_ 834 MON_DiagCOM_RPM 0;
BA_REL_ "GenSigTimeoutTime" BU_SG_REL_ L_ATCU SG_ 834 MON_DiagCOM_RPM 5000;
BA_ "Version" SG_ 834 MON_DiagCOM_RPM "25.05.04";
BA_ "Description" SG_ 834 MON_DiagCOM_SideMirAmb "This value only use for ATCU Library data monitoring (Only use before SOP)";
BA_ "GenSigSendType" SG_ 834 MON_DiagCOM_SideMirAmb 4;
BA_ "UserSigValidity" SG_ 834 MON_DiagCOM_SideMirAmb 0;
BA_REL_ "GenSigTimeoutTime" BU_SG_REL_ L_ATCU SG_ 834 MON_DiagCOM_SideMirAmb 5000;
BA_ "Version" SG_ 834 MON_DiagCOM_SideMirAmb "25.05.04";
BA_ "Description" SG_ 834 MON_DiagCOM_ServiceMod "This value only use for ATCU Library data monitoring (Only use before SOP)";
BA_ "GenSigSendType" SG_ 834 MON_DiagCOM_ServiceMod 4;
BA_ "UserSigValidity" SG_ 834 MON_DiagCOM_ServiceMod 0;
BA_REL_ "GenSigTimeoutTime" BU_SG_REL_ L_ATCU SG_ 834 MON_DiagCOM_ServiceMod 5000;
BA_ "Version" SG_ 834 MON_DiagCOM_ServiceMod "25.05.04";
BA_ "Description" SG_ 834 MON_DiagCOM_StrHtOpt "This value only use for ATCU Library data monitoring (Only use before SOP)";
BA_ "GenSigSendType" SG_ 834 MON_DiagCOM_StrHtOpt 4;
BA_ "UserSigValidity" SG_ 834 MON_DiagCOM_StrHtOpt 0;
BA_REL_ "GenSigTimeoutTime" BU_SG_REL_ L_ATCU SG_ 834 MON_DiagCOM_StrHtOpt 5000;
BA_ "Version" SG_ 834 MON_DiagCOM_StrHtOpt "25.05.04";
BA_ "Description" SG_ 834 MON_DiagCOM_TCUVehSpd "This value only use for ATCU Library data monitoring (Only use before SOP)";
BA_ "GenSigSendType" SG_ 834 MON_DiagCOM_TCUVehSpd 4;
BA_ "UserSigValidity" SG_ 834 MON_DiagCOM_TCUVehSpd 0;
BA_REL_ "GenSigTimeoutTime" BU_SG_REL_ L_ATCU SG_ 834 MON_DiagCOM_TCUVehSpd 5000;
BA_ "Version" SG_ 834 MON_DiagCOM_TCUVehSpd "25.05.04";
BA_ "Description" SG_ 834 MON_DiagCOM_Torque "This value only use for ATCU Library data monitoring (Only use before SOP)";
BA_ "GenSigSendType" SG_ 834 MON_DiagCOM_Torque 4;
BA_ "UserSigValidity" SG_ 834 MON_DiagCOM_Torque 0;
BA_REL_ "GenSigTimeoutTime" BU_SG_REL_ L_ATCU SG_ 834 MON_DiagCOM_Torque 5000;
BA_ "Version" SG_ 834 MON_DiagCOM_Torque "25.05.04";
BA_ "Description" SG_ 834 MON_DiagCOM_VehBusOff "This value only use for ATCU Library data monitoring (Only use before SOP)";
BA_ "GenSigSendType" SG_ 834 MON_DiagCOM_VehBusOff 4;
BA_ "UserSigValidity" SG_ 834 MON_DiagCOM_VehBusOff 0;
BA_REL_ "GenSigTimeoutTime" BU_SG_REL_ L_ATCU SG_ 834 MON_DiagCOM_VehBusOff 5000;
BA_ "Version" SG_ 834 MON_DiagCOM_VehBusOff "25.05.04";
BA_ "Description" SG_ 834 MON_DiagCOM_BATSoc "This value only use for ATCU Library data monitoring (Only use before SOP)";
BA_ "GenSigSendType" SG_ 834 MON_DiagCOM_BATSoc 4;
BA_ "UserSigValidity" SG_ 834 MON_DiagCOM_BATSoc 0;
BA_REL_ "GenSigTimeoutTime" BU_SG_REL_ L_ATCU SG_ 834 MON_DiagCOM_BATSoc 5000;
BA_ "Version" SG_ 834 MON_DiagCOM_BATSoc "25.05.04";
BA_ "Description" SG_ 834 MON_DiagCOM_WhlSpd "This value only use for ATCU Library data monitoring (Only use before SOP)";
BA_ "GenSigSendType" SG_ 834 MON_DiagCOM_WhlSpd 4;
BA_ "UserSigValidity" SG_ 834 MON_DiagCOM_WhlSpd 0;
BA_REL_ "GenSigTimeoutTime" BU_SG_REL_ L_ATCU SG_ 834 MON_DiagCOM_WhlSpd 5000;
BA_ "Version" SG_ 834 MON_DiagCOM_WhlSpd "25.05.04";
BA_ "Description" SG_ 834 MON_DiagCOM_ClmtBusOff "This value only use for ATCU Library data monitoring (Only use before SOP)";
BA_ "GenSigSendType" SG_ 834 MON_DiagCOM_ClmtBusOff 4;
BA_ "UserSigValidity" SG_ 834 MON_DiagCOM_ClmtBusOff 0;
BA_REL_ "GenSigTimeoutTime" BU_SG_REL_ L_ATCU SG_ 834 MON_DiagCOM_ClmtBusOff 5000;
BA_ "Version" SG_ 834 MON_DiagCOM_ClmtBusOff "25.05.04";
BA_ "Description" SG_ 834 MON_DiagCOM_BMSIntakeReq "This value only use for ATCU Library data monitoring (Only use before SOP)";
BA_ "GenSigSendType" SG_ 834 MON_DiagCOM_BMSIntakeReq 4;
BA_ "UserSigValidity" SG_ 834 MON_DiagCOM_BMSIntakeReq 0;
BA_REL_ "GenSigTimeoutTime" BU_SG_REL_ L_ATCU SG_ 834 MON_DiagCOM_BMSIntakeReq 5000;
BA_ "Version" SG_ 834 MON_DiagCOM_BMSIntakeReq "25.05.04";
BA_ "GenMsgSendType" BO_ 835 0;
BA_ "GenMsgCycleTime" BO_ 835 500;
BA_ "Description" SG_ 835 MON_DiagSnsr_AMBTmp "This value only use for ATCU Library data monitoring (Only use before SOP)";
BA_ "GenSigSendType" SG_ 835 MON_DiagSnsr_AMBTmp 4;
BA_ "UserSigValidity" SG_ 835 MON_DiagSnsr_AMBTmp 0;
BA_REL_ "GenSigTimeoutTime" BU_SG_REL_ L_ATCU SG_ 835 MON_DiagSnsr_AMBTmp 5000;
BA_ "Version" SG_ 835 MON_DiagSnsr_AMBTmp "25.05.04";
BA_ "Description" SG_ 835 MON_DiagSnsr_DEFDuctTmp "This value only use for ATCU Library data monitoring (Only use before SOP)";
BA_ "GenSigSendType" SG_ 835 MON_DiagSnsr_DEFDuctTmp 4;
BA_ "UserSigValidity" SG_ 835 MON_DiagSnsr_DEFDuctTmp 0;
BA_REL_ "GenSigTimeoutTime" BU_SG_REL_ L_ATCU SG_ 835 MON_DiagSnsr_DEFDuctTmp 5000;
BA_ "Version" SG_ 835 MON_DiagSnsr_DEFDuctTmp "25.05.04";
BA_ "Description" SG_ 835 MON_DiagSnsr_DOH "This value only use for ATCU Library data monitoring (Only use before SOP)";
BA_ "GenSigSendType" SG_ 835 MON_DiagSnsr_DOH 4;
BA_ "UserSigValidity" SG_ 835 MON_DiagSnsr_DOH 0;
BA_REL_ "GenSigTimeoutTime" BU_SG_REL_ L_ATCU SG_ 835 MON_DiagSnsr_DOH 5000;
BA_ "Version" SG_ 835 MON_DiagSnsr_DOH "25.05.04";
BA_ "Description" SG_ 835 MON_DiagSnsr_DrvFlrDuctTmp "This value only use for ATCU Library data monitoring (Only use before SOP)";
BA_ "GenSigSendType" SG_ 835 MON_DiagSnsr_DrvFlrDuctTmp 4;
BA_ "UserSigValidity" SG_ 835 MON_DiagSnsr_DrvFlrDuctTmp 0;
BA_REL_ "GenSigTimeoutTime" BU_SG_REL_ L_ATCU SG_ 835 MON_DiagSnsr_DrvFlrDuctTmp 5000;
BA_ "Version" SG_ 835 MON_DiagSnsr_DrvFlrDuctTmp "25.05.04";
BA_ "Description" SG_ 835 MON_DiagSnsr_DrvVntDuctTmp "This value only use for ATCU Library data monitoring (Only use before SOP)";
BA_ "GenSigSendType" SG_ 835 MON_DiagSnsr_DrvVntDuctTmp 4;
BA_ "UserSigValidity" SG_ 835 MON_DiagSnsr_DrvVntDuctTmp 0;
BA_REL_ "GenSigTimeoutTime" BU_SG_REL_ L_ATCU SG_ 835 MON_DiagSnsr_DrvVntDuctTmp 5000;
BA_ "Version" SG_ 835 MON_DiagSnsr_DrvVntDuctTmp "25.05.04";
BA_ "Description" SG_ 835 MON_DiagSnsr_EvapTmp "This value only use for ATCU Library data monitoring (Only use before SOP)";
BA_ "GenSigSendType" SG_ 835 MON_DiagSnsr_EvapTmp 4;
BA_ "UserSigValidity" SG_ 835 MON_DiagSnsr_EvapTmp 0;
BA_REL_ "GenSigTimeoutTime" BU_SG_REL_ L_ATCU SG_ 835 MON_DiagSnsr_EvapTmp 5000;
BA_ "Version" SG_ 835 MON_DiagSnsr_EvapTmp "25.05.04";
BA_ "Description" SG_ 835 MON_DiagSnsr_AstFlrDuctTmp "This value only use for ATCU Library data monitoring (Only use before SOP)";
BA_ "GenSigSendType" SG_ 835 MON_DiagSnsr_AstFlrDuctTmp 4;
BA_ "UserSigValidity" SG_ 835 MON_DiagSnsr_AstFlrDuctTmp 0;
BA_REL_ "GenSigTimeoutTime" BU_SG_REL_ L_ATCU SG_ 835 MON_DiagSnsr_AstFlrDuctTmp 5000;
BA_ "Version" SG_ 835 MON_DiagSnsr_AstFlrDuctTmp "25.05.04";
BA_ "Description" SG_ 835 MON_DiagSnsr_FDust "This value only use for ATCU Library data monitoring (Only use before SOP)";
BA_ "GenSigSendType" SG_ 835 MON_DiagSnsr_FDust 4;
BA_ "UserSigValidity" SG_ 835 MON_DiagSnsr_FDust 0;
BA_REL_ "GenSigTimeoutTime" BU_SG_REL_ L_ATCU SG_ 835 MON_DiagSnsr_FDust 5000;
BA_ "Version" SG_ 835 MON_DiagSnsr_FDust "25.05.04";
BA_ "Description" SG_ 835 MON_DiagSnsr_HghPrsrRfgPT "This value only use for ATCU Library data monitoring (Only use before SOP)";
BA_ "GenSigSendType" SG_ 835 MON_DiagSnsr_HghPrsrRfgPT 4;
BA_ "UserSigValidity" SG_ 835 MON_DiagSnsr_HghPrsrRfgPT 0;
BA_REL_ "GenSigTimeoutTime" BU_SG_REL_ L_ATCU SG_ 835 MON_DiagSnsr_HghPrsrRfgPT 5000;
BA_ "Version" SG_ 835 MON_DiagSnsr_HghPrsrRfgPT "25.05.04";
BA_ "Description" SG_ 835 MON_DiagSnsr_InCarTmp "This value only use for ATCU Library data monitoring (Only use before SOP)";
BA_ "GenSigSendType" SG_ 835 MON_DiagSnsr_InCarTmp 4;
BA_ "UserSigValidity" SG_ 835 MON_DiagSnsr_InCarTmp 0;
BA_REL_ "GenSigTimeoutTime" BU_SG_REL_ L_ATCU SG_ 835 MON_DiagSnsr_InCarTmp 5000;
BA_ "Version" SG_ 835 MON_DiagSnsr_InCarTmp "25.05.04";
BA_ "Description" SG_ 835 MON_DiagSnsr_LHPhoto "This value only use for ATCU Library data monitoring (Only use before SOP)";
BA_ "GenSigSendType" SG_ 835 MON_DiagSnsr_LHPhoto 4;
BA_ "UserSigValidity" SG_ 835 MON_DiagSnsr_LHPhoto 0;
BA_REL_ "GenSigTimeoutTime" BU_SG_REL_ L_ATCU SG_ 835 MON_DiagSnsr_LHPhoto 5000;
BA_ "Version" SG_ 835 MON_DiagSnsr_LHPhoto "25.05.04";
BA_ "Description" SG_ 835 MON_DiagSnsr_LowPrsrRfgPT "This value only use for ATCU Library data monitoring (Only use before SOP)";
BA_ "GenSigSendType" SG_ 835 MON_DiagSnsr_LowPrsrRfgPT 4;
BA_ "UserSigValidity" SG_ 835 MON_DiagSnsr_LowPrsrRfgPT 0;
BA_REL_ "GenSigTimeoutTime" BU_SG_REL_ L_ATCU SG_ 835 MON_DiagSnsr_LowPrsrRfgPT 5000;
BA_ "Version" SG_ 835 MON_DiagSnsr_LowPrsrRfgPT "25.05.04";
BA_ "Description" SG_ 835 MON_DiagSnsr_RHPhoto "This value only use for ATCU Library data monitoring (Only use before SOP)";
BA_ "GenSigSendType" SG_ 835 MON_DiagSnsr_RHPhoto 4;
BA_ "UserSigValidity" SG_ 835 MON_DiagSnsr_RHPhoto 0;
BA_REL_ "GenSigTimeoutTime" BU_SG_REL_ L_ATCU SG_ 835 MON_DiagSnsr_RHPhoto 5000;
BA_ "Version" SG_ 835 MON_DiagSnsr_RHPhoto "25.05.04";
BA_ "Description" SG_ 835 MON_DiagSnsr_AstVntDuctTmp "This value only use for ATCU Library data monitoring (Only use before SOP)";
BA_ "GenSigSendType" SG_ 835 MON_DiagSnsr_AstVntDuctTmp 4;
BA_ "UserSigValidity" SG_ 835 MON_DiagSnsr_AstVntDuctTmp 0;
BA_REL_ "GenSigTimeoutTime" BU_SG_REL_ L_ATCU SG_ 835 MON_DiagSnsr_AstVntDuctTmp 5000;
BA_ "Version" SG_ 835 MON_DiagSnsr_AstVntDuctTmp "25.05.04";
BA_ "GenMsgCycleTime" BO_ 2683332352 0;
BA_ "GenMsgNrOfRepetition" BO_ 2683332352 0;
BA_ "GenMsgNrOfRepetition" BO_ 2683332352 0;
BA_ "GenMsgDelayTime" BO_ 2683332352 10;
BA_ "VFrameFormat" BO_ 2683332352 1;
BA_ "UsrSigPurpose" SG_ 2683332352 DIG_FHPTC_Byte0 6;
BA_ "GenSigSendType" SG_ 2683332352 DIG_FHPTC_Byte0 2;
BA_ "UserSigValidity" SG_ 2683332352 DIG_FHPTC_Byte0 0;
BA_REL_ "GenSigTimeoutTime" BU_SG_REL_ L_FHPTC SG_ 2683332352 DIG_FHPTC_Byte0 0;
BA_ "Version" SG_ 2683332352 DIG_FHPTC_Byte0 "25.11.02";
BA_ "UsrSigPurpose" SG_ 2683332352 DIG_FHPTC_Byte2 6;
BA_ "GenSigSendType" SG_ 2683332352 DIG_FHPTC_Byte2 2;
BA_ "UserSigValidity" SG_ 2683332352 DIG_FHPTC_Byte2 0;
BA_REL_ "GenSigTimeoutTime" BU_SG_REL_ L_FHPTC SG_ 2683332352 DIG_FHPTC_Byte2 0;
BA_ "Version" SG_ 2683332352 DIG_FHPTC_Byte2 "25.11.02";
BA_ "UsrSigPurpose" SG_ 2683332352 DIG_FHPTC_Byte3 6;
BA_ "GenSigSendType" SG_ 2683332352 DIG_FHPTC_Byte3 2;
BA_ "UserSigValidity" SG_ 2683332352 DIG_FHPTC_Byte3 0;
BA_REL_ "GenSigTimeoutTime" BU_SG_REL_ L_FHPTC SG_ 2683332352 DIG_FHPTC_Byte3 0;
BA_ "Version" SG_ 2683332352 DIG_FHPTC_Byte3 "25.11.02";
BA_ "UsrSigPurpose" SG_ 2683332352 DIG_FHPTC_Byte4 6;
BA_ "GenSigSendType" SG_ 2683332352 DIG_FHPTC_Byte4 2;
BA_ "UserSigValidity" SG_ 2683332352 DIG_FHPTC_Byte4 0;
BA_REL_ "GenSigTimeoutTime" BU_SG_REL_ L_FHPTC SG_ 2683332352 DIG_FHPTC_Byte4 0;
BA_ "Version" SG_ 2683332352 DIG_FHPTC_Byte4 "25.11.02";
BA_ "UsrSigPurpose" SG_ 2683332352 DIG_FHPTC_Byte5 6;
BA_ "GenSigSendType" SG_ 2683332352 DIG_FHPTC_Byte5 2;
BA_ "UserSigValidity" SG_ 2683332352 DIG_FHPTC_Byte5 0;
BA_REL_ "GenSigTimeoutTime" BU_SG_REL_ L_FHPTC SG_ 2683332352 DIG_FHPTC_Byte5 0;
BA_ "Version" SG_ 2683332352 DIG_FHPTC_Byte5 "25.11.02";
BA_ "UsrSigPurpose" SG_ 2683332352 DIG_FHPTC_Byte6 6;
BA_ "GenSigSendType" SG_ 2683332352 DIG_FHPTC_Byte6 2;
BA_ "UserSigValidity" SG_ 2683332352 DIG_FHPTC_Byte6 0;
BA_REL_ "GenSigTimeoutTime" BU_SG_REL_ L_FHPTC SG_ 2683332352 DIG_FHPTC_Byte6 0;
BA_ "Version" SG_ 2683332352 DIG_FHPTC_Byte6 "25.11.02";
BA_ "UsrSigPurpose" SG_ 2683332352 DIG_FHPTC_Byte7 6;
BA_ "GenSigSendType" SG_ 2683332352 DIG_FHPTC_Byte7 2;
BA_ "UserSigValidity" SG_ 2683332352 DIG_FHPTC_Byte7 0;
BA_REL_ "GenSigTimeoutTime" BU_SG_REL_ L_FHPTC SG_ 2683332352 DIG_FHPTC_Byte7 0;
BA_ "Version" SG_ 2683332352 DIG_FHPTC_Byte7 "25.11.02";
BA_ "UsrSigPurpose" SG_ 2683332352 DIG_FHPTC_Byte1 6;
BA_ "GenSigSendType" SG_ 2683332352 DIG_FHPTC_Byte1 2;
BA_ "UserSigValidity" SG_ 2683332352 DIG_FHPTC_Byte1 0;
BA_REL_ "GenSigTimeoutTime" BU_SG_REL_ L_FHPTC SG_ 2683332352 DIG_FHPTC_Byte1 0;
BA_ "Version" SG_ 2683332352 DIG_FHPTC_Byte1 "25.11.02";
BA_ "GenMsgCycleTime" BO_ 2683397888 0;
BA_ "GenMsgNrOfRepetition" BO_ 2683397888 0;
BA_ "GenMsgNrOfRepetition" BO_ 2683397888 0;
BA_ "GenMsgDelayTime" BO_ 2683397888 10;
BA_ "VFrameFormat" BO_ 2683397888 1;
BA_ "UsrSigPurpose" SG_ 2683397888 FHPTC_DIG_Byte0 6;
BA_ "GenSigSendType" SG_ 2683397888 FHPTC_DIG_Byte0 2;
BA_ "UserSigValidity" SG_ 2683397888 FHPTC_DIG_Byte0 0;
BA_REL_ "GenSigTimeoutTime" BU_SG_REL_ L_DIG SG_ 2683397888 FHPTC_DIG_Byte0 0;
BA_ "Version" SG_ 2683397888 FHPTC_DIG_Byte0 "25.11.02";
BA_ "UsrSigPurpose" SG_ 2683397888 FHPTC_DIG_Byte2 6;
BA_ "GenSigSendType" SG_ 2683397888 FHPTC_DIG_Byte2 2;
BA_ "UserSigValidity" SG_ 2683397888 FHPTC_DIG_Byte2 0;
BA_REL_ "GenSigTimeoutTime" BU_SG_REL_ L_DIG SG_ 2683397888 FHPTC_DIG_Byte2 0;
BA_ "Version" SG_ 2683397888 FHPTC_DIG_Byte2 "25.11.02";
BA_ "UsrSigPurpose" SG_ 2683397888 FHPTC_DIG_Byte3 6;
BA_ "GenSigSendType" SG_ 2683397888 FHPTC_DIG_Byte3 2;
BA_ "UserSigValidity" SG_ 2683397888 FHPTC_DIG_Byte3 0;
BA_REL_ "GenSigTimeoutTime" BU_SG_REL_ L_DIG SG_ 2683397888 FHPTC_DIG_Byte3 0;
BA_ "Version" SG_ 2683397888 FHPTC_DIG_Byte3 "25.11.02";
BA_ "UsrSigPurpose" SG_ 2683397888 FHPTC_DIG_Byte4 6;
BA_ "GenSigSendType" SG_ 2683397888 FHPTC_DIG_Byte4 2;
BA_ "UserSigValidity" SG_ 2683397888 FHPTC_DIG_Byte4 0;
BA_REL_ "GenSigTimeoutTime" BU_SG_REL_ L_DIG SG_ 2683397888 FHPTC_DIG_Byte4 0;
BA_ "Version" SG_ 2683397888 FHPTC_DIG_Byte4 "25.11.02";
BA_ "UsrSigPurpose" SG_ 2683397888 FHPTC_DIG_Byte5 6;
BA_ "GenSigSendType" SG_ 2683397888 FHPTC_DIG_Byte5 2;
BA_ "UserSigValidity" SG_ 2683397888 FHPTC_DIG_Byte5 0;
BA_REL_ "GenSigTimeoutTime" BU_SG_REL_ L_DIG SG_ 2683397888 FHPTC_DIG_Byte5 0;
BA_ "Version" SG_ 2683397888 FHPTC_DIG_Byte5 "25.11.02";
BA_ "UsrSigPurpose" SG_ 2683397888 FHPTC_DIG_Byte6 6;
BA_ "GenSigSendType" SG_ 2683397888 FHPTC_DIG_Byte6 2;
BA_ "UserSigValidity" SG_ 2683397888 FHPTC_DIG_Byte6 0;
BA_REL_ "GenSigTimeoutTime" BU_SG_REL_ L_DIG SG_ 2683397888 FHPTC_DIG_Byte6 0;
BA_ "Version" SG_ 2683397888 FHPTC_DIG_Byte6 "25.11.02";
BA_ "UsrSigPurpose" SG_ 2683397888 FHPTC_DIG_Byte7 6;
BA_ "GenSigSendType" SG_ 2683397888 FHPTC_DIG_Byte7 2;
BA_ "UserSigValidity" SG_ 2683397888 FHPTC_DIG_Byte7 0;
BA_REL_ "GenSigTimeoutTime" BU_SG_REL_ L_DIG SG_ 2683397888 FHPTC_DIG_Byte7 0;
BA_ "Version" SG_ 2683397888 FHPTC_DIG_Byte7 "25.11.02";
BA_ "UsrSigPurpose" SG_ 2683397888 FHPTC_DIG_Byte1 6;
BA_ "GenSigSendType" SG_ 2683397888 FHPTC_DIG_Byte1 2;
BA_ "UserSigValidity" SG_ 2683397888 FHPTC_DIG_Byte1 0;
BA_REL_ "GenSigTimeoutTime" BU_SG_REL_ L_DIG SG_ 2683397888 FHPTC_DIG_Byte1 0;
BA_ "Version" SG_ 2683397888 FHPTC_DIG_Byte1 "25.11.02";
BA_ "GenMsgCycleTime" BO_ 2683331840 0;
BA_ "GenMsgNrOfRepetition" BO_ 2683331840 0;
BA_ "GenMsgNrOfRepetition" BO_ 2683331840 0;
BA_ "GenMsgDelayTime" BO_ 2683331840 10;
BA_ "VFrameFormat" BO_ 2683331840 1;
BA_ "UsrSigPurpose" SG_ 2683331840 DIG_HKBD_Byte0 6;
BA_ "GenSigSendType" SG_ 2683331840 DIG_HKBD_Byte0 2;
BA_ "UserSigValidity" SG_ 2683331840 DIG_HKBD_Byte0 0;
BA_REL_ "GenSigTimeoutTime" BU_SG_REL_ L_HKBD SG_ 2683331840 DIG_HKBD_Byte0 0;
BA_ "Version" SG_ 2683331840 DIG_HKBD_Byte0 "25.11.02";
BA_ "UsrSigPurpose" SG_ 2683331840 DIG_HKBD_Byte2 6;
BA_ "GenSigSendType" SG_ 2683331840 DIG_HKBD_Byte2 2;
BA_ "UserSigValidity" SG_ 2683331840 DIG_HKBD_Byte2 0;
BA_REL_ "GenSigTimeoutTime" BU_SG_REL_ L_HKBD SG_ 2683331840 DIG_HKBD_Byte2 0;
BA_ "Version" SG_ 2683331840 DIG_HKBD_Byte2 "25.11.02";
BA_ "UsrSigPurpose" SG_ 2683331840 DIG_HKBD_Byte3 6;
BA_ "GenSigSendType" SG_ 2683331840 DIG_HKBD_Byte3 2;
BA_ "UserSigValidity" SG_ 2683331840 DIG_HKBD_Byte3 0;
BA_REL_ "GenSigTimeoutTime" BU_SG_REL_ L_HKBD SG_ 2683331840 DIG_HKBD_Byte3 0;
BA_ "Version" SG_ 2683331840 DIG_HKBD_Byte3 "25.11.02";
BA_ "UsrSigPurpose" SG_ 2683331840 DIG_HKBD_Byte4 6;
BA_ "GenSigSendType" SG_ 2683331840 DIG_HKBD_Byte4 2;
BA_ "UserSigValidity" SG_ 2683331840 DIG_HKBD_Byte4 0;
BA_REL_ "GenSigTimeoutTime" BU_SG_REL_ L_HKBD SG_ 2683331840 DIG_HKBD_Byte4 0;
BA_ "Version" SG_ 2683331840 DIG_HKBD_Byte4 "25.11.02";
BA_ "UsrSigPurpose" SG_ 2683331840 DIG_HKBD_Byte5 6;
BA_ "GenSigSendType" SG_ 2683331840 DIG_HKBD_Byte5 2;
BA_ "UserSigValidity" SG_ 2683331840 DIG_HKBD_Byte5 0;
BA_REL_ "GenSigTimeoutTime" BU_SG_REL_ L_HKBD SG_ 2683331840 DIG_HKBD_Byte5 0;
BA_ "Version" SG_ 2683331840 DIG_HKBD_Byte5 "25.11.02";
BA_ "UsrSigPurpose" SG_ 2683331840 DIG_HKBD_Byte6 6;
BA_ "GenSigSendType" SG_ 2683331840 DIG_HKBD_Byte6 2;
BA_ "UserSigValidity" SG_ 2683331840 DIG_HKBD_Byte6 0;
BA_REL_ "GenSigTimeoutTime" BU_SG_REL_ L_HKBD SG_ 2683331840 DIG_HKBD_Byte6 0;
BA_ "Version" SG_ 2683331840 DIG_HKBD_Byte6 "25.11.02";
BA_ "UsrSigPurpose" SG_ 2683331840 DIG_HKBD_Byte7 6;
BA_ "GenSigSendType" SG_ 2683331840 DIG_HKBD_Byte7 2;
BA_ "UserSigValidity" SG_ 2683331840 DIG_HKBD_Byte7 0;
BA_REL_ "GenSigTimeoutTime" BU_SG_REL_ L_HKBD SG_ 2683331840 DIG_HKBD_Byte7 0;
BA_ "Version" SG_ 2683331840 DIG_HKBD_Byte7 "25.11.02";
BA_ "UsrSigPurpose" SG_ 2683331840 DIG_HKBD_Byte1 6;
BA_ "GenSigSendType" SG_ 2683331840 DIG_HKBD_Byte1 2;
BA_ "UserSigValidity" SG_ 2683331840 DIG_HKBD_Byte1 0;
BA_REL_ "GenSigTimeoutTime" BU_SG_REL_ L_HKBD SG_ 2683331840 DIG_HKBD_Byte1 0;
BA_ "Version" SG_ 2683331840 DIG_HKBD_Byte1 "25.11.02";
BA_ "GenMsgCycleTime" BO_ 2683397376 0;
BA_ "GenMsgNrOfRepetition" BO_ 2683397376 0;
BA_ "GenMsgNrOfRepetition" BO_ 2683397376 0;
BA_ "GenMsgDelayTime" BO_ 2683397376 10;
BA_ "VFrameFormat" BO_ 2683397376 1;
BA_ "UsrSigPurpose" SG_ 2683397376 HKBD_DIG_Byte0 6;
BA_ "GenSigSendType" SG_ 2683397376 HKBD_DIG_Byte0 2;
BA_ "UserSigValidity" SG_ 2683397376 HKBD_DIG_Byte0 0;
BA_REL_ "GenSigTimeoutTime" BU_SG_REL_ L_DIG SG_ 2683397376 HKBD_DIG_Byte0 0;
BA_ "Version" SG_ 2683397376 HKBD_DIG_Byte0 "25.11.02";
BA_ "UsrSigPurpose" SG_ 2683397376 HKBD_DIG_Byte2 6;
BA_ "GenSigSendType" SG_ 2683397376 HKBD_DIG_Byte2 2;
BA_ "UserSigValidity" SG_ 2683397376 HKBD_DIG_Byte2 0;
BA_REL_ "GenSigTimeoutTime" BU_SG_REL_ L_DIG SG_ 2683397376 HKBD_DIG_Byte2 0;
BA_ "Version" SG_ 2683397376 HKBD_DIG_Byte2 "25.11.02";
BA_ "UsrSigPurpose" SG_ 2683397376 HKBD_DIG_Byte3 6;
BA_ "GenSigSendType" SG_ 2683397376 HKBD_DIG_Byte3 2;
BA_ "UserSigValidity" SG_ 2683397376 HKBD_DIG_Byte3 0;
BA_REL_ "GenSigTimeoutTime" BU_SG_REL_ L_DIG SG_ 2683397376 HKBD_DIG_Byte3 0;
BA_ "Version" SG_ 2683397376 HKBD_DIG_Byte3 "25.11.02";
BA_ "UsrSigPurpose" SG_ 2683397376 HKBD_DIG_Byte4 6;
BA_ "GenSigSendType" SG_ 2683397376 HKBD_DIG_Byte4 2;
BA_ "UserSigValidity" SG_ 2683397376 HKBD_DIG_Byte4 0;
BA_REL_ "GenSigTimeoutTime" BU_SG_REL_ L_DIG SG_ 2683397376 HKBD_DIG_Byte4 0;
BA_ "Version" SG_ 2683397376 HKBD_DIG_Byte4 "25.11.02";
BA_ "UsrSigPurpose" SG_ 2683397376 HKBD_DIG_Byte5 6;
BA_ "GenSigSendType" SG_ 2683397376 HKBD_DIG_Byte5 2;
BA_ "UserSigValidity" SG_ 2683397376 HKBD_DIG_Byte5 0;
BA_REL_ "GenSigTimeoutTime" BU_SG_REL_ L_DIG SG_ 2683397376 HKBD_DIG_Byte5 0;
BA_ "Version" SG_ 2683397376 HKBD_DIG_Byte5 "25.11.02";
BA_ "UsrSigPurpose" SG_ 2683397376 HKBD_DIG_Byte6 6;
BA_ "GenSigSendType" SG_ 2683397376 HKBD_DIG_Byte6 2;
BA_ "UserSigValidity" SG_ 2683397376 HKBD_DIG_Byte6 0;
BA_REL_ "GenSigTimeoutTime" BU_SG_REL_ L_DIG SG_ 2683397376 HKBD_DIG_Byte6 0;
BA_ "Version" SG_ 2683397376 HKBD_DIG_Byte6 "25.11.02";
BA_ "UsrSigPurpose" SG_ 2683397376 HKBD_DIG_Byte7 6;
BA_ "GenSigSendType" SG_ 2683397376 HKBD_DIG_Byte7 2;
BA_ "UserSigValidity" SG_ 2683397376 HKBD_DIG_Byte7 0;
BA_REL_ "GenSigTimeoutTime" BU_SG_REL_ L_DIG SG_ 2683397376 HKBD_DIG_Byte7 0;
BA_ "Version" SG_ 2683397376 HKBD_DIG_Byte7 "25.11.02";
BA_ "UsrSigPurpose" SG_ 2683397376 HKBD_DIG_Byte1 6;
BA_ "GenSigSendType" SG_ 2683397376 HKBD_DIG_Byte1 2;
BA_ "UserSigValidity" SG_ 2683397376 HKBD_DIG_Byte1 0;
BA_REL_ "GenSigTimeoutTime" BU_SG_REL_ L_DIG SG_ 2683397376 HKBD_DIG_Byte1 0;
BA_ "Version" SG_ 2683397376 HKBD_DIG_Byte1 "25.11.02";
BA_ "GenMsgCycleTime" BO_ 2683332096 0;
BA_ "GenMsgNrOfRepetition" BO_ 2683332096 0;
BA_ "GenMsgNrOfRepetition" BO_ 2683332096 0;
BA_ "GenMsgDelayTime" BO_ 2683332096 10;
BA_ "VFrameFormat" BO_ 2683332096 1;
BA_ "UsrSigPurpose" SG_ 2683332096 DIG_PCM_Byte0 6;
BA_ "GenSigSendType" SG_ 2683332096 DIG_PCM_Byte0 2;
BA_ "UserSigValidity" SG_ 2683332096 DIG_PCM_Byte0 0;
BA_REL_ "GenSigTimeoutTime" BU_SG_REL_ L_PCM SG_ 2683332096 DIG_PCM_Byte0 0;
BA_ "Version" SG_ 2683332096 DIG_PCM_Byte0 "25.11.02";
BA_ "UsrSigPurpose" SG_ 2683332096 DIG_PCM_Byte2 6;
BA_ "GenSigSendType" SG_ 2683332096 DIG_PCM_Byte2 2;
BA_ "UserSigValidity" SG_ 2683332096 DIG_PCM_Byte2 0;
BA_REL_ "GenSigTimeoutTime" BU_SG_REL_ L_PCM SG_ 2683332096 DIG_PCM_Byte2 0;
BA_ "Version" SG_ 2683332096 DIG_PCM_Byte2 "25.11.02";
BA_ "UsrSigPurpose" SG_ 2683332096 DIG_PCM_Byte3 6;
BA_ "GenSigSendType" SG_ 2683332096 DIG_PCM_Byte3 2;
BA_ "UserSigValidity" SG_ 2683332096 DIG_PCM_Byte3 0;
BA_REL_ "GenSigTimeoutTime" BU_SG_REL_ L_PCM SG_ 2683332096 DIG_PCM_Byte3 0;
BA_ "Version" SG_ 2683332096 DIG_PCM_Byte3 "25.11.02";
BA_ "UsrSigPurpose" SG_ 2683332096 DIG_PCM_Byte4 6;
BA_ "GenSigSendType" SG_ 2683332096 DIG_PCM_Byte4 2;
BA_ "UserSigValidity" SG_ 2683332096 DIG_PCM_Byte4 0;
BA_REL_ "GenSigTimeoutTime" BU_SG_REL_ L_PCM SG_ 2683332096 DIG_PCM_Byte4 0;
BA_ "Version" SG_ 2683332096 DIG_PCM_Byte4 "25.11.02";
BA_ "UsrSigPurpose" SG_ 2683332096 DIG_PCM_Byte5 6;
BA_ "GenSigSendType" SG_ 2683332096 DIG_PCM_Byte5 2;
BA_ "UserSigValidity" SG_ 2683332096 DIG_PCM_Byte5 0;
BA_REL_ "GenSigTimeoutTime" BU_SG_REL_ L_PCM SG_ 2683332096 DIG_PCM_Byte5 0;
BA_ "Version" SG_ 2683332096 DIG_PCM_Byte5 "25.11.02";
BA_ "UsrSigPurpose" SG_ 2683332096 DIG_PCM_Byte6 6;
BA_ "GenSigSendType" SG_ 2683332096 DIG_PCM_Byte6 2;
BA_ "UserSigValidity" SG_ 2683332096 DIG_PCM_Byte6 0;
BA_REL_ "GenSigTimeoutTime" BU_SG_REL_ L_PCM SG_ 2683332096 DIG_PCM_Byte6 0;
BA_ "Version" SG_ 2683332096 DIG_PCM_Byte6 "25.11.02";
BA_ "UsrSigPurpose" SG_ 2683332096 DIG_PCM_Byte7 6;
BA_ "GenSigSendType" SG_ 2683332096 DIG_PCM_Byte7 2;
BA_ "UserSigValidity" SG_ 2683332096 DIG_PCM_Byte7 0;
BA_REL_ "GenSigTimeoutTime" BU_SG_REL_ L_PCM SG_ 2683332096 DIG_PCM_Byte7 0;
BA_ "Version" SG_ 2683332096 DIG_PCM_Byte7 "25.11.02";
BA_ "UsrSigPurpose" SG_ 2683332096 DIG_PCM_Byte1 6;
BA_ "GenSigSendType" SG_ 2683332096 DIG_PCM_Byte1 2;
BA_ "UserSigValidity" SG_ 2683332096 DIG_PCM_Byte1 0;
BA_REL_ "GenSigTimeoutTime" BU_SG_REL_ L_PCM SG_ 2683332096 DIG_PCM_Byte1 0;
BA_ "Version" SG_ 2683332096 DIG_PCM_Byte1 "25.11.02";
BA_ "GenMsgCycleTime" BO_ 2683397632 0;
BA_ "GenMsgNrOfRepetition" BO_ 2683397632 0;
BA_ "GenMsgNrOfRepetition" BO_ 2683397632 0;
BA_ "GenMsgDelayTime" BO_ 2683397632 10;
BA_ "VFrameFormat" BO_ 2683397632 1;
BA_ "UsrSigPurpose" SG_ 2683397632 PCM_DIG_Byte0 6;
BA_ "GenSigSendType" SG_ 2683397632 PCM_DIG_Byte0 2;
BA_ "UserSigValidity" SG_ 2683397632 PCM_DIG_Byte0 0;
BA_REL_ "GenSigTimeoutTime" BU_SG_REL_ L_DIG SG_ 2683397632 PCM_DIG_Byte0 0;
BA_ "Version" SG_ 2683397632 PCM_DIG_Byte0 "25.11.02";
BA_ "UsrSigPurpose" SG_ 2683397632 PCM_DIG_Byte2 6;
BA_ "GenSigSendType" SG_ 2683397632 PCM_DIG_Byte2 2;
BA_ "UserSigValidity" SG_ 2683397632 PCM_DIG_Byte2 0;
BA_REL_ "GenSigTimeoutTime" BU_SG_REL_ L_DIG SG_ 2683397632 PCM_DIG_Byte2 0;
BA_ "Version" SG_ 2683397632 PCM_DIG_Byte2 "25.11.02";
BA_ "UsrSigPurpose" SG_ 2683397632 PCM_DIG_Byte3 6;
BA_ "GenSigSendType" SG_ 2683397632 PCM_DIG_Byte3 2;
BA_ "UserSigValidity" SG_ 2683397632 PCM_DIG_Byte3 0;
BA_REL_ "GenSigTimeoutTime" BU_SG_REL_ L_DIG SG_ 2683397632 PCM_DIG_Byte3 0;
BA_ "Version" SG_ 2683397632 PCM_DIG_Byte3 "25.11.02";
BA_ "UsrSigPurpose" SG_ 2683397632 PCM_DIG_Byte4 6;
BA_ "GenSigSendType" SG_ 2683397632 PCM_DIG_Byte4 2;
BA_ "UserSigValidity" SG_ 2683397632 PCM_DIG_Byte4 0;
BA_REL_ "GenSigTimeoutTime" BU_SG_REL_ L_DIG SG_ 2683397632 PCM_DIG_Byte4 0;
BA_ "Version" SG_ 2683397632 PCM_DIG_Byte4 "25.11.02";
BA_ "UsrSigPurpose" SG_ 2683397632 PCM_DIG_Byte5 6;
BA_ "GenSigSendType" SG_ 2683397632 PCM_DIG_Byte5 2;
BA_ "UserSigValidity" SG_ 2683397632 PCM_DIG_Byte5 0;
BA_REL_ "GenSigTimeoutTime" BU_SG_REL_ L_DIG SG_ 2683397632 PCM_DIG_Byte5 0;
BA_ "Version" SG_ 2683397632 PCM_DIG_Byte5 "25.11.02";
BA_ "UsrSigPurpose" SG_ 2683397632 PCM_DIG_Byte6 6;
BA_ "GenSigSendType" SG_ 2683397632 PCM_DIG_Byte6 2;
BA_ "UserSigValidity" SG_ 2683397632 PCM_DIG_Byte6 0;
BA_REL_ "GenSigTimeoutTime" BU_SG_REL_ L_DIG SG_ 2683397632 PCM_DIG_Byte6 0;
BA_ "Version" SG_ 2683397632 PCM_DIG_Byte6 "25.11.02";
BA_ "UsrSigPurpose" SG_ 2683397632 PCM_DIG_Byte7 6;
BA_ "GenSigSendType" SG_ 2683397632 PCM_DIG_Byte7 2;
BA_ "UserSigValidity" SG_ 2683397632 PCM_DIG_Byte7 0;
BA_REL_ "GenSigTimeoutTime" BU_SG_REL_ L_DIG SG_ 2683397632 PCM_DIG_Byte7 0;
BA_ "Version" SG_ 2683397632 PCM_DIG_Byte7 "25.11.02";
BA_ "UsrSigPurpose" SG_ 2683397632 PCM_DIG_Byte1 6;
BA_ "GenSigSendType" SG_ 2683397632 PCM_DIG_Byte1 2;
BA_ "UserSigValidity" SG_ 2683397632 PCM_DIG_Byte1 0;
BA_REL_ "GenSigTimeoutTime" BU_SG_REL_ L_DIG SG_ 2683397632 PCM_DIG_Byte1 0;
BA_ "Version" SG_ 2683397632 PCM_DIG_Byte1 "25.11.02";
BA_ "GenMsgCycleTime" BO_ 2683331584 0;
BA_ "GenMsgNrOfRepetition" BO_ 2683331584 0;
BA_ "GenMsgNrOfRepetition" BO_ 2683331584 0;
BA_ "GenMsgDelayTime" BO_ 2683331584 10;
BA_ "VFrameFormat" BO_ 2683331584 1;
BA_ "UsrSigPurpose" SG_ 2683331584 DIG_RHPTC_Byte0 6;
BA_ "GenSigSendType" SG_ 2683331584 DIG_RHPTC_Byte0 2;
BA_ "UserSigValidity" SG_ 2683331584 DIG_RHPTC_Byte0 0;
BA_REL_ "GenSigTimeoutTime" BU_SG_REL_ L_RHPTC SG_ 2683331584 DIG_RHPTC_Byte0 0;
BA_ "Version" SG_ 2683331584 DIG_RHPTC_Byte0 "25.11.02";
BA_ "UsrSigPurpose" SG_ 2683331584 DIG_RHPTC_Byte2 6;
BA_ "GenSigSendType" SG_ 2683331584 DIG_RHPTC_Byte2 2;
BA_ "UserSigValidity" SG_ 2683331584 DIG_RHPTC_Byte2 0;
BA_REL_ "GenSigTimeoutTime" BU_SG_REL_ L_RHPTC SG_ 2683331584 DIG_RHPTC_Byte2 0;
BA_ "Version" SG_ 2683331584 DIG_RHPTC_Byte2 "25.11.02";
BA_ "UsrSigPurpose" SG_ 2683331584 DIG_RHPTC_Byte3 6;
BA_ "GenSigSendType" SG_ 2683331584 DIG_RHPTC_Byte3 2;
BA_ "UserSigValidity" SG_ 2683331584 DIG_RHPTC_Byte3 0;
BA_REL_ "GenSigTimeoutTime" BU_SG_REL_ L_RHPTC SG_ 2683331584 DIG_RHPTC_Byte3 0;
BA_ "Version" SG_ 2683331584 DIG_RHPTC_Byte3 "25.11.02";
BA_ "UsrSigPurpose" SG_ 2683331584 DIG_RHPTC_Byte4 6;
BA_ "GenSigSendType" SG_ 2683331584 DIG_RHPTC_Byte4 2;
BA_ "UserSigValidity" SG_ 2683331584 DIG_RHPTC_Byte4 0;
BA_REL_ "GenSigTimeoutTime" BU_SG_REL_ L_RHPTC SG_ 2683331584 DIG_RHPTC_Byte4 0;
BA_ "Version" SG_ 2683331584 DIG_RHPTC_Byte4 "25.11.02";
BA_ "UsrSigPurpose" SG_ 2683331584 DIG_RHPTC_Byte5 6;
BA_ "GenSigSendType" SG_ 2683331584 DIG_RHPTC_Byte5 2;
BA_ "UserSigValidity" SG_ 2683331584 DIG_RHPTC_Byte5 0;
BA_REL_ "GenSigTimeoutTime" BU_SG_REL_ L_RHPTC SG_ 2683331584 DIG_RHPTC_Byte5 0;
BA_ "Version" SG_ 2683331584 DIG_RHPTC_Byte5 "25.11.02";
BA_ "UsrSigPurpose" SG_ 2683331584 DIG_RHPTC_Byte6 6;
BA_ "GenSigSendType" SG_ 2683331584 DIG_RHPTC_Byte6 2;
BA_ "UserSigValidity" SG_ 2683331584 DIG_RHPTC_Byte6 0;
BA_REL_ "GenSigTimeoutTime" BU_SG_REL_ L_RHPTC SG_ 2683331584 DIG_RHPTC_Byte6 0;
BA_ "Version" SG_ 2683331584 DIG_RHPTC_Byte6 "25.11.02";
BA_ "UsrSigPurpose" SG_ 2683331584 DIG_RHPTC_Byte7 6;
BA_ "GenSigSendType" SG_ 2683331584 DIG_RHPTC_Byte7 2;
BA_ "UserSigValidity" SG_ 2683331584 DIG_RHPTC_Byte7 0;
BA_REL_ "GenSigTimeoutTime" BU_SG_REL_ L_RHPTC SG_ 2683331584 DIG_RHPTC_Byte7 0;
BA_ "Version" SG_ 2683331584 DIG_RHPTC_Byte7 "25.11.02";
BA_ "UsrSigPurpose" SG_ 2683331584 DIG_RHPTC_Byte1 6;
BA_ "GenSigSendType" SG_ 2683331584 DIG_RHPTC_Byte1 2;
BA_ "UserSigValidity" SG_ 2683331584 DIG_RHPTC_Byte1 0;
BA_REL_ "GenSigTimeoutTime" BU_SG_REL_ L_RHPTC SG_ 2683331584 DIG_RHPTC_Byte1 0;
BA_ "Version" SG_ 2683331584 DIG_RHPTC_Byte1 "25.11.02";
BA_ "GenMsgCycleTime" BO_ 2683397120 0;
BA_ "GenMsgNrOfRepetition" BO_ 2683397120 0;
BA_ "GenMsgNrOfRepetition" BO_ 2683397120 0;
BA_ "GenMsgDelayTime" BO_ 2683397120 10;
BA_ "VFrameFormat" BO_ 2683397120 1;
BA_ "UsrSigPurpose" SG_ 2683397120 RHPTC_DIG_Byte0 6;
BA_ "GenSigSendType" SG_ 2683397120 RHPTC_DIG_Byte0 2;
BA_ "UserSigValidity" SG_ 2683397120 RHPTC_DIG_Byte0 0;
BA_REL_ "GenSigTimeoutTime" BU_SG_REL_ L_DIG SG_ 2683397120 RHPTC_DIG_Byte0 0;
BA_ "Version" SG_ 2683397120 RHPTC_DIG_Byte0 "25.11.02";
BA_ "UsrSigPurpose" SG_ 2683397120 RHPTC_DIG_Byte2 6;
BA_ "GenSigSendType" SG_ 2683397120 RHPTC_DIG_Byte2 2;
BA_ "UserSigValidity" SG_ 2683397120 RHPTC_DIG_Byte2 0;
BA_REL_ "GenSigTimeoutTime" BU_SG_REL_ L_DIG SG_ 2683397120 RHPTC_DIG_Byte2 0;
BA_ "Version" SG_ 2683397120 RHPTC_DIG_Byte2 "25.11.02";
BA_ "UsrSigPurpose" SG_ 2683397120 RHPTC_DIG_Byte3 6;
BA_ "GenSigSendType" SG_ 2683397120 RHPTC_DIG_Byte3 2;
BA_ "UserSigValidity" SG_ 2683397120 RHPTC_DIG_Byte3 0;
BA_REL_ "GenSigTimeoutTime" BU_SG_REL_ L_DIG SG_ 2683397120 RHPTC_DIG_Byte3 0;
BA_ "Version" SG_ 2683397120 RHPTC_DIG_Byte3 "25.11.02";
BA_ "UsrSigPurpose" SG_ 2683397120 RHPTC_DIG_Byte4 6;
BA_ "GenSigSendType" SG_ 2683397120 RHPTC_DIG_Byte4 2;
BA_ "UserSigValidity" SG_ 2683397120 RHPTC_DIG_Byte4 0;
BA_REL_ "GenSigTimeoutTime" BU_SG_REL_ L_DIG SG_ 2683397120 RHPTC_DIG_Byte4 0;
BA_ "Version" SG_ 2683397120 RHPTC_DIG_Byte4 "25.11.02";
BA_ "UsrSigPurpose" SG_ 2683397120 RHPTC_DIG_Byte5 6;
BA_ "GenSigSendType" SG_ 2683397120 RHPTC_DIG_Byte5 2;
BA_ "UserSigValidity" SG_ 2683397120 RHPTC_DIG_Byte5 0;
BA_REL_ "GenSigTimeoutTime" BU_SG_REL_ L_DIG SG_ 2683397120 RHPTC_DIG_Byte5 0;
BA_ "Version" SG_ 2683397120 RHPTC_DIG_Byte5 "25.11.02";
BA_ "UsrSigPurpose" SG_ 2683397120 RHPTC_DIG_Byte6 6;
BA_ "GenSigSendType" SG_ 2683397120 RHPTC_DIG_Byte6 2;
BA_ "UserSigValidity" SG_ 2683397120 RHPTC_DIG_Byte6 0;
BA_REL_ "GenSigTimeoutTime" BU_SG_REL_ L_DIG SG_ 2683397120 RHPTC_DIG_Byte6 0;
BA_ "Version" SG_ 2683397120 RHPTC_DIG_Byte6 "25.11.02";
BA_ "UsrSigPurpose" SG_ 2683397120 RHPTC_DIG_Byte7 6;
BA_ "GenSigSendType" SG_ 2683397120 RHPTC_DIG_Byte7 2;
BA_ "UserSigValidity" SG_ 2683397120 RHPTC_DIG_Byte7 0;
BA_REL_ "GenSigTimeoutTime" BU_SG_REL_ L_DIG SG_ 2683397120 RHPTC_DIG_Byte7 0;
BA_ "Version" SG_ 2683397120 RHPTC_DIG_Byte7 "25.11.02";
BA_ "UsrSigPurpose" SG_ 2683397120 RHPTC_DIG_Byte1 6;
BA_ "GenSigSendType" SG_ 2683397120 RHPTC_DIG_Byte1 2;
BA_ "UserSigValidity" SG_ 2683397120 RHPTC_DIG_Byte1 0;
BA_REL_ "GenSigTimeoutTime" BU_SG_REL_ L_DIG SG_ 2683397120 RHPTC_DIG_Byte1 0;
BA_ "Version" SG_ 2683397120 RHPTC_DIG_Byte1 "25.11.02";
VAL_ 129 L_3HKBD_SW_Ver1 0 "0x00~0x7E:ASCII value" 126 "0x00~0x7E:ASCII value" 127 "Invalid" ;
VAL_ 129 L_3HKBD_SW_Ver2 0 "0x00~0x7E:ASCII value" 126 "0x00~0x7E:ASCII value" 127 "Invalid" ;
VAL_ 129 L_3HKBD_SW_Ver3 0 "0x00~0x7E:ASCII value" 126 "0x00~0x7E:ASCII value" 127 "Invalid" ;
VAL_ 130 L_3HKBD_Rr_TempActrFB 1023 "Error Indicator" ;
VAL_ 130 L_3HKBD_Rr_TempActrSt 0 "Normal" 1 "Open" 2 "Short" 3 "Stuck" ;
VAL_ 130 L_3HKBD_Rr_TempAsstActrFB 1023 "Error Indicator" ;
VAL_ 130 L_3HKBD_Rr_TempAsstActrSt 0 "Normal" 1 "Open" 2 "Short" 3 "Stuck" ;
VAL_ 130 L_3HKBD_RrDrModeActrFB 1023 "Error Indicator" ;
VAL_ 130 L_3HKBD_RrDrModeActrSt 0 "Normal" 1 "Open" 2 "Short" 3 "Stuck" ;
VAL_ 130 L_3HKBD_Rr_BLDCError 0 "No error" 1 "Over Current" 2 "Under Voltage" 3 "Over Voltage" 4 "Stall" 5 "Over Temperature" 6 "Controller Shutdown (Internal Error)" 7 "Current Limit" 8 "Limp mode" 9 "LIN Fail" 10 "RESERVED" 11 "RESERVED" 12 "RESERVED" 13 "RESERVED" 14 "RESERVED" 15 "RESERVED" ;
VAL_ 130 L_3HKBD_Rr_EvapVolVal 0 "0x0~0xFA:0~5V" 250 "0x0~0xFA:0~5V" 255 "Error Indicator" ;
VAL_ 131 L_3HKBD_ResetOpSta 0 "Normal" 1 "Reset Complete" 2 "Reset Fail" 3 "RESERVED" ;
VAL_ 132 L_3HKBD_RrTempDnSw 0 "Off" 1 "On" ;
VAL_ 132 L_3HKBD_RrTempUpSw 0 "Off" 1 "On" ;
VAL_ 132 L_3HKBD_RrAutoSw 0 "Off" 1 "On" ;
VAL_ 132 L_3HKBD_RrOffSw 0 "Off" 1 "On" ;
VAL_ 132 L_3HKBD_RrSyncSw 0 "Off" 1 "On" ;
VAL_ 132 L_3HKBD_RLStHtrSwReq 0 "Off" 1 "On" ;
VAL_ 132 L_3HKBD_RLStVentSwReq 0 "Off" 1 "On" ;
VAL_ 132 L_3HKBD_RRStHtrSwReq 0 "Off" 1 "On" ;
VAL_ 132 L_3HKBD_RRStVentSwReq 0 "Off" 1 "On" ;
VAL_ 132 L_3HKBD_RrBlwDnOffSw 0 "Off" 1 "On" ;
VAL_ 132 L_3HKBD_RrOnOffSet 0 "Default" 1 "On" 2 "Off" 3 "Invalid" ;
VAL_ 132 L_3HKBD_RrBlwDnSw 0 "Off" 1 "On" ;
VAL_ 132 L_3HKBD_RrblwUpMaxSw 0 "Off" 1 "On" ;
VAL_ 132 L_3HKBD_RrBlwUpSw 0 "Off" 1 "On" ;
VAL_ 132 L_3HKBD_RrModeDnSw 0 "Off" 1 "On" ;
VAL_ 132 L_3HKBD_RrModeUpSw 0 "Off" 1 "On" ;
VAL_ 132 L_3HKBD_RrModeSw 0 "Off" 1 "On" ;
VAL_ 132 L_3HKBD_RrModeVentSw 0 "Off" 1 "On" ;
VAL_ 132 L_3HKBD_RrModeFloorSw 0 "Off" 1 "On" ;
VAL_ 132 L_3HKBD_RrModeBiLvlSw 0 "Off" 1 "On" ;
VAL_ 133 L_3HKBD_RrDrFlrDuctSnsr 0 "0x0~0xFA:0~5V" 250 "0x0~0xFA:0~5V" 255 "Error Indicator" ;
VAL_ 133 L_3HKBD_RrPsFlrDuctSnsr 0 "0x0~0xFA:0 ~ 5V" 250 "0x0~0xFA:0 ~ 5V" 255 "Error Indicator" ;
VAL_ 133 L_3HKBD_RrPsVntDuctSnsr 0 "0x0~0xFA:0 ~ 5V" 250 "0x0~0xFA:0 ~ 5V" 255 "Error Indicator" ;
VAL_ 133 L_3HKBD_RrPsModeActrFB 1023 "Error Indicator" ;
VAL_ 133 L_3HKBD_RrDrVntDuctSnsr 0 "0x0~0xFA:0~5V" 250 "0x0~0xFA:0~5V" 255 "Error Indicator" ;
VAL_ 134 L_3HKBD_RrTempClickCnt 0 "RESERVED" 1 "01~0x7F:Clockwise" 127 "01~0x7F:Clockwise" 128 "80~0xFE:Counter Clockwise" 254 "80~0xFE:Counter Clockwise" 255 "Invalid" ;
VAL_ 134 L_3HKBD_TempKnobCnt 0 "0" 1 "1" 2 "2" 3 "invalid" ;
VAL_ 134 L_3HKBD_BlwKnobCnt 0 "0" 1 "1" 2 "2" 3 "invalid" ;
VAL_ 134 L_3HKBD_HVACPnlBckLight_Res 0 "Invalid(Default)" 1 "On" 2 "Off" 3 "RESERVED" ;
VAL_ 134 L_3HKBD_RrBlwrClickCnt 0 "RESERVED" 1 "01~0x7F:Clockwise" 127 "01~0x7F:Clockwise" 128 "80~0xFE:Counter Clockwise" 254 "80~0xFE:Counter Clockwise" 255 "Invalid" ;
VAL_ 136 L_3HKBD_Rr_HVACBLDCMtrVolt 0 "0x00~0xFE:Voltage = HEX * 0.1 + 0" 254 "0x00~0xFE:Voltage = HEX * 0.1 + 0" 255 "Invalid" ;
VAL_ 136 L_3HKBD_Rr_HVACBLDCOverCurrent 0 "Normal (Default)" 1 "Error" ;
VAL_ 136 L_3HKBD_Rr_HVACBLDMotFltUnderVtg 0 "Normal (Default)" 1 "Error" ;
VAL_ 136 L_3HKBD_Rr_HVACBLDMotFltOverVtg 0 "Normal (Default)" 1 "Error" ;
VAL_ 136 L_3HKBD_Rr_HVACBLDCMotFltStall 0 "Normal (Default)" 1 "Error" ;
VAL_ 136 L_3HKBD_Rr_HVACBLDCMotOverTemp 0 "Normal (Default)" 1 "Error" ;
VAL_ 136 L_3HKBD_Rr_HVACBLDCMotCurrentLmt 0 "Normal (Default)" 1 "Error" ;
VAL_ 136 L_3HKBD_Rr_HVACBLDCMotCtrlShtdwn 0 "Normal (Default)" 1 "Error" ;
VAL_ 136 L_3HKBD_Rr_HVACBLDCMotLimpMod 0 "Normal (Default)" 1 "Error" ;
VAL_ 136 L_3HKBD_RrPsModeActrSt 0 "Normal" 1 "Open" 2 "Short" 3 "Stuck" ;
VAL_ 136 L_3HKBD_Rr_HVACBLDCMotLINFail 0 "Normal (Default)" 1 "Error" ;
VAL_ 136 L_3HKBD_Rr_HVACBLDCMtrA 0 "0x00~0xFE:Voltage = HEX * 0.1 + 0" 254 "0x00~0xFE:Voltage = HEX * 0.1 + 0" 255 "Invalid" ;
VAL_ 353 L_ATCU_HU_FrDrEVntModeSet 0 "Default" 1 "FOCUS Mode" 2 "SPREAD Mode" 3 "CYCLE Mode" 4 "FREE Mode" 5 "OFF" 6 "RESERVED" 7 "RESERVED" 8 "RESERVED" 9 "RESERVED" 10 "RESERVED" 11 "RESERVED" 12 "RESERVED" 13 "RESERVED" 14 "RESERVED" 15 "Invalid" ;
VAL_ 353 L_ATCU_HU_FrDrEVntCtrOpnCls 0 "Default" 1 "OPEN" 2 "CLOSE" 3 "Invalid" ;
VAL_ 353 L_ATCU_HU_FrPsEVntSideOpnCls 0 "Default" 1 "OPEN" 2 "CLOSE" 3 "Invalid" ;
VAL_ 353 L_ATCU_HU_FrPsEVntCtrOpnCls 0 "Default" 1 "OPEN" 2 "CLOSE" 3 "Invalid" ;
VAL_ 353 L_ATCU_HU_FrtEvntFocusLvlSet 0 "Default" 1 "1 Level" 2 "2 Level" 3 "3 Level" 4 "4 Level" 5 "5 Level" 6 "RESERVED" 7 "Invalid" ;
VAL_ 353 L_ATCU_HU_FrPsEVntModeSet 0 "Default" 1 "FOCUS Mode" 2 "SPREAD Mode" 3 "CYCLE Mode" 4 "FREE Mode" 5 "OFF" 6 "RESERVED" 7 "RESERVED" 8 "RESERVED" 9 "RESERVED" 10 "RESERVED" 11 "RESERVED" 12 "RESERVED" 13 "RESERVED" 14 "RESERVED" 15 "Invalid" ;
VAL_ 353 L_ATCU_HU_FrDrEVntSideOpnCls 0 "Default" 1 "OPEN" 2 "CLOSE" 3 "Invalid" ;
VAL_ 354 L_ATCU_CTS_FrtDrEVntModeSet 0 "Default" 1 "FOCUS Mode" 2 "SPREAD Mode" 3 "CYCLE Mode" 4 "FREE Mode" 5 "OFF" 6 "RESERVED" 7 "RESERVED" 8 "RESERVED" 9 "RESERVED" 10 "RESERVED" 11 "RESERVED" 12 "RESERVED" 13 "RESERVED" 14 "RESERVED" 15 "Invalid" ;
VAL_ 354 L_ATCU_CTS_FrDrEVntCtrOpnCls 0 "Default" 1 "OPEN" 2 "CLOSE" 3 "Invalid" ;
VAL_ 354 L_ATCU_CTS_FrPsEVntSideOpnCls 0 "Default" 1 "OPEN" 2 "CLOSE" 3 "Invalid" ;
VAL_ 354 L_ATCU_CTS_FrPsEVntCtrOpnCls 0 "Default" 1 "OPEN" 2 "CLOSE" 3 "Invalid" ;
VAL_ 354 L_ATCU_CTS_RrEvntFocusLvlSet 0 "Default" 1 "1 Level" 2 "2 Level" 3 "3 Level" 4 "4 Level" 5 "5 Level" 6 "RESERVED" 7 "Invalid" ;
VAL_ 354 L_ATCU_CTS_FrtPsEVntModeSet 0 "Default" 1 "FOCUS Mode" 2 "SPREAD Mode" 3 "CYCLE Mode" 4 "FREE Mode" 5 "OFF" 6 "RESERVED" 7 "RESERVED" 8 "RESERVED" 9 "RESERVED" 10 "RESERVED" 11 "RESERVED" 12 "RESERVED" 13 "RESERVED" 14 "RESERVED" 15 "Invalid" ;
VAL_ 354 L_ATCU_CTS_FrDrEVntSideOpnCls 0 "Default" 1 "OPEN" 2 "CLOSE" 3 "Invalid" ;
VAL_ 860 L_ATCU_Lib_MngrModBufCnt 0 "BufferCnt" 1 "BufferCnt" 2 "BufferCnt" 3 "BufferCnt" 4 "BufferCnt" 5 "BufferCnt" 6 "BufferCnt" 7 "BufferCnt" 8 "BufferCnt" 9 "BufferCnt" 10 "BufferCnt" 11 "BufferCnt" 12 "BufferCnt" 13 "BufferCnt" 14 "BufferCnt" 15 "BufferCnt" 16 "RESERVED" 17 "RESERVED" 18 "RESERVED" 19 "RESERVED" 20 "RESERVED" 21 "RESERVED" 22 "RESERVED" 23 "RESERVED" 24 "RESERVED" 25 "RESERVED" 26 "RESERVED" 27 "RESERVED" 28 "RESERVED" 29 "RESERVED" 30 "RESERVED" 31 "RESERVED" ;
VAL_ 860 L_ATCU_Lib_MngrDEFBufCnt 0 "BufferCnt" 1 "BufferCnt" 2 "BufferCnt" 3 "BufferCnt" 4 "RESERVED" 5 "RESERVED" 6 "RESERVED" 7 "RESERVED" ;
VAL_ 860 L_ATCU_Lib_MngrBlwBufCnt 0 "BufferCnt" 1 "BufferCnt" 2 "BufferCnt" 3 "BufferCnt" 4 "BufferCnt" 5 "BufferCnt" 6 "BufferCnt" 7 "BufferCnt" 8 "BufferCnt" 9 "BufferCnt" 10 "RESERVED" 11 "RESERVED" 12 "RESERVED" 13 "RESERVED" 14 "RESERVED" 15 "RESERVED" ;
VAL_ 860 L_ATCU_Lib_MngrACBufCnt 0 "BufferCnt" 1 "BufferCnt" 2 "BufferCnt" 3 "BufferCnt" 4 "BufferCnt" 5 "BufferCnt" 6 "BufferCnt" 7 "BufferCnt" 8 "BufferCnt" 9 "BufferCnt" 10 "BufferCnt" 11 "RESERVED" 12 "RESERVED" 13 "RESERVED" 14 "RESERVED" 15 "RESERVED" ;
VAL_ 860 L_ATCU_Lib_2LHMngrBlwBufCnt 0 "BufferCnt" 1 "BufferCnt" 2 "BufferCnt" 3 "BufferCnt" 4 "BufferCnt" 5 "BufferCnt" 6 "BufferCnt" 7 "RESERVED" 8 "RESERVED" 9 "RESERVED" 10 "RESERVED" 11 "RESERVED" 12 "RESERVED" 13 "RESERVED" 14 "RESERVED" 15 "RESERVED" ;
VAL_ 860 L_ATCU_Lib_2LHMngrModBufCnt 0 "BufferCnt" 1 "BufferCnt" 2 "BufferCnt" 3 "BufferCnt" 4 "BufferCnt" 5 "BufferCnt" 6 "BufferCnt" 7 "BufferCnt" 8 "BufferCnt" 9 "RESERVED" 10 "RESERVED" 11 "RESERVED" 12 "RESERVED" 13 "RESERVED" 14 "RESERVED" 15 "RESERVED" ;
VAL_ 860 L_ATCU_Lib_2LHMngrTempBufCnt 0 "BufferCnt" 1 "BufferCnt" 2 "BufferCnt" 3 "BufferCnt" 4 "RESERVED" 5 "RESERVED" 6 "RESERVED" 7 "RESERVED" ;
VAL_ 860 L_ATCU_Lib_2RHMngrTempBufCnt 0 "BufferCnt" 1 "BufferCnt" 2 "BufferCnt" 3 "BufferCnt" 4 "RESERVED" 5 "RESERVED" 6 "RESERVED" 7 "RESERVED" ;
VAL_ 860 L_ATCU_Lib_MngrTempBufCnt 0 "BufferCnt" 1 "BufferCnt" 2 "BufferCnt" 3 "BufferCnt" 4 "BufferCnt" 5 "BufferCnt" 6 "RESERVED" 7 "RESERVED" ;
VAL_ 860 L_ATCU_Lib_MngrIntakeBufCnt 0 "BufferCnt" 1 "BufferCnt" 2 "BufferCnt" 3 "BufferCnt" 4 "BufferCnt" 5 "BufferCnt" 6 "BufferCnt" 7 "BufferCnt" 8 "BufferCnt" 9 "BufferCnt" 10 "BufferCnt" 11 "BufferCnt" 12 "BufferCnt" 13 "BufferCnt" 14 "BufferCnt" 15 "BufferCnt" 16 "BufferCnt" 17 "BufferCnt" 18 "BufferCnt" 19 "BufferCnt" 20 "BufferCnt" 21 "BufferCnt" 22 "BufferCnt" 23 "BufferCnt" 24 "BufferCnt" 25 "BufferCnt" 26 "BufferCnt" 27 "RESERVED" 28 "RESERVED" 29 "RESERVED" 30 "RESERVED" 31 "RESERVED" ;
VAL_ 913 L_ATCU_Lib_ADSBlrVtgVal 0 "0x0~0x34BC:0~13.500V" 13500 "0x0~0x34BC:0~13.500V" 13501 "34BD~0xFFFE:RESERVED" 65534 "34BD~0xFFFE:RESERVED" 65535 "None" ;
VAL_ 913 L_ATCU_Lib_ADSDEFDrState 0 "0x0~0x3E8:0~100.0%" 1000 "0x0~0x3E8:0~100.0%" 1001 "RESERVED" 1002 "RESERVED" 1003 "RESERVED" 1004 "RESERVED" 1005 "RESERVED" 1006 "RESERVED" 1007 "RESERVED" 1008 "RESERVED" 1009 "RESERVED" 1010 "RESERVED" 1011 "RESERVED" 1012 "RESERVED" 1013 "RESERVED" 1014 "RESERVED" 1015 "RESERVED" 1016 "RESERVED" 1017 "RESERVED" 1018 "RESERVED" 1019 "RESERVED" 1020 "RESERVED" 1021 "RESERVED" 1022 "RESERVED" 1023 "None" ;
VAL_ 913 L_ATCU_Lib_ADSACDispPreHoldReq 0 "Off" 1 "On" ;
VAL_ 913 L_ATCU_Lib_ADSACForcedOnReq 0 "Off" 1 "On" ;
VAL_ 913 L_ATCU_Lib_ADSACState 0 "Off" 1 "On" ;
VAL_ 913 L_ATCU_Lib_ADSInhibitPIReq 0 "Off" 1 "On" ;
VAL_ 913 L_ATCU_Lib_ADSModPrfleChgReq 0 "Off" 1 "On" ;
VAL_ 913 L_ATCU_Lib_ADSIntakeState 0 "FRE(0.0%)" 1 "1~0x3E7:Intake(0.1~99.9%)" 999 "1~0x3E7:Intake(0.1~99.9%)" 1000 "REC(100.0%)" 1001 "RESERVED" 1002 "RESERVED" 1003 "RESERVED" 1004 "RESERVED" 1005 "RESERVED" 1006 "RESERVED" 1007 "RESERVED" 1008 "RESERVED" 1009 "RESERVED" 1010 "RESERVED" 1011 "RESERVED" 1012 "RESERVED" 1013 "RESERVED" 1014 "RESERVED" 1015 "RESERVED" 1016 "RESERVED" 1017 "RESERVED" 1018 "RESERVED" 1019 "RESERVED" 1020 "RESERVED" 1021 "RESERVED" 1022 "RESERVED" 1023 "None" ;
VAL_ 913 L_ATCU_Lib_ADSTempDrLmtState 0 "0x0~0x3E8:0~100.0%" 1000 "0x0~0x3E8:0~100.0%" 1001 "RESERVED" 1002 "RESERVED" 1003 "RESERVED" 1004 "RESERVED" 1005 "RESERVED" 1006 "RESERVED" 1007 "RESERVED" 1008 "RESERVED" 1009 "RESERVED" 1010 "RESERVED" 1011 "RESERVED" 1012 "RESERVED" 1013 "RESERVED" 1014 "RESERVED" 1015 "RESERVED" 1016 "RESERVED" 1017 "RESERVED" 1018 "RESERVED" 1019 "RESERVED" 1020 "RESERVED" 1021 "RESERVED" 1022 "RESERVED" 1023 "None" ;
VAL_ 913 L_ATCU_Lib_ADSOpState 0 "Off" 1 "On" ;
VAL_ 913 L_ATCU_Lib_ADSSymState 0 "Off" 1 "On" ;
VAL_ 913 L_ATCU_Lib_ADSModState 0 "Off" 1 "Floor" 2 "Vent" 3 "BL" 4 "Def_EU" 5 "Mix" 6 "Def_Vent" 7 "All" 8 "Vent_Bleed" 9 "Floor_100" 10 "Warm_Floor" 11 "Cool_Mix" 12 "Def" 13 "RESERVED" 14 "RESERVED" 15 "None" ;
VAL_ 914 L_ATCU_Lib_PIIntakeState 0 "FRE(0.0%)" 1 "1~0x3E7:Intake(0.1~99.9%)" 999 "1~0x3E7:Intake(0.1~99.9%)" 1000 "REC(100.0%)" 1001 "RESERVED" 1002 "RESERVED" 1003 "RESERVED" 1004 "RESERVED" 1005 "RESERVED" 1006 "RESERVED" 1007 "RESERVED" 1008 "RESERVED" 1009 "RESERVED" 1010 "RESERVED" 1011 "RESERVED" 1012 "RESERVED" 1013 "RESERVED" 1014 "RESERVED" 1015 "RESERVED" 1016 "RESERVED" 1017 "RESERVED" 1018 "RESERVED" 1019 "RESERVED" 1020 "RESERVED" 1021 "RESERVED" 1022 "RESERVED" 1023 "None" ;
VAL_ 914 L_ATCU_Lib_AEWPOnReq 0 "Off" 1 "On" ;
VAL_ 914 L_ATCU_Lib_AEWPRPMVal 0 "0x0~0x2710:0~10000RPM" 10000 "0x0~0x2710:0~10000RPM" 10001 "2711~0xFFFE:RESERVED" 65534 "2711~0xFFFE:RESERVED" 65535 "None" ;
VAL_ 914 L_ATCULib_AmbFilterResetOpState 0 "Default (*)" 1 "Timer Request" 2 "Operation Request" 3 "RESERVED" ;
VAL_ 914 L_ATCULib_HVACIntlckHVActOffReq 0 "Off" 1 "On" ;
VAL_ 914 L_ATCULib_MainRlyProtectOpState 0 "Off" 1 "On" ;
VAL_ 914 L_ATCULib_ETCIntlckHVActOffReq 0 "Off" 1 "On" ;
VAL_ 914 L_ATCULib_SyncSwSta 0 "Off" 1 "SyncFrt" 2 "SyncRr" 3 "RESERVED" ;
